VERSION "STEPFOC V109"

NS_ :

BS_:

BU_: Host Driver0 Driver1 Driver2 Driver3 Driver4 Driver5 Driver6 Driver7 Driver8 Driver9 Driver10 Driver11 Driver12 Driver13

BO_ 960 Respond_data_hall_N7: 4 Driver7
 SG_ position : 7|24@0- (1,0) [-8388608|8388607] "" Host
 SG_ HALL_trigger : 31|1@0+ (1,0) [0|1] "" Host
 SG_ additional_pin2 : 30|1@0+ (1,0) [0|1] "" Host
 SG_ hall_index : 29|1@0+ (1,0) [0|1] "" Host

BO_ 961 Respond_data_hall_N7_Fault: 4 Driver7
 SG_ position : 7|24@0- (1,0) [-8388608|8388607] "" Host
 SG_ HALL_trigger : 31|1@0+ (1,0) [0|1] "" Host
 SG_ additional_pin2 : 30|1@0+ (1,0) [0|1] "" Host
 SG_ hall_index : 29|1@0+ (1,0) [0|1] "" Host

BO_ 928 Send_PD_Gains_N7: 8 Host
 SG_ KP : 7|32@0+ (1,0) [-3.402823466e+38|3.402823466e+38] "" Driver7
 SG_ KD : 39|32@0+ (1,0) [-3.402823466e+38|3.402823466e+38] "" Driver7

BO_ 930 Send_Current_Gains_N7: 8 Host
 SG_ Kp_iq : 7|32@0+ (1,0) [-3.402823466e+38|3.402823466e+38] "" Driver7
 SG_ Ki_iq : 39|32@0+ (1,0) [-3.402823466e+38|3.402823466e+38] "" Driver7

BO_ 932 Send_Velocity_Gains_N7: 8 Host
 SG_ Kpv : 7|32@0+ (1,0) [-3.402823466e+38|3.402823466e+38] "" Driver7
 SG_ Kiv : 39|32@0+ (1,0) [-3.402823466e+38|3.402823466e+38] "" Driver7

BO_ 934 Send_Position_Gains_N7: 4 Host
 SG_ Kpp : 7|32@0+ (1,0) [-3.402823466e+38|3.402823466e+38] "" Driver7

BO_ 936 Send_Limits_N7: 8 Host
 SG_ Speed_limit : 7|32@0+ (1,0) [-3.402823466e+38|3.402823466e+38] "" Driver7
 SG_ Current_limit : 39|32@0+ (1,0) [-3.402823466e+38|3.402823466e+38] "" Driver7

BO_ 940 Send_Kt_N7: 4 Host
 SG_ Kt : 7|32@0+ (1,0) [-3.402823466e+38|3.402823466e+38] "" Driver7

BO_ 964 Send_Voltage_Limit_N7: 4 Host
 SG_ Voltage_limit : 7|32@0- (1,0) [-2147483648|2147483647] "" Driver7

BO_ 916 Send_Respond_Ping_N7: 0 Driver7

BO_ 917 Send_Respond_Ping_N7_Fault: 0 Driver7

BO_ 942 Send_Respond_Temperature_N7: 2 Driver7
 SG_ temperature : 7|16@0- (1,0) [-32768|32767] "" Host

BO_ 943 Send_Respond_Temperatur_N7_Fault: 2 Driver7
 SG_ temperature : 7|16@0- (1,0) [-32768|32767] "" Host

BO_ 944 Send_Respond_Voltage_N7: 2 Driver7
 SG_ voltage : 7|16@0+ (1,0) [0|65535] "" Host

BO_ 945 Send_Respond_Voltage_N7_Fault: 2 Driver7
 SG_ voltage : 7|16@0+ (1,0) [0|65535] "" Host

BO_ 946 Send_Respond_Device_Info_N7: 7 Driver7
 SG_ HARDWARE_VERSION : 7|8@0+ (1,0) [0|255] "" Host
 SG_ BATCH_DATE : 15|8@0+ (1,0) [0|255] "" Host
 SG_ SOFTWARE_VERSION : 23|8@0+ (1,0) [0|255] "" Host
 SG_ SERIAL_NUMBER : 31|32@0+ (1,0) [0|4294967295] "" Host

BO_ 947 Send_Respond_Device_Inf_N7_Fault: 7 Driver7
 SG_ HARDWARE_VERSION : 7|8@0+ (1,0) [0|255] "" Host
 SG_ BATCH_DATE : 15|8@0+ (1,0) [0|255] "" Host
 SG_ SOFTWARE_VERSION : 23|8@0+ (1,0) [0|255] "" Host
 SG_ SERIAL_NUMBER : 31|32@0+ (1,0) [0|4294967295] "" Host

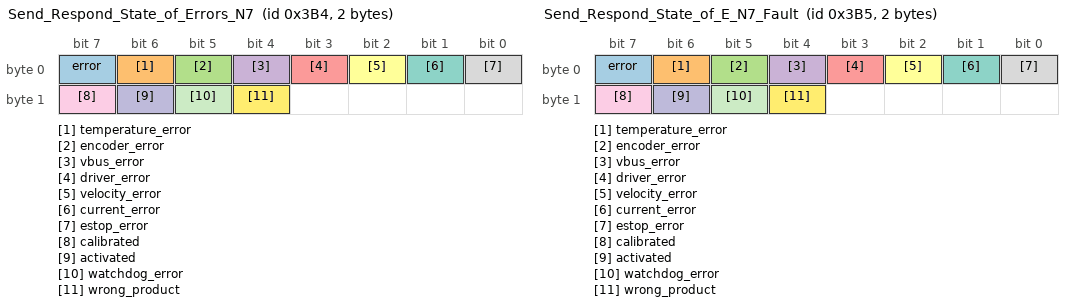
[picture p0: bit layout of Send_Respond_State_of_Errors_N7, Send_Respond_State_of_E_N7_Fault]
BO_ 948 Send_Respond_State_of_Errors_N7: 2 Driver7
 SG_ error : 7|1@0+ (1,0) [0|1] "" Host
 SG_ temperature_error : 6|1@0+ (1,0) [0|1] "" Host
 SG_ encoder_error : 5|1@0+ (1,0) [0|1] "" Host
 SG_ vbus_error : 4|1@0+ (1,0) [0|1] "" Host
 SG_ driver_error : 3|1@0+ (1,0) [0|1] "" Host
 SG_ velocity_error : 2|1@0+ (1,0) [0|1] "" Host
 SG_ current_error : 1|1@0+ (1,0) [0|1] "" Host
 SG_ estop_error : 0|1@0+ (1,0) [0|1] "" Host
 SG_ calibrated : 15|1@0+ (1,0) [0|1] "" Host
 SG_ activated : 14|1@0+ (1,0) [0|1] "" Host
 SG_ watchdog_error : 13|1@0+ (1,0) [0|1] "" Host
 SG_ wrong_product : 12|1@0+ (1,0) [0|1] "" Host

BO_ 949 Send_Respond_State_of_E_N7_Fault: 2 Driver7
 SG_ error : 7|1@0+ (1,0) [0|1] "" Host
 SG_ temperature_error : 6|1@0+ (1,0) [0|1] "" Host
 SG_ encoder_error : 5|1@0+ (1,0) [0|1] "" Host
 SG_ vbus_error : 4|1@0+ (1,0) [0|1] "" Host
 SG_ driver_error : 3|1@0+ (1,0) [0|1] "" Host
 SG_ velocity_error : 2|1@0+ (1,0) [0|1] "" Host
 SG_ current_error : 1|1@0+ (1,0) [0|1] "" Host
 SG_ estop_error : 0|1@0+ (1,0) [0|1] "" Host
 SG_ calibrated : 15|1@0+ (1,0) [0|1] "" Host
 SG_ activated : 14|1@0+ (1,0) [0|1] "" Host
 SG_ watchdog_error : 13|1@0+ (1,0) [0|1] "" Host
 SG_ wrong_product : 12|1@0+ (1,0) [0|1] "" Host

BO_ 950 Send_Respond_Iq_data_N7: 2 Driver7
 SG_ current : 7|16@0- (1,0) [-32768|32767] "" Host

BO_ 951 Send_Respond_Iq_data_N7_Fault: 2 Driver7
 SG_ current : 7|16@0- (1,0) [-32768|32767] "" Host

BO_ 952 Send_Respond_Encoder_data_N7: 8 Driver7
 SG_ position : 7|32@0- (1,0) [-2147483648|2147483647] "" Host
 SG_ speed : 39|32@0- (1,0) [-2147483648|2147483647] "" Host

BO_ 953 Send_Respond_Encoder_da_N7_Fault: 8 Driver7
 SG_ position : 7|32@0- (1,0) [-2147483648|2147483647] "" Host
 SG_ speed : 39|32@0- (1,0) [-2147483648|2147483647] "" Host

BO_ 962 Send_Respond_Kt_N7: 4 Driver7
 SG_ Kt : 7|32@0+ (1,0) [-3.402823466e+38|3.402823466e+38] "" Host

BO_ 963 Send_Respond_Kt_N7_Fault: 4 Driver7
 SG_ Kt : 7|32@0+ (1,0) [-3.402823466e+38|3.402823466e+38] "" Host

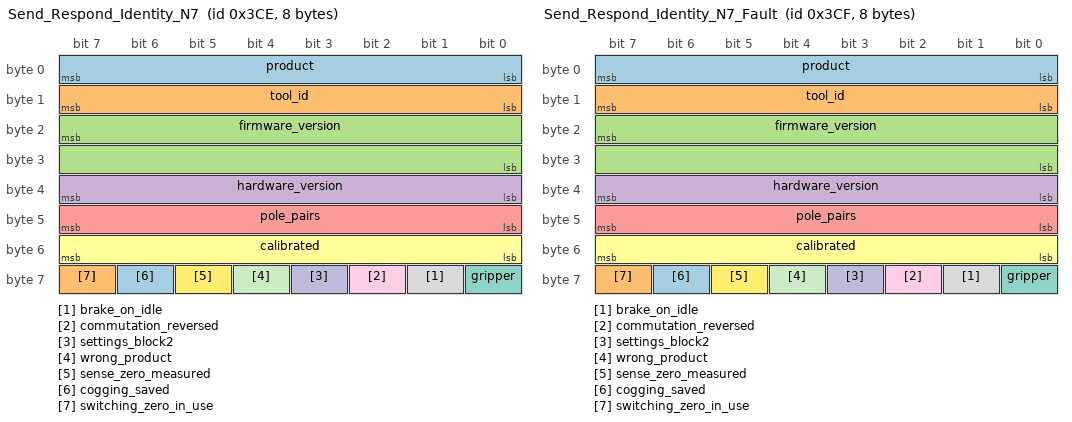
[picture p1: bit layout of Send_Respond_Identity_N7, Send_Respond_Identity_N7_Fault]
BO_ 974 Send_Respond_Identity_N7: 8 Driver7
 SG_ product : 7|8@0+ (1,0) [0|255] "" Host
 SG_ tool_id : 15|8@0+ (1,0) [0|255] "" Host
 SG_ firmware_version : 23|16@0+ (1,0) [0|65535] "" Host
 SG_ hardware_version : 39|8@0+ (1,0) [0|255] "" Host
 SG_ pole_pairs : 47|8@0+ (1,0) [0|255] "" Host
 SG_ calibrated : 55|8@0+ (1,0) [0|255] "" Host
 SG_ gripper : 56|1@0+ (1,0) [0|1] "" Host
 SG_ brake_on_idle : 57|1@0+ (1,0) [0|1] "" Host
 SG_ commutation_reversed : 58|1@0+ (1,0) [0|1] "" Host
 SG_ settings_block2 : 59|1@0+ (1,0) [0|1] "" Host
 SG_ wrong_product : 60|1@0+ (1,0) [0|1] "" Host
 SG_ sense_zero_measured : 61|1@0+ (1,0) [0|1] "" Host
 SG_ cogging_saved : 62|1@0+ (1,0) [0|1] "" Host
 SG_ switching_zero_in_use : 63|1@0+ (1,0) [0|1] "" Host

BO_ 975 Send_Respond_Identity_N7_Fault: 8 Driver7
 SG_ product : 7|8@0+ (1,0) [0|255] "" Host
 SG_ tool_id : 15|8@0+ (1,0) [0|255] "" Host
 SG_ firmware_version : 23|16@0+ (1,0) [0|65535] "" Host
 SG_ hardware_version : 39|8@0+ (1,0) [0|255] "" Host
 SG_ pole_pairs : 47|8@0+ (1,0) [0|255] "" Host
 SG_ calibrated : 55|8@0+ (1,0) [0|255] "" Host
 SG_ gripper : 56|1@0+ (1,0) [0|1] "" Host
 SG_ brake_on_idle : 57|1@0+ (1,0) [0|1] "" Host
 SG_ commutation_reversed : 58|1@0+ (1,0) [0|1] "" Host
 SG_ settings_block2 : 59|1@0+ (1,0) [0|1] "" Host
 SG_ wrong_product : 60|1@0+ (1,0) [0|1] "" Host
 SG_ sense_zero_measured : 61|1@0+ (1,0) [0|1] "" Host
 SG_ cogging_saved : 62|1@0+ (1,0) [0|1] "" Host
 SG_ switching_zero_in_use : 63|1@0+ (1,0) [0|1] "" Host

BO_ 976 Send_Respond_Telemetry_N7: 8 Driver7
 SG_ temperature : 7|16@0- (1,0) [-32768|32767] "" Host
 SG_ voltage : 23|16@0- (1,0) [-32768|32767] "" Host
 SG_ errors_1 : 39|8@0+ (1,0) [0|255] "" Host
 SG_ errors_2 : 47|8@0+ (1,0) [0|255] "" Host
 SG_ current : 55|16@0- (1,0) [-32768|32767] "" Host

BO_ 977 Send_Respond_Telemetry_N7_Fault: 8 Driver7
 SG_ temperature : 7|16@0- (1,0) [-32768|32767] "" Host
 SG_ voltage : 23|16@0- (1,0) [-32768|32767] "" Host
 SG_ errors_1 : 39|8@0+ (1,0) [0|255] "" Host
 SG_ errors_2 : 47|8@0+ (1,0) [0|255] "" Host
 SG_ current : 55|16@0- (1,0) [-32768|32767] "" Host

BO_ 914 Respond_Heartbeat_N7: 0 Driver7

BO_ 915 Respond_Heartbeat_N7_Fault: 0 Driver7

BO_ 918 Send_CAN_ID_N7: 1 Host
 SG_ ID : 7|8@0+ (1,0) [0|255] "" Driver7

BO_ 896 Send_ESTOP_N7: 0 Host

BO_ 920 Send_Idle_N7: 0 Host

BO_ 922 Send_Save_config_N7: 0 Host

BO_ 924 Send_Reset_N7: 0 Host

BO_ 898 Send_Clear_Error_N7: 0 Host

BO_ 926 Send_Watchdog_N7: 5 Host
 SG_ Time : 7|32@0+ (1,0) [0|4294967295] "" Driver7
 SG_ Action : 39|8@0+ (1,0) [0|255] "" Driver7

BO_ 956 Send_Heartbeat_Setup_N7: 4 Host
 SG_ Interval : 7|32@0+ (1,0) [0|4294967295] "" Driver7

BO_ 966 Send_Settings_N7: 2 Host
 SG_ Mask : 7|8@0+ (1,0) [0|255] "" Driver7
 SG_ Value : 15|8@0+ (1,0) [0|255] "" Driver7

BO_ 968 Send_Parameter_N7: 5 Host
 SG_ Parameter : 7|8@0+ (1,0) [0|255] "" Driver7
 SG_ Value : 15|32@0- (1,0) [-2147483648|2147483647] "" Driver7

BO_ 970 Send_Get_Parameter_N7: 1 Host
 SG_ Parameter : 7|8@0+ (1,0) [0|255] "" Driver7

BO_ 972 Respond_Parameter_N7: 5 Driver7
 SG_ parameter : 7|8@0+ (1,0) [0|255] "" Host
 SG_ value : 15|32@0- (1,0) [-2147483648|2147483647] "" Host

BO_ 973 Respond_Parameter_N7_Fault: 5 Driver7
 SG_ parameter : 7|8@0+ (1,0) [0|255] "" Host
 SG_ value : 15|32@0- (1,0) [-2147483648|2147483647] "" Host

BO_ 978 Send_Buffer_Read_N7: 5 Host
 SG_ Kind : 7|8@0+ (1,0) [0|255] "" Driver7
 SG_ First : 15|16@0+ (1,0) [0|65535] "" Driver7
 SG_ Count : 31|16@0+ (1,0) [0|65535] "" Driver7

BO_ 980 Respond_Buffer_Data_N7: 8 Driver7
 SG_ header : 7|16@0+ (1,0) [0|65535] "" Host
 SG_ word_a : 23|16@0- (1,0) [-32768|32767] "" Host
 SG_ word_b : 39|16@0- (1,0) [-32768|32767] "" Host
 SG_ word_c : 55|16@0- (1,0) [-32768|32767] "" Host

BO_ 981 Respond_Buffer_Data_N7_Fault: 8 Driver7
 SG_ header : 7|16@0+ (1,0) [0|65535] "" Host
 SG_ word_a : 23|16@0- (1,0) [-32768|32767] "" Host
 SG_ word_b : 39|16@0- (1,0) [-32768|32767] "" Host
 SG_ word_c : 55|16@0- (1,0) [-32768|32767] "" Host

BO_ 982 Send_Buffer_Write_N7: 8 Host
 SG_ Header : 7|16@0+ (1,0) [0|65535] "" Driver7
 SG_ Word_A : 23|16@0- (1,0) [-32768|32767] "" Driver7
 SG_ Word_B : 39|16@0- (1,0) [-32768|32767] "" Driver7
 SG_ Word_C : 55|16@0- (1,0) [-32768|32767] "" Driver7

BO_ 984 Send_Sound_N7: 8 Host
 SG_ Operation : 7|8@0+ (1,0) [0|255] "" Driver7
 SG_ Channel : 15|8@0+ (1,0) [0|255] "" Driver7
 SG_ A : 23|16@0+ (1,0) [0|65535] "" Driver7
 SG_ B : 39|16@0+ (1,0) [0|65535] "" Driver7
 SG_ C : 55|16@0+ (1,0) [0|65535] "" Driver7

BO_ 986 Send_Sound_Samples_N7: 8 Host
 SG_ Sample_1 : 7|8@0- (1,0) [-128|127] "" Driver7
 SG_ Sample_2 : 15|8@0- (1,0) [-128|127] "" Driver7
 SG_ Sample_3 : 23|8@0- (1,0) [-128|127] "" Driver7
 SG_ Sample_4 : 31|8@0- (1,0) [-128|127] "" Driver7
 SG_ Sample_5 : 39|8@0- (1,0) [-128|127] "" Driver7
 SG_ Sample_6 : 47|8@0- (1,0) [-128|127] "" Driver7
 SG_ Sample_7 : 55|8@0- (1,0) [-128|127] "" Driver7
 SG_ Sample_8 : 63|8@0- (1,0) [-128|127] "" Driver7

BO_ 1018 Send_gripper_data_pack_N7: 5 Host
 SG_ Position : 7|8@0+ (1,0) [0|255] "" Driver7
 SG_ Speed : 15|8@0+ (1,0) [0|255] "" Driver7
 SG_ Current : 23|16@0- (1,0) [-32768|32767] "" Driver7
 SG_ Activate : 39|1@0+ (1,0) [0|1] "" Driver7
 SG_ Action : 38|1@0+ (1,0) [0|1] "" Driver7
 SG_ E_stop : 37|1@0+ (1,0) [0|1] "" Driver7
 SG_ Release_direction : 36|1@0+ (1,0) [0|1] "" Driver7

BO_ 1020 Send_gripper_calibrate_N7: 0 Host

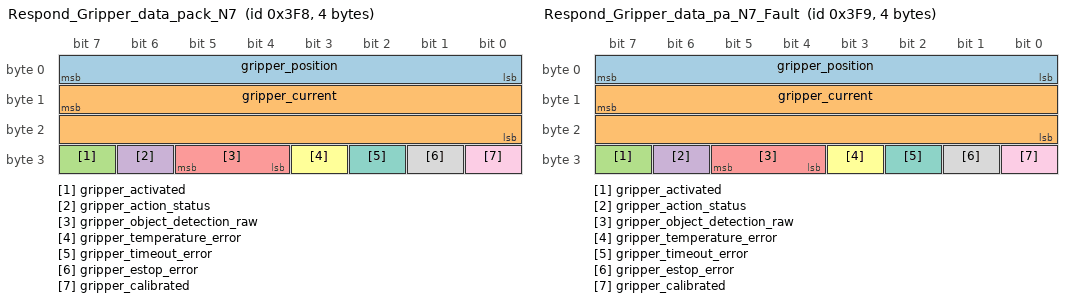
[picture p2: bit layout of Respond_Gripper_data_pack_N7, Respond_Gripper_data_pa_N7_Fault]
BO_ 1016 Respond_Gripper_data_pack_N7: 4 Driver7
 SG_ gripper_position : 7|8@0+ (1,0) [0|255] "" Host
 SG_ gripper_current : 15|16@0- (1,0) [-32768|32767] "" Host
 SG_ gripper_activated : 31|1@0+ (1,0) [0|1] "" Host
 SG_ gripper_action_status : 30|1@0+ (1,0) [0|1] "" Host
 SG_ gripper_object_detection_raw : 29|2@0+ (1,0) [0|3] "" Host
 SG_ gripper_temperature_error : 27|1@0+ (1,0) [0|1] "" Host
 SG_ gripper_timeout_error : 26|1@0+ (1,0) [0|1] "" Host
 SG_ gripper_estop_error : 25|1@0+ (1,0) [0|1] "" Host
 SG_ gripper_calibrated : 24|1@0+ (1,0) [0|1] "" Host

BO_ 1017 Respond_Gripper_data_pa_N7_Fault: 4 Driver7
 SG_ gripper_position : 7|8@0+ (1,0) [0|255] "" Host
 SG_ gripper_current : 15|16@0- (1,0) [-32768|32767] "" Host
 SG_ gripper_activated : 31|1@0+ (1,0) [0|1] "" Host
 SG_ gripper_action_status : 30|1@0+ (1,0) [0|1] "" Host
 SG_ gripper_object_detection_raw : 29|2@0+ (1,0) [0|3] "" Host
 SG_ gripper_temperature_error : 27|1@0+ (1,0) [0|1] "" Host
 SG_ gripper_timeout_error : 26|1@0+ (1,0) [0|1] "" Host
 SG_ gripper_estop_error : 25|1@0+ (1,0) [0|1] "" Host
 SG_ gripper_calibrated : 24|1@0+ (1,0) [0|1] "" Host

BO_ 1028 Send_data_pack_1_N8: 5 Host
 SG_ Speed_setpoint : 7|24@0- (1,0) [-8388608|8388607] "" Driver8
 SG_ Current_feedforward : 31|16@0- (1,0) [-32768|32767] "" Driver8

BO_ 1032 Send_data_pack_PD_N8: 8 Host
 SG_ Position_setpoint : 7|24@0- (1,0) [-8388608|8388607] "" Driver8
 SG_ Speed_setpoint : 31|24@0- (1,0) [-8388608|8388607] "" Driver8
 SG_ Current_feedforward : 55|16@0- (1,0) [-32768|32767] "" Driver8

BO_ 1086 Send_data_pack_HALL_N8: 4 Host
 SG_ Speed : 7|24@0- (1,0) [-8388608|8388607] "" Driver8
 SG_ Trigger : 31|8@0+ (1,0) [0|255] "" Driver8

BO_ 1030 Respond_data_pack_1_N8: 8 Driver8
 SG_ position : 7|24@0- (1,0) [-8388608|8388607] "" Host
 SG_ speed : 31|24@0- (1,0) [-8388608|8388607] "" Host
 SG_ current : 55|16@0- (1,0) [-32768|32767] "" Host

BO_ 1031 Respond_data_pack_1_N8_Fault: 8 Driver8
 SG_ position : 7|24@0- (1,0) [-8388608|8388607] "" Host
 SG_ speed : 31|24@0- (1,0) [-8388608|8388607] "" Host
 SG_ current : 55|16@0- (1,0) [-32768|32767] "" Host

BO_ 1088 Respond_data_hall_N8: 4 Driver8
 SG_ position : 7|24@0- (1,0) [-8388608|8388607] "" Host
 SG_ HALL_trigger : 31|1@0+ (1,0) [0|1] "" Host
 SG_ additional_pin2 : 30|1@0+ (1,0) [0|1] "" Host
 SG_ hall_index : 29|1@0+ (1,0) [0|1] "" Host

BO_ 1089 Respond_data_hall_N8_Fault: 4 Driver8
 SG_ position : 7|24@0- (1,0) [-8388608|8388607] "" Host
 SG_ HALL_trigger : 31|1@0+ (1,0) [0|1] "" Host
 SG_ additional_pin2 : 30|1@0+ (1,0) [0|1] "" Host
 SG_ hall_index : 29|1@0+ (1,0) [0|1] "" Host

BO_ 1056 Send_PD_Gains_N8: 8 Host
 SG_ KP : 7|32@0+ (1,0) [-3.402823466e+38|3.402823466e+38] "" Driver8
 SG_ KD : 39|32@0+ (1,0) [-3.402823466e+38|3.402823466e+38] "" Driver8

BO_ 1058 Send_Current_Gains_N8: 8 Host
 SG_ Kp_iq : 7|32@0+ (1,0) [-3.402823466e+38|3.402823466e+38] "" Driver8
 SG_ Ki_iq : 39|32@0+ (1,0) [-3.402823466e+38|3.402823466e+38] "" Driver8

BO_ 1060 Send_Velocity_Gains_N8: 8 Host
 SG_ Kpv : 7|32@0+ (1,0) [-3.402823466e+38|3.402823466e+38] "" Driver8
 SG_ Kiv : 39|32@0+ (1,0) [-3.402823466e+38|3.402823466e+38] "" Driver8

BO_ 1062 Send_Position_Gains_N8: 4 Host
 SG_ Kpp : 7|32@0+ (1,0) [-3.402823466e+38|3.402823466e+38] "" Driver8

BO_ 1064 Send_Limits_N8: 8 Host
 SG_ Speed_limit : 7|32@0+ (1,0) [-3.402823466e+38|3.402823466e+38] "" Driver8
 SG_ Current_limit : 39|32@0+ (1,0) [-3.402823466e+38|3.402823466e+38] "" Driver8

BO_ 1068 Send_Kt_N8: 4 Host
 SG_ Kt : 7|32@0+ (1,0) [-3.402823466e+38|3.402823466e+38] "" Driver8

BO_ 1092 Send_Voltage_Limit_N8: 4 Host
 SG_ Voltage_limit : 7|32@0- (1,0) [-2147483648|2147483647] "" Driver8

BO_ 1044 Send_Respond_Ping_N8: 0 Driver8

BO_ 1045 Send_Respond_Ping_N8_Fault: 0 Driver8

BO_ 1070 Send_Respond_Temperature_N8: 2 Driver8
 SG_ temperature : 7|16@0- (1,0) [-32768|32767] "" Host

BO_ 1071 Send_Respond_Temperatur_N8_Fault: 2 Driver8
 SG_ temperature : 7|16@0- (1,0) [-32768|32767] "" Host

BO_ 1072 Send_Respond_Voltage_N8: 2 Driver8
 SG_ voltage : 7|16@0+ (1,0) [0|65535] "" Host

BO_ 1073 Send_Respond_Voltage_N8_Fault: 2 Driver8
 SG_ voltage : 7|16@0+ (1,0) [0|65535] "" Host

BO_ 1074 Send_Respond_Device_Info_N8: 7 Driver8
 SG_ HARDWARE_VERSION : 7|8@0+ (1,0) [0|255] "" Host
 SG_ BATCH_DATE : 15|8@0+ (1,0) [0|255] "" Host
 SG_ SOFTWARE_VERSION : 23|8@0+ (1,0) [0|255] "" Host
 SG_ SERIAL_NUMBER : 31|32@0+ (1,0) [0|4294967295] "" Host

BO_ 1075 Send_Respond_Device_Inf_N8_Fault: 7 Driver8
 SG_ HARDWARE_VERSION : 7|8@0+ (1,0) [0|255] "" Host
 SG_ BATCH_DATE : 15|8@0+ (1,0) [0|255] "" Host
 SG_ SOFTWARE_VERSION : 23|8@0+ (1,0) [0|255] "" Host
 SG_ SERIAL_NUMBER : 31|32@0+ (1,0) [0|4294967295] "" Host

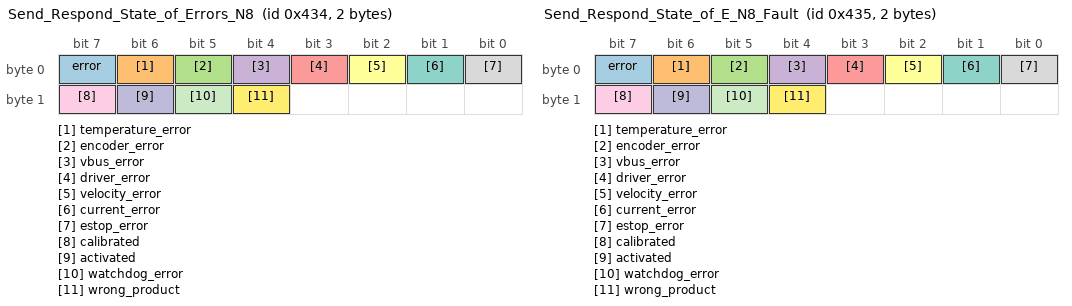
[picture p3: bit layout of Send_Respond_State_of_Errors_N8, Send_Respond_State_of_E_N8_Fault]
BO_ 1076 Send_Respond_State_of_Errors_N8: 2 Driver8
 SG_ error : 7|1@0+ (1,0) [0|1] "" Host
 SG_ temperature_error : 6|1@0+ (1,0) [0|1] "" Host
 SG_ encoder_error : 5|1@0+ (1,0) [0|1] "" Host
 SG_ vbus_error : 4|1@0+ (1,0) [0|1] "" Host
 SG_ driver_error : 3|1@0+ (1,0) [0|1] "" Host
 SG_ velocity_error : 2|1@0+ (1,0) [0|1] "" Host
 SG_ current_error : 1|1@0+ (1,0) [0|1] "" Host
 SG_ estop_error : 0|1@0+ (1,0) [0|1] "" Host
 SG_ calibrated : 15|1@0+ (1,0) [0|1] "" Host
 SG_ activated : 14|1@0+ (1,0) [0|1] "" Host
 SG_ watchdog_error : 13|1@0+ (1,0) [0|1] "" Host
 SG_ wrong_product : 12|1@0+ (1,0) [0|1] "" Host

BO_ 1077 Send_Respond_State_of_E_N8_Fault: 2 Driver8
 SG_ error : 7|1@0+ (1,0) [0|1] "" Host
 SG_ temperature_error : 6|1@0+ (1,0) [0|1] "" Host
 SG_ encoder_error : 5|1@0+ (1,0) [0|1] "" Host
 SG_ vbus_error : 4|1@0+ (1,0) [0|1] "" Host
 SG_ driver_error : 3|1@0+ (1,0) [0|1] "" Host
 SG_ velocity_error : 2|1@0+ (1,0) [0|1] "" Host
 SG_ current_error : 1|1@0+ (1,0) [0|1] "" Host
 SG_ estop_error : 0|1@0+ (1,0) [0|1] "" Host
 SG_ calibrated : 15|1@0+ (1,0) [0|1] "" Host
 SG_ activated : 14|1@0+ (1,0) [0|1] "" Host
 SG_ watchdog_error : 13|1@0+ (1,0) [0|1] "" Host
 SG_ wrong_product : 12|1@0+ (1,0) [0|1] "" Host

BO_ 1078 Send_Respond_Iq_data_N8: 2 Driver8
 SG_ current : 7|16@0- (1,0) [-32768|32767] "" Host

BO_ 1079 Send_Respond_Iq_data_N8_Fault: 2 Driver8
 SG_ current : 7|16@0- (1,0) [-32768|32767] "" Host

BO_ 1080 Send_Respond_Encoder_data_N8: 8 Driver8
 SG_ position : 7|32@0- (1,0) [-2147483648|2147483647] "" Host
 SG_ speed : 39|32@0- (1,0) [-2147483648|2147483647] "" Host

BO_ 1081 Send_Respond_Encoder_da_N8_Fault: 8 Driver8
 SG_ position : 7|32@0- (1,0) [-2147483648|2147483647] "" Host
 SG_ speed : 39|32@0- (1,0) [-2147483648|2147483647] "" Host

BO_ 1090 Send_Respond_Kt_N8: 4 Driver8
 SG_ Kt : 7|32@0+ (1,0) [-3.402823466e+38|3.402823466e+38] "" Host

BO_ 1091 Send_Respond_Kt_N8_Fault: 4 Driver8
 SG_ Kt : 7|32@0+ (1,0) [-3.402823466e+38|3.402823466e+38] "" Host

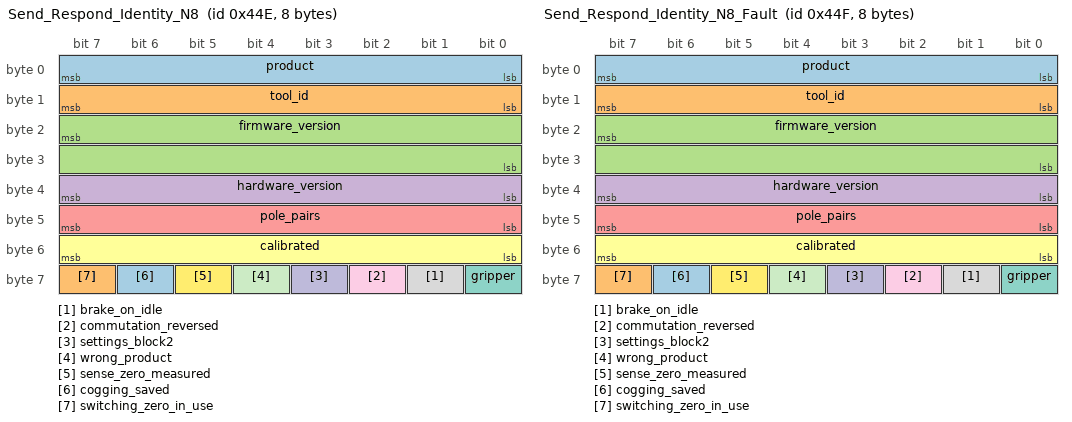
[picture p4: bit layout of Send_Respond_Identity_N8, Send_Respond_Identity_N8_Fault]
BO_ 1102 Send_Respond_Identity_N8: 8 Driver8
 SG_ product : 7|8@0+ (1,0) [0|255] "" Host
 SG_ tool_id : 15|8@0+ (1,0) [0|255] "" Host
 SG_ firmware_version : 23|16@0+ (1,0) [0|65535] "" Host
 SG_ hardware_version : 39|8@0+ (1,0) [0|255] "" Host
 SG_ pole_pairs : 47|8@0+ (1,0) [0|255] "" Host
 SG_ calibrated : 55|8@0+ (1,0) [0|255] "" Host
 SG_ gripper : 56|1@0+ (1,0) [0|1] "" Host
 SG_ brake_on_idle : 57|1@0+ (1,0) [0|1] "" Host
 SG_ commutation_reversed : 58|1@0+ (1,0) [0|1] "" Host
 SG_ settings_block2 : 59|1@0+ (1,0) [0|1] "" Host
 SG_ wrong_product : 60|1@0+ (1,0) [0|1] "" Host
 SG_ sense_zero_measured : 61|1@0+ (1,0) [0|1] "" Host
 SG_ cogging_saved : 62|1@0+ (1,0) [0|1] "" Host
 SG_ switching_zero_in_use : 63|1@0+ (1,0) [0|1] "" Host

BO_ 1103 Send_Respond_Identity_N8_Fault: 8 Driver8
 SG_ product : 7|8@0+ (1,0) [0|255] "" Host
 SG_ tool_id : 15|8@0+ (1,0) [0|255] "" Host
 SG_ firmware_version : 23|16@0+ (1,0) [0|65535] "" Host
 SG_ hardware_version : 39|8@0+ (1,0) [0|255] "" Host
 SG_ pole_pairs : 47|8@0+ (1,0) [0|255] "" Host
 SG_ calibrated : 55|8@0+ (1,0) [0|255] "" Host
 SG_ gripper : 56|1@0+ (1,0) [0|1] "" Host
 SG_ brake_on_idle : 57|1@0+ (1,0) [0|1] "" Host
 SG_ commutation_reversed : 58|1@0+ (1,0) [0|1] "" Host
 SG_ settings_block2 : 59|1@0+ (1,0) [0|1] "" Host
 SG_ wrong_product : 60|1@0+ (1,0) [0|1] "" Host
 SG_ sense_zero_measured : 61|1@0+ (1,0) [0|1] "" Host
 SG_ cogging_saved : 62|1@0+ (1,0) [0|1] "" Host
 SG_ switching_zero_in_use : 63|1@0+ (1,0) [0|1] "" Host

BO_ 1104 Send_Respond_Telemetry_N8: 8 Driver8
 SG_ temperature : 7|16@0- (1,0) [-32768|32767] "" Host
 SG_ voltage : 23|16@0- (1,0) [-32768|32767] "" Host
 SG_ errors_1 : 39|8@0+ (1,0) [0|255] "" Host
 SG_ errors_2 : 47|8@0+ (1,0) [0|255] "" Host
 SG_ current : 55|16@0- (1,0) [-32768|32767] "" Host

BO_ 1105 Send_Respond_Telemetry_N8_Fault: 8 Driver8
 SG_ temperature : 7|16@0- (1,0) [-32768|32767] "" Host
 SG_ voltage : 23|16@0- (1,0) [-32768|32767] "" Host
 SG_ errors_1 : 39|8@0+ (1,0) [0|255] "" Host
 SG_ errors_2 : 47|8@0+ (1,0) [0|255] "" Host
 SG_ current : 55|16@0- (1,0) [-32768|32767] "" Host

BO_ 1042 Respond_Heartbeat_N8: 0 Driver8

BO_ 1043 Respond_Heartbeat_N8_Fault: 0 Driver8

BO_ 1046 Send_CAN_ID_N8: 1 Host
 SG_ ID : 7|8@0+ (1,0) [0|255] "" Driver8

BO_ 1024 Send_ESTOP_N8: 0 Host

BO_ 1048 Send_Idle_N8: 0 Host

BO_ 1050 Send_Save_config_N8: 0 Host

BO_ 1052 Send_Reset_N8: 0 Host

BO_ 1026 Send_Clear_Error_N8: 0 Host

BO_ 1054 Send_Watchdog_N8: 5 Host
 SG_ Time : 7|32@0+ (1,0) [0|4294967295] "" Driver8
 SG_ Action : 39|8@0+ (1,0) [0|255] "" Driver8

BO_ 1084 Send_Heartbeat_Setup_N8: 4 Host
 SG_ Interval : 7|32@0+ (1,0) [0|4294967295] "" Driver8

BO_ 1094 Send_Settings_N8: 2 Host
 SG_ Mask : 7|8@0+ (1,0) [0|255] "" Driver8
 SG_ Value : 15|8@0+ (1,0) [0|255] "" Driver8

BO_ 1096 Send_Parameter_N8: 5 Host
 SG_ Parameter : 7|8@0+ (1,0) [0|255] "" Driver8
 SG_ Value : 15|32@0- (1,0) [-2147483648|2147483647] "" Driver8

BO_ 1098 Send_Get_Parameter_N8: 1 Host
 SG_ Parameter : 7|8@0+ (1,0) [0|255] "" Driver8

BO_ 1100 Respond_Parameter_N8: 5 Driver8
 SG_ parameter : 7|8@0+ (1,0) [0|255] "" Host
 SG_ value : 15|32@0- (1,0) [-2147483648|2147483647] "" Host

BO_ 1101 Respond_Parameter_N8_Fault: 5 Driver8
 SG_ parameter : 7|8@0+ (1,0) [0|255] "" Host
 SG_ value : 15|32@0- (1,0) [-2147483648|2147483647] "" Host

BO_ 1106 Send_Buffer_Read_N8: 5 Host
 SG_ Kind : 7|8@0+ (1,0) [0|255] "" Driver8
 SG_ First : 15|16@0+ (1,0) [0|65535] "" Driver8
 SG_ Count : 31|16@0+ (1,0) [0|65535] "" Driver8

BO_ 1108 Respond_Buffer_Data_N8: 8 Driver8
 SG_ header : 7|16@0+ (1,0) [0|65535] "" Host
 SG_ word_a : 23|16@0- (1,0) [-32768|32767] "" Host
 SG_ word_b : 39|16@0- (1,0) [-32768|32767] "" Host
 SG_ word_c : 55|16@0- (1,0) [-32768|32767] "" Host

BO_ 1109 Respond_Buffer_Data_N8_Fault: 8 Driver8
 SG_ header : 7|16@0+ (1,0) [0|65535] "" Host
 SG_ word_a : 23|16@0- (1,0) [-32768|32767] "" Host
 SG_ word_b : 39|16@0- (1,0) [-32768|32767] "" Host
 SG_ word_c : 55|16@0- (1,0) [-32768|32767] "" Host

BO_ 1110 Send_Buffer_Write_N8: 8 Host
 SG_ Header : 7|16@0+ (1,0) [0|65535] "" Driver8
 SG_ Word_A : 23|16@0- (1,0) [-32768|32767] "" Driver8
 SG_ Word_B : 39|16@0- (1,0) [-32768|32767] "" Driver8
 SG_ Word_C : 55|16@0- (1,0) [-32768|32767] "" Driver8

BO_ 1112 Send_Sound_N8: 8 Host
 SG_ Operation : 7|8@0+ (1,0) [0|255] "" Driver8
 SG_ Channel : 15|8@0+ (1,0) [0|255] "" Driver8
 SG_ A : 23|16@0+ (1,0) [0|65535] "" Driver8
 SG_ B : 39|16@0+ (1,0) [0|65535] "" Driver8
 SG_ C : 55|16@0+ (1,0) [0|65535] "" Driver8

BO_ 1114 Send_Sound_Samples_N8: 8 Host
 SG_ Sample_1 : 7|8@0- (1,0) [-128|127] "" Driver8
 SG_ Sample_2 : 15|8@0- (1,0) [-128|127] "" Driver8
 SG_ Sample_3 : 23|8@0- (1,0) [-128|127] "" Driver8
 SG_ Sample_4 : 31|8@0- (1,0) [-128|127] "" Driver8
 SG_ Sample_5 : 39|8@0- (1,0) [-128|127] "" Driver8
 SG_ Sample_6 : 47|8@0- (1,0) [-128|127] "" Driver8
 SG_ Sample_7 : 55|8@0- (1,0) [-128|127] "" Driver8
 SG_ Sample_8 : 63|8@0- (1,0) [-128|127] "" Driver8

BO_ 1146 Send_gripper_data_pack_N8: 5 Host
 SG_ Position : 7|8@0+ (1,0) [0|255] "" Driver8
 SG_ Speed : 15|8@0+ (1,0) [0|255] "" Driver8
 SG_ Current : 23|16@0- (1,0) [-32768|32767] "" Driver8
 SG_ Activate : 39|1@0+ (1,0) [0|1] "" Driver8
 SG_ Action : 38|1@0+ (1,0) [0|1] "" Driver8
 SG_ E_stop : 37|1@0+ (1,0) [0|1] "" Driver8
 SG_ Release_direction : 36|1@0+ (1,0) [0|1] "" Driver8

BO_ 1148 Send_gripper_calibrate_N8: 0 Host

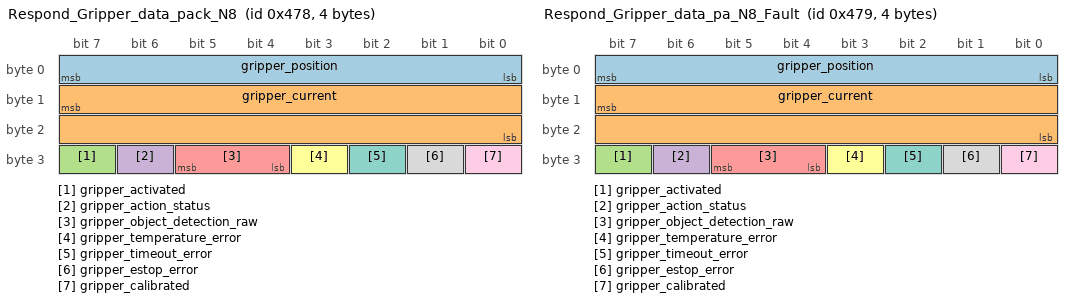
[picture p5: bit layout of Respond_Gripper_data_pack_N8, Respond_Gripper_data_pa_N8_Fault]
BO_ 1144 Respond_Gripper_data_pack_N8: 4 Driver8
 SG_ gripper_position : 7|8@0+ (1,0) [0|255] "" Host
 SG_ gripper_current : 15|16@0- (1,0) [-32768|32767] "" Host
 SG_ gripper_activated : 31|1@0+ (1,0) [0|1] "" Host
 SG_ gripper_action_status : 30|1@0+ (1,0) [0|1] "" Host
 SG_ gripper_object_detection_raw : 29|2@0+ (1,0) [0|3] "" Host
 SG_ gripper_temperature_error : 27|1@0+ (1,0) [0|1] "" Host
 SG_ gripper_timeout_error : 26|1@0+ (1,0) [0|1] "" Host
 SG_ gripper_estop_error : 25|1@0+ (1,0) [0|1] "" Host
 SG_ gripper_calibrated : 24|1@0+ (1,0) [0|1] "" Host

BO_ 1145 Respond_Gripper_data_pa_N8_Fault: 4 Driver8
 SG_ gripper_position : 7|8@0+ (1,0) [0|255] "" Host
 SG_ gripper_current : 15|16@0- (1,0) [-32768|32767] "" Host
 SG_ gripper_activated : 31|1@0+ (1,0) [0|1] "" Host
 SG_ gripper_action_status : 30|1@0+ (1,0) [0|1] "" Host
 SG_ gripper_object_detection_raw : 29|2@0+ (1,0) [0|3] "" Host
 SG_ gripper_temperature_error : 27|1@0+ (1,0) [0|1] "" Host
 SG_ gripper_timeout_error : 26|1@0+ (1,0) [0|1] "" Host
 SG_ gripper_estop_error : 25|1@0+ (1,0) [0|1] "" Host
 SG_ gripper_calibrated : 24|1@0+ (1,0) [0|1] "" Host

BO_ 1156 Send_data_pack_1_N9: 5 Host
 SG_ Speed_setpoint : 7|24@0- (1,0) [-8388608|8388607] "" Driver9
 SG_ Current_feedforward : 31|16@0- (1,0) [-32768|32767] "" Driver9

BO_ 1160 Send_data_pack_PD_N9: 8 Host
 SG_ Position_setpoint : 7|24@0- (1,0) [-8388608|8388607] "" Driver9
 SG_ Speed_setpoint : 31|24@0- (1,0) [-8388608|8388607] "" Driver9
 SG_ Current_feedforward : 55|16@0- (1,0) [-32768|32767] "" Driver9

BO_ 1214 Send_data_pack_HALL_N9: 4 Host
 SG_ Speed : 7|24@0- (1,0) [-8388608|8388607] "" Driver9
 SG_ Trigger : 31|8@0+ (1,0) [0|255] "" Driver9

BO_ 1158 Respond_data_pack_1_N9: 8 Driver9
 SG_ position : 7|24@0- (1,0) [-8388608|8388607] "" Host
 SG_ speed : 31|24@0- (1,0) [-8388608|8388607] "" Host
 SG_ current : 55|16@0- (1,0) [-32768|32767] "" Host

BO_ 1159 Respond_data_pack_1_N9_Fault: 8 Driver9
 SG_ position : 7|24@0- (1,0) [-8388608|8388607] "" Host
 SG_ speed : 31|24@0- (1,0) [-8388608|8388607] "" Host
 SG_ current : 55|16@0- (1,0) [-32768|32767] "" Host

BO_ 1216 Respond_data_hall_N9: 4 Driver9
 SG_ position : 7|24@0- (1,0) [-8388608|8388607] "" Host
 SG_ HALL_trigger : 31|1@0+ (1,0) [0|1] "" Host
 SG_ additional_pin2 : 30|1@0+ (1,0) [0|1] "" Host
 SG_ hall_index : 29|1@0+ (1,0) [0|1] "" Host

BO_ 1217 Respond_data_hall_N9_Fault: 4 Driver9
 SG_ position : 7|24@0- (1,0) [-8388608|8388607] "" Host
 SG_ HALL_trigger : 31|1@0+ (1,0) [0|1] "" Host
 SG_ additional_pin2 : 30|1@0+ (1,0) [0|1] "" Host
 SG_ hall_index : 29|1@0+ (1,0) [0|1] "" Host

BO_ 1184 Send_PD_Gains_N9: 8 Host
 SG_ KP : 7|32@0+ (1,0) [-3.402823466e+38|3.402823466e+38] "" Driver9
 SG_ KD : 39|32@0+ (1,0) [-3.402823466e+38|3.402823466e+38] "" Driver9

BO_ 1186 Send_Current_Gains_N9: 8 Host
 SG_ Kp_iq : 7|32@0+ (1,0) [-3.402823466e+38|3.402823466e+38] "" Driver9
 SG_ Ki_iq : 39|32@0+ (1,0) [-3.402823466e+38|3.402823466e+38] "" Driver9

BO_ 1188 Send_Velocity_Gains_N9: 8 Host
 SG_ Kpv : 7|32@0+ (1,0) [-3.402823466e+38|3.402823466e+38] "" Driver9
 SG_ Kiv : 39|32@0+ (1,0) [-3.402823466e+38|3.402823466e+38] "" Driver9

BO_ 1190 Send_Position_Gains_N9: 4 Host
 SG_ Kpp : 7|32@0+ (1,0) [-3.402823466e+38|3.402823466e+38] "" Driver9

BO_ 1192 Send_Limits_N9: 8 Host
 SG_ Speed_limit : 7|32@0+ (1,0) [-3.402823466e+38|3.402823466e+38] "" Driver9
 SG_ Current_limit : 39|32@0+ (1,0) [-3.402823466e+38|3.402823466e+38] "" Driver9

BO_ 1196 Send_Kt_N9: 4 Host
 SG_ Kt : 7|32@0+ (1,0) [-3.402823466e+38|3.402823466e+38] "" Driver9

BO_ 1220 Send_Voltage_Limit_N9: 4 Host
 SG_ Voltage_limit : 7|32@0- (1,0) [-2147483648|2147483647] "" Driver9

BO_ 1172 Send_Respond_Ping_N9: 0 Driver9

BO_ 1173 Send_Respond_Ping_N9_Fault: 0 Driver9

BO_ 1198 Send_Respond_Temperature_N9: 2 Driver9
 SG_ temperature : 7|16@0- (1,0) [-32768|32767] "" Host

BO_ 1199 Send_Respond_Temperatur_N9_Fault: 2 Driver9
 SG_ temperature : 7|16@0- (1,0) [-32768|32767] "" Host

BO_ 1200 Send_Respond_Voltage_N9: 2 Driver9
 SG_ voltage : 7|16@0+ (1,0) [0|65535] "" Host

BO_ 1201 Send_Respond_Voltage_N9_Fault: 2 Driver9
 SG_ voltage : 7|16@0+ (1,0) [0|65535] "" Host

BO_ 1202 Send_Respond_Device_Info_N9: 7 Driver9
 SG_ HARDWARE_VERSION : 7|8@0+ (1,0) [0|255] "" Host
 SG_ BATCH_DATE : 15|8@0+ (1,0) [0|255] "" Host
 SG_ SOFTWARE_VERSION : 23|8@0+ (1,0) [0|255] "" Host
 SG_ SERIAL_NUMBER : 31|32@0+ (1,0) [0|4294967295] "" Host

BO_ 1203 Send_Respond_Device_Inf_N9_Fault: 7 Driver9
 SG_ HARDWARE_VERSION : 7|8@0+ (1,0) [0|255] "" Host
 SG_ BATCH_DATE : 15|8@0+ (1,0) [0|255] "" Host
 SG_ SOFTWARE_VERSION : 23|8@0+ (1,0) [0|255] "" Host
 SG_ SERIAL_NUMBER : 31|32@0+ (1,0) [0|4294967295] "" Host

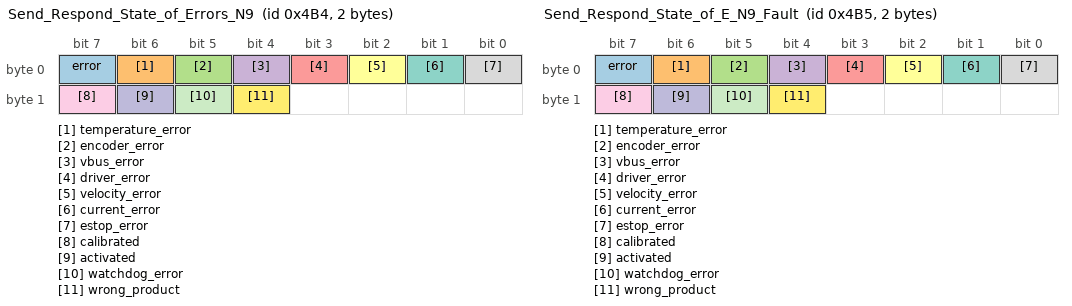
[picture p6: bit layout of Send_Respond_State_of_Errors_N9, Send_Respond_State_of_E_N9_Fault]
BO_ 1204 Send_Respond_State_of_Errors_N9: 2 Driver9
 SG_ error : 7|1@0+ (1,0) [0|1] "" Host
 SG_ temperature_error : 6|1@0+ (1,0) [0|1] "" Host
 SG_ encoder_error : 5|1@0+ (1,0) [0|1] "" Host
 SG_ vbus_error : 4|1@0+ (1,0) [0|1] "" Host
 SG_ driver_error : 3|1@0+ (1,0) [0|1] "" Host
 SG_ velocity_error : 2|1@0+ (1,0) [0|1] "" Host
 SG_ current_error : 1|1@0+ (1,0) [0|1] "" Host
 SG_ estop_error : 0|1@0+ (1,0) [0|1] "" Host
 SG_ calibrated : 15|1@0+ (1,0) [0|1] "" Host
 SG_ activated : 14|1@0+ (1,0) [0|1] "" Host
 SG_ watchdog_error : 13|1@0+ (1,0) [0|1] "" Host
 SG_ wrong_product : 12|1@0+ (1,0) [0|1] "" Host

BO_ 1205 Send_Respond_State_of_E_N9_Fault: 2 Driver9
 SG_ error : 7|1@0+ (1,0) [0|1] "" Host
 SG_ temperature_error : 6|1@0+ (1,0) [0|1] "" Host
 SG_ encoder_error : 5|1@0+ (1,0) [0|1] "" Host
 SG_ vbus_error : 4|1@0+ (1,0) [0|1] "" Host
 SG_ driver_error : 3|1@0+ (1,0) [0|1] "" Host
 SG_ velocity_error : 2|1@0+ (1,0) [0|1] "" Host
 SG_ current_error : 1|1@0+ (1,0) [0|1] "" Host
 SG_ estop_error : 0|1@0+ (1,0) [0|1] "" Host
 SG_ calibrated : 15|1@0+ (1,0) [0|1] "" Host
 SG_ activated : 14|1@0+ (1,0) [0|1] "" Host
 SG_ watchdog_error : 13|1@0+ (1,0) [0|1] "" Host
 SG_ wrong_product : 12|1@0+ (1,0) [0|1] "" Host

BO_ 1206 Send_Respond_Iq_data_N9: 2 Driver9
 SG_ current : 7|16@0- (1,0) [-32768|32767] "" Host

BO_ 1207 Send_Respond_Iq_data_N9_Fault: 2 Driver9
 SG_ current : 7|16@0- (1,0) [-32768|32767] "" Host

BO_ 1208 Send_Respond_Encoder_data_N9: 8 Driver9
 SG_ position : 7|32@0- (1,0) [-2147483648|2147483647] "" Host
 SG_ speed : 39|32@0- (1,0) [-2147483648|2147483647] "" Host

BO_ 1209 Send_Respond_Encoder_da_N9_Fault: 8 Driver9
 SG_ position : 7|32@0- (1,0) [-2147483648|2147483647] "" Host
 SG_ speed : 39|32@0- (1,0) [-2147483648|2147483647] "" Host

BO_ 1218 Send_Respond_Kt_N9: 4 Driver9
 SG_ Kt : 7|32@0+ (1,0) [-3.402823466e+38|3.402823466e+38] "" Host

BO_ 1219 Send_Respond_Kt_N9_Fault: 4 Driver9
 SG_ Kt : 7|32@0+ (1,0) [-3.402823466e+38|3.402823466e+38] "" Host

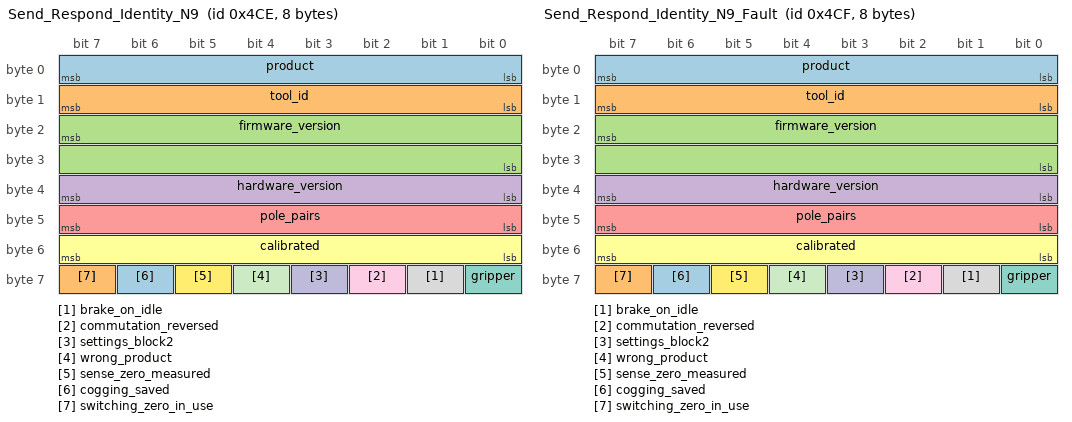
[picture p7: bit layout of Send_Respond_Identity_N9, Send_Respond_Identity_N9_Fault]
BO_ 1230 Send_Respond_Identity_N9: 8 Driver9
 SG_ product : 7|8@0+ (1,0) [0|255] "" Host
 SG_ tool_id : 15|8@0+ (1,0) [0|255] "" Host
 SG_ firmware_version : 23|16@0+ (1,0) [0|65535] "" Host
 SG_ hardware_version : 39|8@0+ (1,0) [0|255] "" Host
 SG_ pole_pairs : 47|8@0+ (1,0) [0|255] "" Host
 SG_ calibrated : 55|8@0+ (1,0) [0|255] "" Host
 SG_ gripper : 56|1@0+ (1,0) [0|1] "" Host
 SG_ brake_on_idle : 57|1@0+ (1,0) [0|1] "" Host
 SG_ commutation_reversed : 58|1@0+ (1,0) [0|1] "" Host
 SG_ settings_block2 : 59|1@0+ (1,0) [0|1] "" Host
 SG_ wrong_product : 60|1@0+ (1,0) [0|1] "" Host
 SG_ sense_zero_measured : 61|1@0+ (1,0) [0|1] "" Host
 SG_ cogging_saved : 62|1@0+ (1,0) [0|1] "" Host
 SG_ switching_zero_in_use : 63|1@0+ (1,0) [0|1] "" Host

BO_ 1231 Send_Respond_Identity_N9_Fault: 8 Driver9
 SG_ product : 7|8@0+ (1,0) [0|255] "" Host
 SG_ tool_id : 15|8@0+ (1,0) [0|255] "" Host
 SG_ firmware_version : 23|16@0+ (1,0) [0|65535] "" Host
 SG_ hardware_version : 39|8@0+ (1,0) [0|255] "" Host
 SG_ pole_pairs : 47|8@0+ (1,0) [0|255] "" Host
 SG_ calibrated : 55|8@0+ (1,0) [0|255] "" Host
 SG_ gripper : 56|1@0+ (1,0) [0|1] "" Host
 SG_ brake_on_idle : 57|1@0+ (1,0) [0|1] "" Host
 SG_ commutation_reversed : 58|1@0+ (1,0) [0|1] "" Host
 SG_ settings_block2 : 59|1@0+ (1,0) [0|1] "" Host
 SG_ wrong_product : 60|1@0+ (1,0) [0|1] "" Host
 SG_ sense_zero_measured : 61|1@0+ (1,0) [0|1] "" Host
 SG_ cogging_saved : 62|1@0+ (1,0) [0|1] "" Host
 SG_ switching_zero_in_use : 63|1@0+ (1,0) [0|1] "" Host

BO_ 1232 Send_Respond_Telemetry_N9: 8 Driver9
 SG_ temperature : 7|16@0- (1,0) [-32768|32767] "" Host
 SG_ voltage : 23|16@0- (1,0) [-32768|32767] "" Host
 SG_ errors_1 : 39|8@0+ (1,0) [0|255] "" Host
 SG_ errors_2 : 47|8@0+ (1,0) [0|255] "" Host
 SG_ current : 55|16@0- (1,0) [-32768|32767] "" Host

BO_ 1233 Send_Respond_Telemetry_N9_Fault: 8 Driver9
 SG_ temperature : 7|16@0- (1,0) [-32768|32767] "" Host
 SG_ voltage : 23|16@0- (1,0) [-32768|32767] "" Host
 SG_ errors_1 : 39|8@0+ (1,0) [0|255] "" Host
 SG_ errors_2 : 47|8@0+ (1,0) [0|255] "" Host
 SG_ current : 55|16@0- (1,0) [-32768|32767] "" Host

BO_ 1170 Respond_Heartbeat_N9: 0 Driver9

BO_ 1171 Respond_Heartbeat_N9_Fault: 0 Driver9

BO_ 1174 Send_CAN_ID_N9: 1 Host
 SG_ ID : 7|8@0+ (1,0) [0|255] "" Driver9

BO_ 1152 Send_ESTOP_N9: 0 Host

BO_ 1176 Send_Idle_N9: 0 Host

BO_ 1178 Send_Save_config_N9: 0 Host

BO_ 1180 Send_Reset_N9: 0 Host

BO_ 1154 Send_Clear_Error_N9: 0 Host

BO_ 1182 Send_Watchdog_N9: 5 Host
 SG_ Time : 7|32@0+ (1,0) [0|4294967295] "" Driver9
 SG_ Action : 39|8@0+ (1,0) [0|255] "" Driver9

BO_ 1212 Send_Heartbeat_Setup_N9: 4 Host
 SG_ Interval : 7|32@0+ (1,0) [0|4294967295] "" Driver9

BO_ 1222 Send_Settings_N9: 2 Host
 SG_ Mask : 7|8@0+ (1,0) [0|255] "" Driver9
 SG_ Value : 15|8@0+ (1,0) [0|255] "" Driver9

BO_ 1224 Send_Parameter_N9: 5 Host
 SG_ Parameter : 7|8@0+ (1,0) [0|255] "" Driver9
 SG_ Value : 15|32@0- (1,0) [-2147483648|2147483647] "" Driver9

BO_ 1226 Send_Get_Parameter_N9: 1 Host
 SG_ Parameter : 7|8@0+ (1,0) [0|255] "" Driver9

BO_ 1228 Respond_Parameter_N9: 5 Driver9
 SG_ parameter : 7|8@0+ (1,0) [0|255] "" Host
 SG_ value : 15|32@0- (1,0) [-2147483648|2147483647] "" Host

BO_ 1229 Respond_Parameter_N9_Fault: 5 Driver9
 SG_ parameter : 7|8@0+ (1,0) [0|255] "" Host
 SG_ value : 15|32@0- (1,0) [-2147483648|2147483647] "" Host

BO_ 1234 Send_Buffer_Read_N9: 5 Host
 SG_ Kind : 7|8@0+ (1,0) [0|255] "" Driver9
 SG_ First : 15|16@0+ (1,0) [0|65535] "" Driver9
 SG_ Count : 31|16@0+ (1,0) [0|65535] "" Driver9

BO_ 1236 Respond_Buffer_Data_N9: 8 Driver9
 SG_ header : 7|16@0+ (1,0) [0|65535] "" Host
 SG_ word_a : 23|16@0- (1,0) [-32768|32767] "" Host
 SG_ word_b : 39|16@0- (1,0) [-32768|32767] "" Host
 SG_ word_c : 55|16@0- (1,0) [-32768|32767] "" Host

BO_ 1237 Respond_Buffer_Data_N9_Fault: 8 Driver9
 SG_ header : 7|16@0+ (1,0) [0|65535] "" Host
 SG_ word_a : 23|16@0- (1,0) [-32768|32767] "" Host
 SG_ word_b : 39|16@0- (1,0) [-32768|32767] "" Host
 SG_ word_c : 55|16@0- (1,0) [-32768|32767] "" Host

BO_ 1238 Send_Buffer_Write_N9: 8 Host
 SG_ Header : 7|16@0+ (1,0) [0|65535] "" Driver9
 SG_ Word_A : 23|16@0- (1,0) [-32768|32767] "" Driver9
 SG_ Word_B : 39|16@0- (1,0) [-32768|32767] "" Driver9
 SG_ Word_C : 55|16@0- (1,0) [-32768|32767] "" Driver9

BO_ 1240 Send_Sound_N9: 8 Host
 SG_ Operation : 7|8@0+ (1,0) [0|255] "" Driver9
 SG_ Channel : 15|8@0+ (1,0) [0|255] "" Driver9
 SG_ A : 23|16@0+ (1,0) [0|65535] "" Driver9
 SG_ B : 39|16@0+ (1,0) [0|65535] "" Driver9
 SG_ C : 55|16@0+ (1,0) [0|65535] "" Driver9

BO_ 1242 Send_Sound_Samples_N9: 8 Host
 SG_ Sample_1 : 7|8@0- (1,0) [-128|127] "" Driver9
 SG_ Sample_2 : 15|8@0- (1,0) [-128|127] "" Driver9
 SG_ Sample_3 : 23|8@0- (1,0) [-128|127] "" Driver9
 SG_ Sample_4 : 31|8@0- (1,0) [-128|127] "" Driver9
 SG_ Sample_5 : 39|8@0- (1,0) [-128|127] "" Driver9
 SG_ Sample_6 : 47|8@0- (1,0) [-128|127] "" Driver9
 SG_ Sample_7 : 55|8@0- (1,0) [-128|127] "" Driver9
 SG_ Sample_8 : 63|8@0- (1,0) [-128|127] "" Driver9

BO_ 1274 Send_gripper_data_pack_N9: 5 Host
 SG_ Position : 7|8@0+ (1,0) [0|255] "" Driver9
 SG_ Speed : 15|8@0+ (1,0) [0|255] "" Driver9
 SG_ Current : 23|16@0- (1,0) [-32768|32767] "" Driver9
 SG_ Activate : 39|1@0+ (1,0) [0|1] "" Driver9
 SG_ Action : 38|1@0+ (1,0) [0|1] "" Driver9
 SG_ E_stop : 37|1@0+ (1,0) [0|1] "" Driver9
 SG_ Release_direction : 36|1@0+ (1,0) [0|1] "" Driver9

BO_ 1276 Send_gripper_calibrate_N9: 0 Host

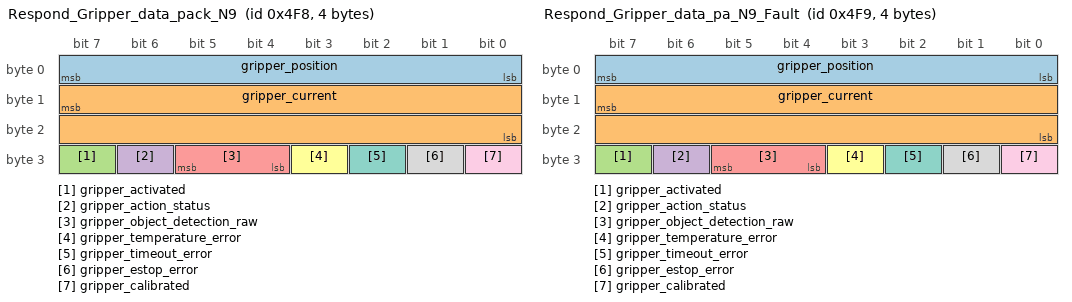
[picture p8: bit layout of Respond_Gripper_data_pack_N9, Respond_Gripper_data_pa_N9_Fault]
BO_ 1272 Respond_Gripper_data_pack_N9: 4 Driver9
 SG_ gripper_position : 7|8@0+ (1,0) [0|255] "" Host
 SG_ gripper_current : 15|16@0- (1,0) [-32768|32767] "" Host
 SG_ gripper_activated : 31|1@0+ (1,0) [0|1] "" Host
 SG_ gripper_action_status : 30|1@0+ (1,0) [0|1] "" Host
 SG_ gripper_object_detection_raw : 29|2@0+ (1,0) [0|3] "" Host
 SG_ gripper_temperature_error : 27|1@0+ (1,0) [0|1] "" Host
 SG_ gripper_timeout_error : 26|1@0+ (1,0) [0|1] "" Host
 SG_ gripper_estop_error : 25|1@0+ (1,0) [0|1] "" Host
 SG_ gripper_calibrated : 24|1@0+ (1,0) [0|1] "" Host

BO_ 1273 Respond_Gripper_data_pa_N9_Fault: 4 Driver9
 SG_ gripper_position : 7|8@0+ (1,0) [0|255] "" Host
 SG_ gripper_current : 15|16@0- (1,0) [-32768|32767] "" Host
 SG_ gripper_activated : 31|1@0+ (1,0) [0|1] "" Host
 SG_ gripper_action_status : 30|1@0+ (1,0) [0|1] "" Host
 SG_ gripper_object_detection_raw : 29|2@0+ (1,0) [0|3] "" Host
 SG_ gripper_temperature_error : 27|1@0+ (1,0) [0|1] "" Host
 SG_ gripper_timeout_error : 26|1@0+ (1,0) [0|1] "" Host
 SG_ gripper_estop_error : 25|1@0+ (1,0) [0|1] "" Host
 SG_ gripper_calibrated : 24|1@0+ (1,0) [0|1] "" Host

BO_ 1284 Send_data_pack_1_N10: 5 Host
 SG_ Speed_setpoint : 7|24@0- (1,0) [-8388608|8388607] "" Driver10
 SG_ Current_feedforward : 31|16@0- (1,0) [-32768|32767] "" Driver10

BO_ 1288 Send_data_pack_PD_N10: 8 Host
 SG_ Position_setpoint : 7|24@0- (1,0) [-8388608|8388607] "" Driver10
 SG_ Speed_setpoint : 31|24@0- (1,0) [-8388608|8388607] "" Driver10
 SG_ Current_feedforward : 55|16@0- (1,0) [-32768|32767] "" Driver10

BO_ 1342 Send_data_pack_HALL_N10: 4 Host
 SG_ Speed : 7|24@0- (1,0) [-8388608|8388607] "" Driver10
 SG_ Trigger : 31|8@0+ (1,0) [0|255] "" Driver10

BO_ 1286 Respond_data_pack_1_N10: 8 Driver10
 SG_ position : 7|24@0- (1,0) [-8388608|8388607] "" Host
 SG_ speed : 31|24@0- (1,0) [-8388608|8388607] "" Host
 SG_ current : 55|16@0- (1,0) [-32768|32767] "" Host

BO_ 1287 Respond_data_pack_1_N10_Fault: 8 Driver10
 SG_ position : 7|24@0- (1,0) [-8388608|8388607] "" Host
 SG_ speed : 31|24@0- (1,0) [-8388608|8388607] "" Host
 SG_ current : 55|16@0- (1,0) [-32768|32767] "" Host

BO_ 1344 Respond_data_hall_N10: 4 Driver10
 SG_ position : 7|24@0- (1,0) [-8388608|8388607] "" Host
 SG_ HALL_trigger : 31|1@0+ (1,0) [0|1] "" Host
 SG_ additional_pin2 : 30|1@0+ (1,0) [0|1] "" Host
 SG_ hall_index : 29|1@0+ (1,0) [0|1] "" Host

BO_ 1345 Respond_data_hall_N10_Fault: 4 Driver10
 SG_ position : 7|24@0- (1,0) [-8388608|8388607] "" Host
 SG_ HALL_trigger : 31|1@0+ (1,0) [0|1] "" Host
 SG_ additional_pin2 : 30|1@0+ (1,0) [0|1] "" Host
 SG_ hall_index : 29|1@0+ (1,0) [0|1] "" Host

BO_ 1312 Send_PD_Gains_N10: 8 Host
 SG_ KP : 7|32@0+ (1,0) [-3.402823466e+38|3.402823466e+38] "" Driver10
 SG_ KD : 39|32@0+ (1,0) [-3.402823466e+38|3.402823466e+38] "" Driver10

BO_ 1314 Send_Current_Gains_N10: 8 Host
 SG_ Kp_iq : 7|32@0+ (1,0) [-3.402823466e+38|3.402823466e+38] "" Driver10
 SG_ Ki_iq : 39|32@0+ (1,0) [-3.402823466e+38|3.402823466e+38] "" Driver10

BO_ 1316 Send_Velocity_Gains_N10: 8 Host
 SG_ Kpv : 7|32@0+ (1,0) [-3.402823466e+38|3.402823466e+38] "" Driver10
 SG_ Kiv : 39|32@0+ (1,0) [-3.402823466e+38|3.402823466e+38] "" Driver10

BO_ 1318 Send_Position_Gains_N10: 4 Host
 SG_ Kpp : 7|32@0+ (1,0) [-3.402823466e+38|3.402823466e+38] "" Driver10

BO_ 1320 Send_Limits_N10: 8 Host
 SG_ Speed_limit : 7|32@0+ (1,0) [-3.402823466e+38|3.402823466e+38] "" Driver10
 SG_ Current_limit : 39|32@0+ (1,0) [-3.402823466e+38|3.402823466e+38] "" Driver10

BO_ 1324 Send_Kt_N10: 4 Host
 SG_ Kt : 7|32@0+ (1,0) [-3.402823466e+38|3.402823466e+38] "" Driver10

BO_ 1348 Send_Voltage_Limit_N10: 4 Host
 SG_ Voltage_limit : 7|32@0- (1,0) [-2147483648|2147483647] "" Driver10

BO_ 1300 Send_Respond_Ping_N10: 0 Driver10

BO_ 1301 Send_Respond_Ping_N10_Fault: 0 Driver10

BO_ 1326 Send_Respond_Temperature_N10: 2 Driver10
 SG_ temperature : 7|16@0- (1,0) [-32768|32767] "" Host

BO_ 1327 Send_Respond_Temperatu_N10_Fault: 2 Driver10
 SG_ temperature : 7|16@0- (1,0) [-32768|32767] "" Host

BO_ 1328 Send_Respond_Voltage_N10: 2 Driver10
 SG_ voltage : 7|16@0+ (1,0) [0|65535] "" Host

BO_ 1329 Send_Respond_Voltage_N10_Fault: 2 Driver10
 SG_ voltage : 7|16@0+ (1,0) [0|65535] "" Host

BO_ 1330 Send_Respond_Device_Info_N10: 7 Driver10
 SG_ HARDWARE_VERSION : 7|8@0+ (1,0) [0|255] "" Host
 SG_ BATCH_DATE : 15|8@0+ (1,0) [0|255] "" Host
 SG_ SOFTWARE_VERSION : 23|8@0+ (1,0) [0|255] "" Host
 SG_ SERIAL_NUMBER : 31|32@0+ (1,0) [0|4294967295] "" Host

BO_ 1331 Send_Respond_Device_In_N10_Fault: 7 Driver10
 SG_ HARDWARE_VERSION : 7|8@0+ (1,0) [0|255] "" Host
 SG_ BATCH_DATE : 15|8@0+ (1,0) [0|255] "" Host
 SG_ SOFTWARE_VERSION : 23|8@0+ (1,0) [0|255] "" Host
 SG_ SERIAL_NUMBER : 31|32@0+ (1,0) [0|4294967295] "" Host

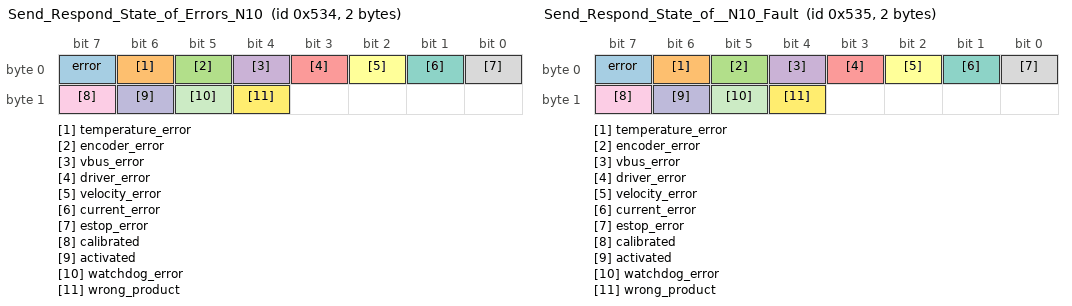
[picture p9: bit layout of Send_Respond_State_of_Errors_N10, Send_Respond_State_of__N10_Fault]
BO_ 1332 Send_Respond_State_of_Errors_N10: 2 Driver10
 SG_ error : 7|1@0+ (1,0) [0|1] "" Host
 SG_ temperature_error : 6|1@0+ (1,0) [0|1] "" Host
 SG_ encoder_error : 5|1@0+ (1,0) [0|1] "" Host
 SG_ vbus_error : 4|1@0+ (1,0) [0|1] "" Host
 SG_ driver_error : 3|1@0+ (1,0) [0|1] "" Host
 SG_ velocity_error : 2|1@0+ (1,0) [0|1] "" Host
 SG_ current_error : 1|1@0+ (1,0) [0|1] "" Host
 SG_ estop_error : 0|1@0+ (1,0) [0|1] "" Host
 SG_ calibrated : 15|1@0+ (1,0) [0|1] "" Host
 SG_ activated : 14|1@0+ (1,0) [0|1] "" Host
 SG_ watchdog_error : 13|1@0+ (1,0) [0|1] "" Host
 SG_ wrong_product : 12|1@0+ (1,0) [0|1] "" Host

BO_ 1333 Send_Respond_State_of__N10_Fault: 2 Driver10
 SG_ error : 7|1@0+ (1,0) [0|1] "" Host
 SG_ temperature_error : 6|1@0+ (1,0) [0|1] "" Host
 SG_ encoder_error : 5|1@0+ (1,0) [0|1] "" Host
 SG_ vbus_error : 4|1@0+ (1,0) [0|1] "" Host
 SG_ driver_error : 3|1@0+ (1,0) [0|1] "" Host
 SG_ velocity_error : 2|1@0+ (1,0) [0|1] "" Host
 SG_ current_error : 1|1@0+ (1,0) [0|1] "" Host
 SG_ estop_error : 0|1@0+ (1,0) [0|1] "" Host
 SG_ calibrated : 15|1@0+ (1,0) [0|1] "" Host
 SG_ activated : 14|1@0+ (1,0) [0|1] "" Host
 SG_ watchdog_error : 13|1@0+ (1,0) [0|1] "" Host
 SG_ wrong_product : 12|1@0+ (1,0) [0|1] "" Host

BO_ 1334 Send_Respond_Iq_data_N10: 2 Driver10
 SG_ current : 7|16@0- (1,0) [-32768|32767] "" Host

BO_ 1335 Send_Respond_Iq_data_N10_Fault: 2 Driver10
 SG_ current : 7|16@0- (1,0) [-32768|32767] "" Host

BO_ 1336 Send_Respond_Encoder_data_N10: 8 Driver10
 SG_ position : 7|32@0- (1,0) [-2147483648|2147483647] "" Host
 SG_ speed : 39|32@0- (1,0) [-2147483648|2147483647] "" Host

BO_ 1337 Send_Respond_Encoder_d_N10_Fault: 8 Driver10
 SG_ position : 7|32@0- (1,0) [-2147483648|2147483647] "" Host
 SG_ speed : 39|32@0- (1,0) [-2147483648|2147483647] "" Host

BO_ 1346 Send_Respond_Kt_N10: 4 Driver10
 SG_ Kt : 7|32@0+ (1,0) [-3.402823466e+38|3.402823466e+38] "" Host

BO_ 1347 Send_Respond_Kt_N10_Fault: 4 Driver10
 SG_ Kt : 7|32@0+ (1,0) [-3.402823466e+38|3.402823466e+38] "" Host

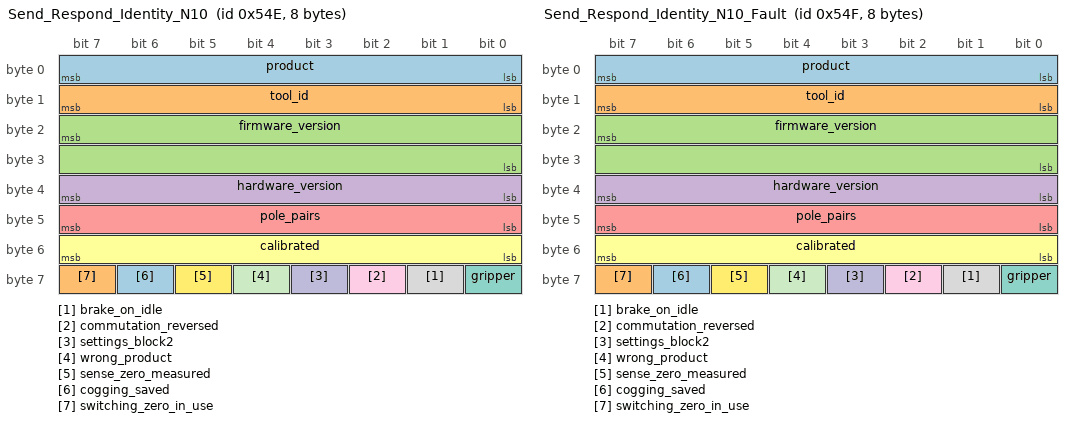
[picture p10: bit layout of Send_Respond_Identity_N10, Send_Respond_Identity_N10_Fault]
BO_ 1358 Send_Respond_Identity_N10: 8 Driver10
 SG_ product : 7|8@0+ (1,0) [0|255] "" Host
 SG_ tool_id : 15|8@0+ (1,0) [0|255] "" Host
 SG_ firmware_version : 23|16@0+ (1,0) [0|65535] "" Host
 SG_ hardware_version : 39|8@0+ (1,0) [0|255] "" Host
 SG_ pole_pairs : 47|8@0+ (1,0) [0|255] "" Host
 SG_ calibrated : 55|8@0+ (1,0) [0|255] "" Host
 SG_ gripper : 56|1@0+ (1,0) [0|1] "" Host
 SG_ brake_on_idle : 57|1@0+ (1,0) [0|1] "" Host
 SG_ commutation_reversed : 58|1@0+ (1,0) [0|1] "" Host
 SG_ settings_block2 : 59|1@0+ (1,0) [0|1] "" Host
 SG_ wrong_product : 60|1@0+ (1,0) [0|1] "" Host
 SG_ sense_zero_measured : 61|1@0+ (1,0) [0|1] "" Host
 SG_ cogging_saved : 62|1@0+ (1,0) [0|1] "" Host
 SG_ switching_zero_in_use : 63|1@0+ (1,0) [0|1] "" Host

BO_ 1359 Send_Respond_Identity_N10_Fault: 8 Driver10
 SG_ product : 7|8@0+ (1,0) [0|255] "" Host
 SG_ tool_id : 15|8@0+ (1,0) [0|255] "" Host
 SG_ firmware_version : 23|16@0+ (1,0) [0|65535] "" Host
 SG_ hardware_version : 39|8@0+ (1,0) [0|255] "" Host
 SG_ pole_pairs : 47|8@0+ (1,0) [0|255] "" Host
 SG_ calibrated : 55|8@0+ (1,0) [0|255] "" Host
 SG_ gripper : 56|1@0+ (1,0) [0|1] "" Host
 SG_ brake_on_idle : 57|1@0+ (1,0) [0|1] "" Host
 SG_ commutation_reversed : 58|1@0+ (1,0) [0|1] "" Host
 SG_ settings_block2 : 59|1@0+ (1,0) [0|1] "" Host
 SG_ wrong_product : 60|1@0+ (1,0) [0|1] "" Host
 SG_ sense_zero_measured : 61|1@0+ (1,0) [0|1] "" Host
 SG_ cogging_saved : 62|1@0+ (1,0) [0|1] "" Host
 SG_ switching_zero_in_use : 63|1@0+ (1,0) [0|1] "" Host

BO_ 1360 Send_Respond_Telemetry_N10: 8 Driver10
 SG_ temperature : 7|16@0- (1,0) [-32768|32767] "" Host
 SG_ voltage : 23|16@0- (1,0) [-32768|32767] "" Host
 SG_ errors_1 : 39|8@0+ (1,0) [0|255] "" Host
 SG_ errors_2 : 47|8@0+ (1,0) [0|255] "" Host
 SG_ current : 55|16@0- (1,0) [-32768|32767] "" Host

BO_ 1361 Send_Respond_Telemetry_N10_Fault: 8 Driver10
 SG_ temperature : 7|16@0- (1,0) [-32768|32767] "" Host
 SG_ voltage : 23|16@0- (1,0) [-32768|32767] "" Host
 SG_ errors_1 : 39|8@0+ (1,0) [0|255] "" Host
 SG_ errors_2 : 47|8@0+ (1,0) [0|255] "" Host
 SG_ current : 55|16@0- (1,0) [-32768|32767] "" Host

BO_ 1298 Respond_Heartbeat_N10: 0 Driver10

BO_ 1299 Respond_Heartbeat_N10_Fault: 0 Driver10

BO_ 1302 Send_CAN_ID_N10: 1 Host
 SG_ ID : 7|8@0+ (1,0) [0|255] "" Driver10

BO_ 1280 Send_ESTOP_N10: 0 Host

BO_ 1304 Send_Idle_N10: 0 Host

BO_ 1306 Send_Save_config_N10: 0 Host

BO_ 1308 Send_Reset_N10: 0 Host

BO_ 1282 Send_Clear_Error_N10: 0 Host

BO_ 1310 Send_Watchdog_N10: 5 Host
 SG_ Time : 7|32@0+ (1,0) [0|4294967295] "" Driver10
 SG_ Action : 39|8@0+ (1,0) [0|255] "" Driver10

BO_ 1340 Send_Heartbeat_Setup_N10: 4 Host
 SG_ Interval : 7|32@0+ (1,0) [0|4294967295] "" Driver10

BO_ 1350 Send_Settings_N10: 2 Host
 SG_ Mask : 7|8@0+ (1,0) [0|255] "" Driver10
 SG_ Value : 15|8@0+ (1,0) [0|255] "" Driver10

BO_ 1352 Send_Parameter_N10: 5 Host
 SG_ Parameter : 7|8@0+ (1,0) [0|255] "" Driver10
 SG_ Value : 15|32@0- (1,0) [-2147483648|2147483647] "" Driver10

BO_ 1354 Send_Get_Parameter_N10: 1 Host
 SG_ Parameter : 7|8@0+ (1,0) [0|255] "" Driver10

BO_ 1356 Respond_Parameter_N10: 5 Driver10
 SG_ parameter : 7|8@0+ (1,0) [0|255] "" Host
 SG_ value : 15|32@0- (1,0) [-2147483648|2147483647] "" Host

BO_ 1357 Respond_Parameter_N10_Fault: 5 Driver10
 SG_ parameter : 7|8@0+ (1,0) [0|255] "" Host
 SG_ value : 15|32@0- (1,0) [-2147483648|2147483647] "" Host

BO_ 1362 Send_Buffer_Read_N10: 5 Host
 SG_ Kind : 7|8@0+ (1,0) [0|255] "" Driver10
 SG_ First : 15|16@0+ (1,0) [0|65535] "" Driver10
 SG_ Count : 31|16@0+ (1,0) [0|65535] "" Driver10

BO_ 1364 Respond_Buffer_Data_N10: 8 Driver10
 SG_ header : 7|16@0+ (1,0) [0|65535] "" Host
 SG_ word_a : 23|16@0- (1,0) [-32768|32767] "" Host
 SG_ word_b : 39|16@0- (1,0) [-32768|32767] "" Host
 SG_ word_c : 55|16@0- (1,0) [-32768|32767] "" Host

BO_ 1365 Respond_Buffer_Data_N10_Fault: 8 Driver10
 SG_ header : 7|16@0+ (1,0) [0|65535] "" Host
 SG_ word_a : 23|16@0- (1,0) [-32768|32767] "" Host
 SG_ word_b : 39|16@0- (1,0) [-32768|32767] "" Host
 SG_ word_c : 55|16@0- (1,0) [-32768|32767] "" Host

BO_ 1366 Send_Buffer_Write_N10: 8 Host
 SG_ Header : 7|16@0+ (1,0) [0|65535] "" Driver10
 SG_ Word_A : 23|16@0- (1,0) [-32768|32767] "" Driver10
 SG_ Word_B : 39|16@0- (1,0) [-32768|32767] "" Driver10
 SG_ Word_C : 55|16@0- (1,0) [-32768|32767] "" Driver10

BO_ 1368 Send_Sound_N10: 8 Host
 SG_ Operation : 7|8@0+ (1,0) [0|255] "" Driver10
 SG_ Channel : 15|8@0+ (1,0) [0|255] "" Driver10
 SG_ A : 23|16@0+ (1,0) [0|65535] "" Driver10
 SG_ B : 39|16@0+ (1,0) [0|65535] "" Driver10
 SG_ C : 55|16@0+ (1,0) [0|65535] "" Driver10

BO_ 1370 Send_Sound_Samples_N10: 8 Host
 SG_ Sample_1 : 7|8@0- (1,0) [-128|127] "" Driver10
 SG_ Sample_2 : 15|8@0- (1,0) [-128|127] "" Driver10
 SG_ Sample_3 : 23|8@0- (1,0) [-128|127] "" Driver10
 SG_ Sample_4 : 31|8@0- (1,0) [-128|127] "" Driver10
 SG_ Sample_5 : 39|8@0- (1,0) [-128|127] "" Driver10
 SG_ Sample_6 : 47|8@0- (1,0) [-128|127] "" Driver10
 SG_ Sample_7 : 55|8@0- (1,0) [-128|127] "" Driver10
 SG_ Sample_8 : 63|8@0- (1,0) [-128|127] "" Driver10

BO_ 1402 Send_gripper_data_pack_N10: 5 Host
 SG_ Position : 7|8@0+ (1,0) [0|255] "" Driver10
 SG_ Speed : 15|8@0+ (1,0) [0|255] "" Driver10
 SG_ Current : 23|16@0- (1,0) [-32768|32767] "" Driver10
 SG_ Activate : 39|1@0+ (1,0) [0|1] "" Driver10
 SG_ Action : 38|1@0+ (1,0) [0|1] "" Driver10
 SG_ E_stop : 37|1@0+ (1,0) [0|1] "" Driver10
 SG_ Release_direction : 36|1@0+ (1,0) [0|1] "" Driver10

BO_ 1404 Send_gripper_calibrate_N10: 0 Host

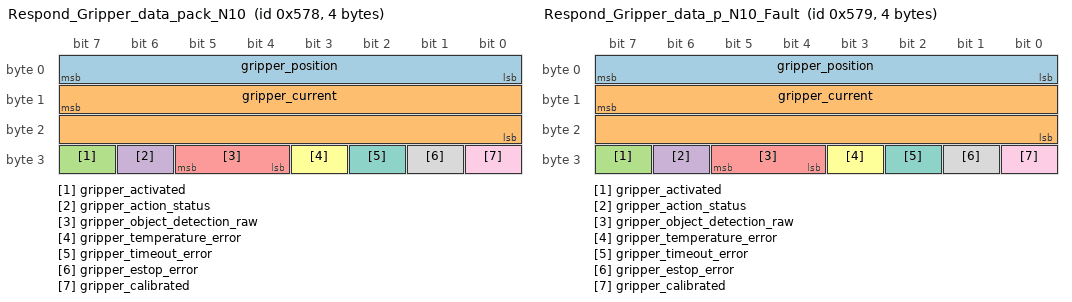
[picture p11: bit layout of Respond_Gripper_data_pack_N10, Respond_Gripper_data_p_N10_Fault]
BO_ 1400 Respond_Gripper_data_pack_N10: 4 Driver10
 SG_ gripper_position : 7|8@0+ (1,0) [0|255] "" Host
 SG_ gripper_current : 15|16@0- (1,0) [-32768|32767] "" Host
 SG_ gripper_activated : 31|1@0+ (1,0) [0|1] "" Host
 SG_ gripper_action_status : 30|1@0+ (1,0) [0|1] "" Host
 SG_ gripper_object_detection_raw : 29|2@0+ (1,0) [0|3] "" Host
 SG_ gripper_temperature_error : 27|1@0+ (1,0) [0|1] "" Host
 SG_ gripper_timeout_error : 26|1@0+ (1,0) [0|1] "" Host
 SG_ gripper_estop_error : 25|1@0+ (1,0) [0|1] "" Host
 SG_ gripper_calibrated : 24|1@0+ (1,0) [0|1] "" Host

BO_ 1401 Respond_Gripper_data_p_N10_Fault: 4 Driver10
 SG_ gripper_position : 7|8@0+ (1,0) [0|255] "" Host
 SG_ gripper_current : 15|16@0- (1,0) [-32768|32767] "" Host
 SG_ gripper_activated : 31|1@0+ (1,0) [0|1] "" Host
 SG_ gripper_action_status : 30|1@0+ (1,0) [0|1] "" Host
 SG_ gripper_object_detection_raw : 29|2@0+ (1,0) [0|3] "" Host
 SG_ gripper_temperature_error : 27|1@0+ (1,0) [0|1] "" Host
 SG_ gripper_timeout_error : 26|1@0+ (1,0) [0|1] "" Host
 SG_ gripper_estop_error : 25|1@0+ (1,0) [0|1] "" Host
 SG_ gripper_calibrated : 24|1@0+ (1,0) [0|1] "" Host

BO_ 1412 Send_data_pack_1_N11: 5 Host
 SG_ Speed_setpoint : 7|24@0- (1,0) [-8388608|8388607] "" Driver11
 SG_ Current_feedforward : 31|16@0- (1,0) [-32768|32767] "" Driver11

BO_ 1416 Send_data_pack_PD_N11: 8 Host
 SG_ Position_setpoint : 7|24@0- (1,0) [-8388608|8388607] "" Driver11
 SG_ Speed_setpoint : 31|24@0- (1,0) [-8388608|8388607] "" Driver11
 SG_ Current_feedforward : 55|16@0- (1,0) [-32768|32767] "" Driver11

BO_ 1470 Send_data_pack_HALL_N11: 4 Host
 SG_ Speed : 7|24@0- (1,0) [-8388608|8388607] "" Driver11
 SG_ Trigger : 31|8@0+ (1,0) [0|255] "" Driver11

BO_ 1414 Respond_data_pack_1_N11: 8 Driver11
 SG_ position : 7|24@0- (1,0) [-8388608|8388607] "" Host
 SG_ speed : 31|24@0- (1,0) [-8388608|8388607] "" Host
 SG_ current : 55|16@0- (1,0) [-32768|32767] "" Host

BO_ 1415 Respond_data_pack_1_N11_Fault: 8 Driver11
 SG_ position : 7|24@0- (1,0) [-8388608|8388607] "" Host
 SG_ speed : 31|24@0- (1,0) [-8388608|8388607] "" Host
 SG_ current : 55|16@0- (1,0) [-32768|32767] "" Host

BO_ 1472 Respond_data_hall_N11: 4 Driver11
 SG_ position : 7|24@0- (1,0) [-8388608|8388607] "" Host
 SG_ HALL_trigger : 31|1@0+ (1,0) [0|1] "" Host
 SG_ additional_pin2 : 30|1@0+ (1,0) [0|1] "" Host
 SG_ hall_index : 29|1@0+ (1,0) [0|1] "" Host

BO_ 1473 Respond_data_hall_N11_Fault: 4 Driver11
 SG_ position : 7|24@0- (1,0) [-8388608|8388607] "" Host
 SG_ HALL_trigger : 31|1@0+ (1,0) [0|1] "" Host
 SG_ additional_pin2 : 30|1@0+ (1,0) [0|1] "" Host
 SG_ hall_index : 29|1@0+ (1,0) [0|1] "" Host

BO_ 1440 Send_PD_Gains_N11: 8 Host
 SG_ KP : 7|32@0+ (1,0) [-3.402823466e+38|3.402823466e+38] "" Driver11
 SG_ KD : 39|32@0+ (1,0) [-3.402823466e+38|3.402823466e+38] "" Driver11

BO_ 1442 Send_Current_Gains_N11: 8 Host
 SG_ Kp_iq : 7|32@0+ (1,0) [-3.402823466e+38|3.402823466e+38] "" Driver11
 SG_ Ki_iq : 39|32@0+ (1,0) [-3.402823466e+38|3.402823466e+38] "" Driver11

BO_ 1444 Send_Velocity_Gains_N11: 8 Host
 SG_ Kpv : 7|32@0+ (1,0) [-3.402823466e+38|3.402823466e+38] "" Driver11
 SG_ Kiv : 39|32@0+ (1,0) [-3.402823466e+38|3.402823466e+38] "" Driver11

BO_ 1446 Send_Position_Gains_N11: 4 Host
 SG_ Kpp : 7|32@0+ (1,0) [-3.402823466e+38|3.402823466e+38] "" Driver11

BO_ 1448 Send_Limits_N11: 8 Host
 SG_ Speed_limit : 7|32@0+ (1,0) [-3.402823466e+38|3.402823466e+38] "" Driver11
 SG_ Current_limit : 39|32@0+ (1,0) [-3.402823466e+38|3.402823466e+38] "" Driver11

BO_ 1452 Send_Kt_N11: 4 Host
 SG_ Kt : 7|32@0+ (1,0) [-3.402823466e+38|3.402823466e+38] "" Driver11

BO_ 1476 Send_Voltage_Limit_N11: 4 Host
 SG_ Voltage_limit : 7|32@0- (1,0) [-2147483648|2147483647] "" Driver11

BO_ 1428 Send_Respond_Ping_N11: 0 Driver11

BO_ 1429 Send_Respond_Ping_N11_Fault: 0 Driver11

BO_ 1454 Send_Respond_Temperature_N11: 2 Driver11
 SG_ temperature : 7|16@0- (1,0) [-32768|32767] "" Host

BO_ 1455 Send_Respond_Temperatu_N11_Fault: 2 Driver11
 SG_ temperature : 7|16@0- (1,0) [-32768|32767] "" Host

BO_ 1456 Send_Respond_Voltage_N11: 2 Driver11
 SG_ voltage : 7|16@0+ (1,0) [0|65535] "" Host

BO_ 1457 Send_Respond_Voltage_N11_Fault: 2 Driver11
 SG_ voltage : 7|16@0+ (1,0) [0|65535] "" Host

BO_ 1458 Send_Respond_Device_Info_N11: 7 Driver11
 SG_ HARDWARE_VERSION : 7|8@0+ (1,0) [0|255] "" Host
 SG_ BATCH_DATE : 15|8@0+ (1,0) [0|255] "" Host
 SG_ SOFTWARE_VERSION : 23|8@0+ (1,0) [0|255] "" Host
 SG_ SERIAL_NUMBER : 31|32@0+ (1,0) [0|4294967295] "" Host

BO_ 1459 Send_Respond_Device_In_N11_Fault: 7 Driver11
 SG_ HARDWARE_VERSION : 7|8@0+ (1,0) [0|255] "" Host
 SG_ BATCH_DATE : 15|8@0+ (1,0) [0|255] "" Host
 SG_ SOFTWARE_VERSION : 23|8@0+ (1,0) [0|255] "" Host
 SG_ SERIAL_NUMBER : 31|32@0+ (1,0) [0|4294967295] "" Host

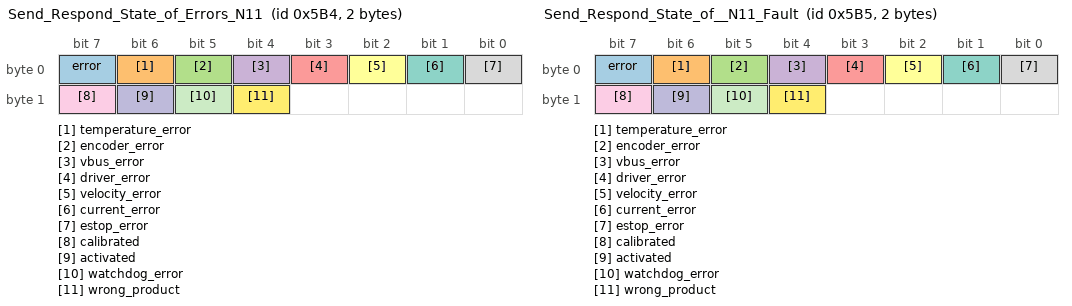
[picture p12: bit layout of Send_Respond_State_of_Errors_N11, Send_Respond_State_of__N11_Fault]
BO_ 1460 Send_Respond_State_of_Errors_N11: 2 Driver11
 SG_ error : 7|1@0+ (1,0) [0|1] "" Host
 SG_ temperature_error : 6|1@0+ (1,0) [0|1] "" Host
 SG_ encoder_error : 5|1@0+ (1,0) [0|1] "" Host
 SG_ vbus_error : 4|1@0+ (1,0) [0|1] "" Host
 SG_ driver_error : 3|1@0+ (1,0) [0|1] "" Host
 SG_ velocity_error : 2|1@0+ (1,0) [0|1] "" Host
 SG_ current_error : 1|1@0+ (1,0) [0|1] "" Host
 SG_ estop_error : 0|1@0+ (1,0) [0|1] "" Host
 SG_ calibrated : 15|1@0+ (1,0) [0|1] "" Host
 SG_ activated : 14|1@0+ (1,0) [0|1] "" Host
 SG_ watchdog_error : 13|1@0+ (1,0) [0|1] "" Host
 SG_ wrong_product : 12|1@0+ (1,0) [0|1] "" Host

BO_ 1461 Send_Respond_State_of__N11_Fault: 2 Driver11
 SG_ error : 7|1@0+ (1,0) [0|1] "" Host
 SG_ temperature_error : 6|1@0+ (1,0) [0|1] "" Host
 SG_ encoder_error : 5|1@0+ (1,0) [0|1] "" Host
 SG_ vbus_error : 4|1@0+ (1,0) [0|1] "" Host
 SG_ driver_error : 3|1@0+ (1,0) [0|1] "" Host
 SG_ velocity_error : 2|1@0+ (1,0) [0|1] "" Host
 SG_ current_error : 1|1@0+ (1,0) [0|1] "" Host
 SG_ estop_error : 0|1@0+ (1,0) [0|1] "" Host
 SG_ calibrated : 15|1@0+ (1,0) [0|1] "" Host
 SG_ activated : 14|1@0+ (1,0) [0|1] "" Host
 SG_ watchdog_error : 13|1@0+ (1,0) [0|1] "" Host
 SG_ wrong_product : 12|1@0+ (1,0) [0|1] "" Host

BO_ 1462 Send_Respond_Iq_data_N11: 2 Driver11
 SG_ current : 7|16@0- (1,0) [-32768|32767] "" Host

BO_ 1463 Send_Respond_Iq_data_N11_Fault: 2 Driver11
 SG_ current : 7|16@0- (1,0) [-32768|32767] "" Host

BO_ 1464 Send_Respond_Encoder_data_N11: 8 Driver11
 SG_ position : 7|32@0- (1,0) [-2147483648|2147483647] "" Host
 SG_ speed : 39|32@0- (1,0) [-2147483648|2147483647] "" Host

BO_ 1465 Send_Respond_Encoder_d_N11_Fault: 8 Driver11
 SG_ position : 7|32@0- (1,0) [-2147483648|2147483647] "" Host
 SG_ speed : 39|32@0- (1,0) [-2147483648|2147483647] "" Host

BO_ 1474 Send_Respond_Kt_N11: 4 Driver11
 SG_ Kt : 7|32@0+ (1,0) [-3.402823466e+38|3.402823466e+38] "" Host

BO_ 1475 Send_Respond_Kt_N11_Fault: 4 Driver11
 SG_ Kt : 7|32@0+ (1,0) [-3.402823466e+38|3.402823466e+38] "" Host

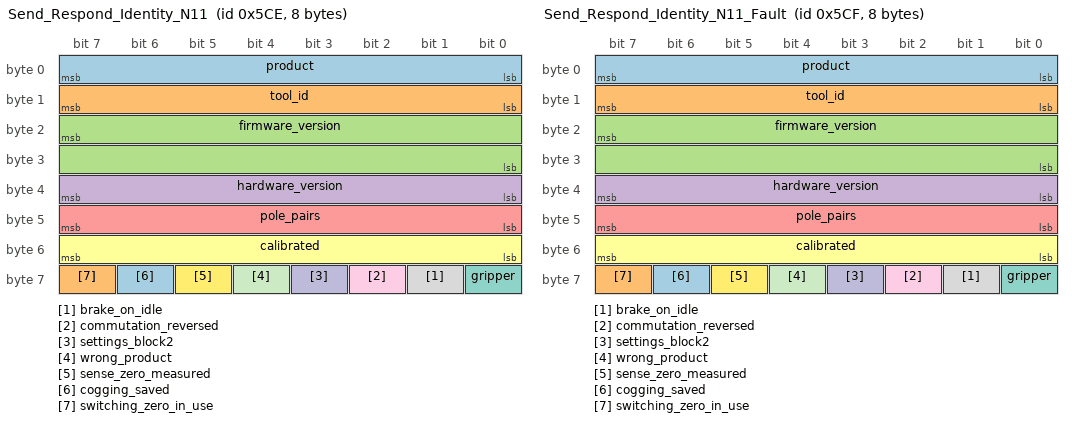
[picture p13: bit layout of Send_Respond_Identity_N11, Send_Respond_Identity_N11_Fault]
BO_ 1486 Send_Respond_Identity_N11: 8 Driver11
 SG_ product : 7|8@0+ (1,0) [0|255] "" Host
 SG_ tool_id : 15|8@0+ (1,0) [0|255] "" Host
 SG_ firmware_version : 23|16@0+ (1,0) [0|65535] "" Host
 SG_ hardware_version : 39|8@0+ (1,0) [0|255] "" Host
 SG_ pole_pairs : 47|8@0+ (1,0) [0|255] "" Host
 SG_ calibrated : 55|8@0+ (1,0) [0|255] "" Host
 SG_ gripper : 56|1@0+ (1,0) [0|1] "" Host
 SG_ brake_on_idle : 57|1@0+ (1,0) [0|1] "" Host
 SG_ commutation_reversed : 58|1@0+ (1,0) [0|1] "" Host
 SG_ settings_block2 : 59|1@0+ (1,0) [0|1] "" Host
 SG_ wrong_product : 60|1@0+ (1,0) [0|1] "" Host
 SG_ sense_zero_measured : 61|1@0+ (1,0) [0|1] "" Host
 SG_ cogging_saved : 62|1@0+ (1,0) [0|1] "" Host
 SG_ switching_zero_in_use : 63|1@0+ (1,0) [0|1] "" Host

BO_ 1487 Send_Respond_Identity_N11_Fault: 8 Driver11
 SG_ product : 7|8@0+ (1,0) [0|255] "" Host
 SG_ tool_id : 15|8@0+ (1,0) [0|255] "" Host
 SG_ firmware_version : 23|16@0+ (1,0) [0|65535] "" Host
 SG_ hardware_version : 39|8@0+ (1,0) [0|255] "" Host
 SG_ pole_pairs : 47|8@0+ (1,0) [0|255] "" Host
 SG_ calibrated : 55|8@0+ (1,0) [0|255] "" Host
 SG_ gripper : 56|1@0+ (1,0) [0|1] "" Host
 SG_ brake_on_idle : 57|1@0+ (1,0) [0|1] "" Host
 SG_ commutation_reversed : 58|1@0+ (1,0) [0|1] "" Host
 SG_ settings_block2 : 59|1@0+ (1,0) [0|1] "" Host
 SG_ wrong_product : 60|1@0+ (1,0) [0|1] "" Host
 SG_ sense_zero_measured : 61|1@0+ (1,0) [0|1] "" Host
 SG_ cogging_saved : 62|1@0+ (1,0) [0|1] "" Host
 SG_ switching_zero_in_use : 63|1@0+ (1,0) [0|1] "" Host

BO_ 1488 Send_Respond_Telemetry_N11: 8 Driver11
 SG_ temperature : 7|16@0- (1,0) [-32768|32767] "" Host
 SG_ voltage : 23|16@0- (1,0) [-32768|32767] "" Host
 SG_ errors_1 : 39|8@0+ (1,0) [0|255] "" Host
 SG_ errors_2 : 47|8@0+ (1,0) [0|255] "" Host
 SG_ current : 55|16@0- (1,0) [-32768|32767] "" Host

BO_ 1489 Send_Respond_Telemetry_N11_Fault: 8 Driver11
 SG_ temperature : 7|16@0- (1,0) [-32768|32767] "" Host
 SG_ voltage : 23|16@0- (1,0) [-32768|32767] "" Host
 SG_ errors_1 : 39|8@0+ (1,0) [0|255] "" Host
 SG_ errors_2 : 47|8@0+ (1,0) [0|255] "" Host
 SG_ current : 55|16@0- (1,0) [-32768|32767] "" Host

BO_ 1426 Respond_Heartbeat_N11: 0 Driver11

BO_ 1427 Respond_Heartbeat_N11_Fault: 0 Driver11

BO_ 1430 Send_CAN_ID_N11: 1 Host
 SG_ ID : 7|8@0+ (1,0) [0|255] "" Driver11

BO_ 1408 Send_ESTOP_N11: 0 Host

BO_ 1432 Send_Idle_N11: 0 Host

BO_ 1434 Send_Save_config_N11: 0 Host

BO_ 1436 Send_Reset_N11: 0 Host

BO_ 1410 Send_Clear_Error_N11: 0 Host

BO_ 1438 Send_Watchdog_N11: 5 Host
 SG_ Time : 7|32@0+ (1,0) [0|4294967295] "" Driver11
 SG_ Action : 39|8@0+ (1,0) [0|255] "" Driver11

BO_ 1468 Send_Heartbeat_Setup_N11: 4 Host
 SG_ Interval : 7|32@0+ (1,0) [0|4294967295] "" Driver11

BO_ 1478 Send_Settings_N11: 2 Host
 SG_ Mask : 7|8@0+ (1,0) [0|255] "" Driver11
 SG_ Value : 15|8@0+ (1,0) [0|255] "" Driver11

BO_ 1480 Send_Parameter_N11: 5 Host
 SG_ Parameter : 7|8@0+ (1,0) [0|255] "" Driver11
 SG_ Value : 15|32@0- (1,0) [-2147483648|2147483647] "" Driver11

BO_ 1482 Send_Get_Parameter_N11: 1 Host
 SG_ Parameter : 7|8@0+ (1,0) [0|255] "" Driver11

BO_ 1484 Respond_Parameter_N11: 5 Driver11
 SG_ parameter : 7|8@0+ (1,0) [0|255] "" Host
 SG_ value : 15|32@0- (1,0) [-2147483648|2147483647] "" Host

BO_ 1485 Respond_Parameter_N11_Fault: 5 Driver11
 SG_ parameter : 7|8@0+ (1,0) [0|255] "" Host
 SG_ value : 15|32@0- (1,0) [-2147483648|2147483647] "" Host

BO_ 1490 Send_Buffer_Read_N11: 5 Host
 SG_ Kind : 7|8@0+ (1,0) [0|255] "" Driver11
 SG_ First : 15|16@0+ (1,0) [0|65535] "" Driver11
 SG_ Count : 31|16@0+ (1,0) [0|65535] "" Driver11

BO_ 1492 Respond_Buffer_Data_N11: 8 Driver11
 SG_ header : 7|16@0+ (1,0) [0|65535] "" Host
 SG_ word_a : 23|16@0- (1,0) [-32768|32767] "" Host
 SG_ word_b : 39|16@0- (1,0) [-32768|32767] "" Host
 SG_ word_c : 55|16@0- (1,0) [-32768|32767] "" Host

BO_ 1493 Respond_Buffer_Data_N11_Fault: 8 Driver11
 SG_ header : 7|16@0+ (1,0) [0|65535] "" Host
 SG_ word_a : 23|16@0- (1,0) [-32768|32767] "" Host
 SG_ word_b : 39|16@0- (1,0) [-32768|32767] "" Host
 SG_ word_c : 55|16@0- (1,0) [-32768|32767] "" Host

BO_ 1494 Send_Buffer_Write_N11: 8 Host
 SG_ Header : 7|16@0+ (1,0) [0|65535] "" Driver11
 SG_ Word_A : 23|16@0- (1,0) [-32768|32767] "" Driver11
 SG_ Word_B : 39|16@0- (1,0) [-32768|32767] "" Driver11
 SG_ Word_C : 55|16@0- (1,0) [-32768|32767] "" Driver11

BO_ 1496 Send_Sound_N11: 8 Host
 SG_ Operation : 7|8@0+ (1,0) [0|255] "" Driver11
 SG_ Channel : 15|8@0+ (1,0) [0|255] "" Driver11
 SG_ A : 23|16@0+ (1,0) [0|65535] "" Driver11
 SG_ B : 39|16@0+ (1,0) [0|65535] "" Driver11
 SG_ C : 55|16@0+ (1,0) [0|65535] "" Driver11

BO_ 1498 Send_Sound_Samples_N11: 8 Host
 SG_ Sample_1 : 7|8@0- (1,0) [-128|127] "" Driver11
 SG_ Sample_2 : 15|8@0- (1,0) [-128|127] "" Driver11
 SG_ Sample_3 : 23|8@0- (1,0) [-128|127] "" Driver11
 SG_ Sample_4 : 31|8@0- (1,0) [-128|127] "" Driver11
 SG_ Sample_5 : 39|8@0- (1,0) [-128|127] "" Driver11
 SG_ Sample_6 : 47|8@0- (1,0) [-128|127] "" Driver11
 SG_ Sample_7 : 55|8@0- (1,0) [-128|127] "" Driver11
 SG_ Sample_8 : 63|8@0- (1,0) [-128|127] "" Driver11

BO_ 1530 Send_gripper_data_pack_N11: 5 Host
 SG_ Position : 7|8@0+ (1,0) [0|255] "" Driver11
 SG_ Speed : 15|8@0+ (1,0) [0|255] "" Driver11
 SG_ Current : 23|16@0- (1,0) [-32768|32767] "" Driver11
 SG_ Activate : 39|1@0+ (1,0) [0|1] "" Driver11
 SG_ Action : 38|1@0+ (1,0) [0|1] "" Driver11
 SG_ E_stop : 37|1@0+ (1,0) [0|1] "" Driver11
 SG_ Release_direction : 36|1@0+ (1,0) [0|1] "" Driver11

BO_ 1532 Send_gripper_calibrate_N11: 0 Host

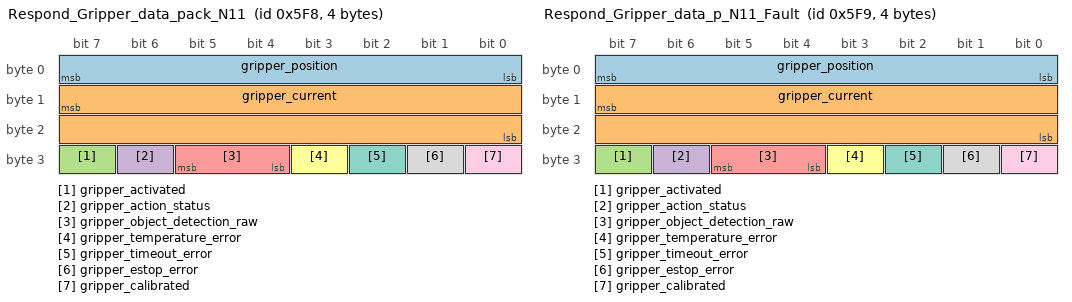
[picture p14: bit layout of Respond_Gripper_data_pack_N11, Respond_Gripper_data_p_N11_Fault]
BO_ 1528 Respond_Gripper_data_pack_N11: 4 Driver11
 SG_ gripper_position : 7|8@0+ (1,0) [0|255] "" Host
 SG_ gripper_current : 15|16@0- (1,0) [-32768|32767] "" Host
 SG_ gripper_activated : 31|1@0+ (1,0) [0|1] "" Host
 SG_ gripper_action_status : 30|1@0+ (1,0) [0|1] "" Host
 SG_ gripper_object_detection_raw : 29|2@0+ (1,0) [0|3] "" Host
 SG_ gripper_temperature_error : 27|1@0+ (1,0) [0|1] "" Host
 SG_ gripper_timeout_error : 26|1@0+ (1,0) [0|1] "" Host
 SG_ gripper_estop_error : 25|1@0+ (1,0) [0|1] "" Host
 SG_ gripper_calibrated : 24|1@0+ (1,0) [0|1] "" Host

BO_ 1529 Respond_Gripper_data_p_N11_Fault: 4 Driver11
 SG_ gripper_position : 7|8@0+ (1,0) [0|255] "" Host
 SG_ gripper_current : 15|16@0- (1,0) [-32768|32767] "" Host
 SG_ gripper_activated : 31|1@0+ (1,0) [0|1] "" Host
 SG_ gripper_action_status : 30|1@0+ (1,0) [0|1] "" Host
 SG_ gripper_object_detection_raw : 29|2@0+ (1,0) [0|3] "" Host
 SG_ gripper_temperature_error : 27|1@0+ (1,0) [0|1] "" Host
 SG_ gripper_timeout_error : 26|1@0+ (1,0) [0|1] "" Host
 SG_ gripper_estop_error : 25|1@0+ (1,0) [0|1] "" Host
 SG_ gripper_calibrated : 24|1@0+ (1,0) [0|1] "" Host

BO_ 1540 Send_data_pack_1_N12: 5 Host
 SG_ Speed_setpoint : 7|24@0- (1,0) [-8388608|8388607] "" Driver12
 SG_ Current_feedforward : 31|16@0- (1,0) [-32768|32767] "" Driver12

BO_ 1544 Send_data_pack_PD_N12: 8 Host
 SG_ Position_setpoint : 7|24@0- (1,0) [-8388608|8388607] "" Driver12
 SG_ Speed_setpoint : 31|24@0- (1,0) [-8388608|8388607] "" Driver12
 SG_ Current_feedforward : 55|16@0- (1,0) [-32768|32767] "" Driver12

BO_ 1598 Send_data_pack_HALL_N12: 4 Host
 SG_ Speed : 7|24@0- (1,0) [-8388608|8388607] "" Driver12
 SG_ Trigger : 31|8@0+ (1,0) [0|255] "" Driver12

BO_ 1542 Respond_data_pack_1_N12: 8 Driver12
 SG_ position : 7|24@0- (1,0) [-8388608|8388607] "" Host
 SG_ speed : 31|24@0- (1,0) [-8388608|8388607] "" Host
 SG_ current : 55|16@0- (1,0) [-32768|32767] "" Host

BO_ 1543 Respond_data_pack_1_N12_Fault: 8 Driver12
 SG_ position : 7|24@0- (1,0) [-8388608|8388607] "" Host
 SG_ speed : 31|24@0- (1,0) [-8388608|8388607] "" Host
 SG_ current : 55|16@0- (1,0) [-32768|32767] "" Host

BO_ 1600 Respond_data_hall_N12: 4 Driver12
 SG_ position : 7|24@0- (1,0) [-8388608|8388607] "" Host
 SG_ HALL_trigger : 31|1@0+ (1,0) [0|1] "" Host
 SG_ additional_pin2 : 30|1@0+ (1,0) [0|1] "" Host
 SG_ hall_index : 29|1@0+ (1,0) [0|1] "" Host

BO_ 1601 Respond_data_hall_N12_Fault: 4 Driver12
 SG_ position : 7|24@0- (1,0) [-8388608|8388607] "" Host
 SG_ HALL_trigger : 31|1@0+ (1,0) [0|1] "" Host
 SG_ additional_pin2 : 30|1@0+ (1,0) [0|1] "" Host
 SG_ hall_index : 29|1@0+ (1,0) [0|1] "" Host

BO_ 1568 Send_PD_Gains_N12: 8 Host
 SG_ KP : 7|32@0+ (1,0) [-3.402823466e+38|3.402823466e+38] "" Driver12
 SG_ KD : 39|32@0+ (1,0) [-3.402823466e+38|3.402823466e+38] "" Driver12

BO_ 1570 Send_Current_Gains_N12: 8 Host
 SG_ Kp_iq : 7|32@0+ (1,0) [-3.402823466e+38|3.402823466e+38] "" Driver12
 SG_ Ki_iq : 39|32@0+ (1,0) [-3.402823466e+38|3.402823466e+38] "" Driver12

BO_ 1572 Send_Velocity_Gains_N12: 8 Host
 SG_ Kpv : 7|32@0+ (1,0) [-3.402823466e+38|3.402823466e+38] "" Driver12
 SG_ Kiv : 39|32@0+ (1,0) [-3.402823466e+38|3.402823466e+38] "" Driver12

BO_ 1574 Send_Position_Gains_N12: 4 Host
 SG_ Kpp : 7|32@0+ (1,0) [-3.402823466e+38|3.402823466e+38] "" Driver12

BO_ 1576 Send_Limits_N12: 8 Host
 SG_ Speed_limit : 7|32@0+ (1,0) [-3.402823466e+38|3.402823466e+38] "" Driver12
 SG_ Current_limit : 39|32@0+ (1,0) [-3.402823466e+38|3.402823466e+38] "" Driver12

BO_ 1580 Send_Kt_N12: 4 Host
 SG_ Kt : 7|32@0+ (1,0) [-3.402823466e+38|3.402823466e+38] "" Driver12

BO_ 1604 Send_Voltage_Limit_N12: 4 Host
 SG_ Voltage_limit : 7|32@0- (1,0) [-2147483648|2147483647] "" Driver12

BO_ 1556 Send_Respond_Ping_N12: 0 Driver12

BO_ 1557 Send_Respond_Ping_N12_Fault: 0 Driver12

BO_ 1582 Send_Respond_Temperature_N12: 2 Driver12
 SG_ temperature : 7|16@0- (1,0) [-32768|32767] "" Host

BO_ 1583 Send_Respond_Temperatu_N12_Fault: 2 Driver12
 SG_ temperature : 7|16@0- (1,0) [-32768|32767] "" Host

BO_ 1584 Send_Respond_Voltage_N12: 2 Driver12
 SG_ voltage : 7|16@0+ (1,0) [0|65535] "" Host

BO_ 1585 Send_Respond_Voltage_N12_Fault: 2 Driver12
 SG_ voltage : 7|16@0+ (1,0) [0|65535] "" Host

BO_ 1586 Send_Respond_Device_Info_N12: 7 Driver12
 SG_ HARDWARE_VERSION : 7|8@0+ (1,0) [0|255] "" Host
 SG_ BATCH_DATE : 15|8@0+ (1,0) [0|255] "" Host
 SG_ SOFTWARE_VERSION : 23|8@0+ (1,0) [0|255] "" Host
 SG_ SERIAL_NUMBER : 31|32@0+ (1,0) [0|4294967295] "" Host

BO_ 1587 Send_Respond_Device_In_N12_Fault: 7 Driver12
 SG_ HARDWARE_VERSION : 7|8@0+ (1,0) [0|255] "" Host
 SG_ BATCH_DATE : 15|8@0+ (1,0) [0|255] "" Host
 SG_ SOFTWARE_VERSION : 23|8@0+ (1,0) [0|255] "" Host
 SG_ SERIAL_NUMBER : 31|32@0+ (1,0) [0|4294967295] "" Host

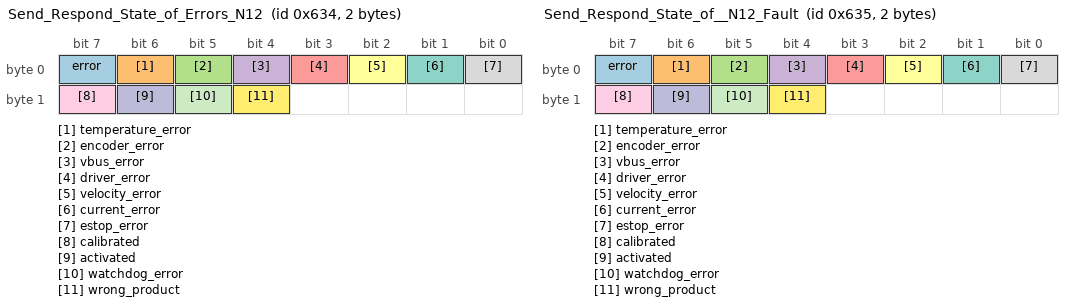
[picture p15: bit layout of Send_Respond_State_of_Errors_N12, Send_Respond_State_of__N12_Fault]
BO_ 1588 Send_Respond_State_of_Errors_N12: 2 Driver12
 SG_ error : 7|1@0+ (1,0) [0|1] "" Host
 SG_ temperature_error : 6|1@0+ (1,0) [0|1] "" Host
 SG_ encoder_error : 5|1@0+ (1,0) [0|1] "" Host
 SG_ vbus_error : 4|1@0+ (1,0) [0|1] "" Host
 SG_ driver_error : 3|1@0+ (1,0) [0|1] "" Host
 SG_ velocity_error : 2|1@0+ (1,0) [0|1] "" Host
 SG_ current_error : 1|1@0+ (1,0) [0|1] "" Host
 SG_ estop_error : 0|1@0+ (1,0) [0|1] "" Host
 SG_ calibrated : 15|1@0+ (1,0) [0|1] "" Host
 SG_ activated : 14|1@0+ (1,0) [0|1] "" Host
 SG_ watchdog_error : 13|1@0+ (1,0) [0|1] "" Host
 SG_ wrong_product : 12|1@0+ (1,0) [0|1] "" Host

BO_ 1589 Send_Respond_State_of__N12_Fault: 2 Driver12
 SG_ error : 7|1@0+ (1,0) [0|1] "" Host
 SG_ temperature_error : 6|1@0+ (1,0) [0|1] "" Host
 SG_ encoder_error : 5|1@0+ (1,0) [0|1] "" Host
 SG_ vbus_error : 4|1@0+ (1,0) [0|1] "" Host
 SG_ driver_error : 3|1@0+ (1,0) [0|1] "" Host
 SG_ velocity_error : 2|1@0+ (1,0) [0|1] "" Host
 SG_ current_error : 1|1@0+ (1,0) [0|1] "" Host
 SG_ estop_error : 0|1@0+ (1,0) [0|1] "" Host
 SG_ calibrated : 15|1@0+ (1,0) [0|1] "" Host
 SG_ activated : 14|1@0+ (1,0) [0|1] "" Host
 SG_ watchdog_error : 13|1@0+ (1,0) [0|1] "" Host
 SG_ wrong_product : 12|1@0+ (1,0) [0|1] "" Host

BO_ 1590 Send_Respond_Iq_data_N12: 2 Driver12
 SG_ current : 7|16@0- (1,0) [-32768|32767] "" Host

BO_ 1591 Send_Respond_Iq_data_N12_Fault: 2 Driver12
 SG_ current : 7|16@0- (1,0) [-32768|32767] "" Host

BO_ 1592 Send_Respond_Encoder_data_N12: 8 Driver12
 SG_ position : 7|32@0- (1,0) [-2147483648|2147483647] "" Host
 SG_ speed : 39|32@0- (1,0) [-2147483648|2147483647] "" Host

BO_ 1593 Send_Respond_Encoder_d_N12_Fault: 8 Driver12
 SG_ position : 7|32@0- (1,0) [-2147483648|2147483647] "" Host
 SG_ speed : 39|32@0- (1,0) [-2147483648|2147483647] "" Host

BO_ 1602 Send_Respond_Kt_N12: 4 Driver12
 SG_ Kt : 7|32@0+ (1,0) [-3.402823466e+38|3.402823466e+38] "" Host

BO_ 1603 Send_Respond_Kt_N12_Fault: 4 Driver12
 SG_ Kt : 7|32@0+ (1,0) [-3.402823466e+38|3.402823466e+38] "" Host

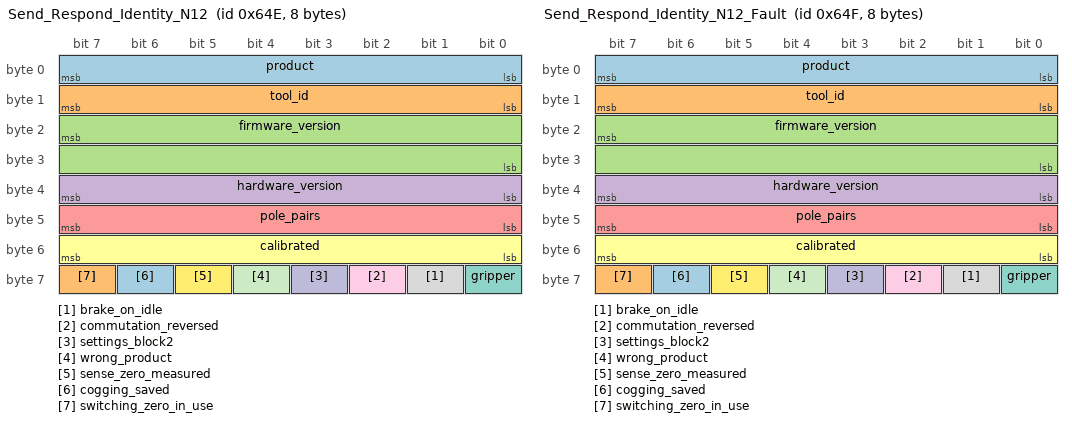
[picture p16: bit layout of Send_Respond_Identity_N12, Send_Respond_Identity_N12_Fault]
BO_ 1614 Send_Respond_Identity_N12: 8 Driver12
 SG_ product : 7|8@0+ (1,0) [0|255] "" Host
 SG_ tool_id : 15|8@0+ (1,0) [0|255] "" Host
 SG_ firmware_version : 23|16@0+ (1,0) [0|65535] "" Host
 SG_ hardware_version : 39|8@0+ (1,0) [0|255] "" Host
 SG_ pole_pairs : 47|8@0+ (1,0) [0|255] "" Host
 SG_ calibrated : 55|8@0+ (1,0) [0|255] "" Host
 SG_ gripper : 56|1@0+ (1,0) [0|1] "" Host
 SG_ brake_on_idle : 57|1@0+ (1,0) [0|1] "" Host
 SG_ commutation_reversed : 58|1@0+ (1,0) [0|1] "" Host
 SG_ settings_block2 : 59|1@0+ (1,0) [0|1] "" Host
 SG_ wrong_product : 60|1@0+ (1,0) [0|1] "" Host
 SG_ sense_zero_measured : 61|1@0+ (1,0) [0|1] "" Host
 SG_ cogging_saved : 62|1@0+ (1,0) [0|1] "" Host
 SG_ switching_zero_in_use : 63|1@0+ (1,0) [0|1] "" Host

BO_ 1615 Send_Respond_Identity_N12_Fault: 8 Driver12
 SG_ product : 7|8@0+ (1,0) [0|255] "" Host
 SG_ tool_id : 15|8@0+ (1,0) [0|255] "" Host
 SG_ firmware_version : 23|16@0+ (1,0) [0|65535] "" Host
 SG_ hardware_version : 39|8@0+ (1,0) [0|255] "" Host
 SG_ pole_pairs : 47|8@0+ (1,0) [0|255] "" Host
 SG_ calibrated : 55|8@0+ (1,0) [0|255] "" Host
 SG_ gripper : 56|1@0+ (1,0) [0|1] "" Host
 SG_ brake_on_idle : 57|1@0+ (1,0) [0|1] "" Host
 SG_ commutation_reversed : 58|1@0+ (1,0) [0|1] "" Host
 SG_ settings_block2 : 59|1@0+ (1,0) [0|1] "" Host
 SG_ wrong_product : 60|1@0+ (1,0) [0|1] "" Host
 SG_ sense_zero_measured : 61|1@0+ (1,0) [0|1] "" Host
 SG_ cogging_saved : 62|1@0+ (1,0) [0|1] "" Host
 SG_ switching_zero_in_use : 63|1@0+ (1,0) [0|1] "" Host

BO_ 1616 Send_Respond_Telemetry_N12: 8 Driver12
 SG_ temperature : 7|16@0- (1,0) [-32768|32767] "" Host
 SG_ voltage : 23|16@0- (1,0) [-32768|32767] "" Host
 SG_ errors_1 : 39|8@0+ (1,0) [0|255] "" Host
 SG_ errors_2 : 47|8@0+ (1,0) [0|255] "" Host
 SG_ current : 55|16@0- (1,0) [-32768|32767] "" Host

BO_ 1617 Send_Respond_Telemetry_N12_Fault: 8 Driver12
 SG_ temperature : 7|16@0- (1,0) [-32768|32767] "" Host
 SG_ voltage : 23|16@0- (1,0) [-32768|32767] "" Host
 SG_ errors_1 : 39|8@0+ (1,0) [0|255] "" Host
 SG_ errors_2 : 47|8@0+ (1,0) [0|255] "" Host
 SG_ current : 55|16@0- (1,0) [-32768|32767] "" Host

BO_ 1554 Respond_Heartbeat_N12: 0 Driver12

BO_ 1555 Respond_Heartbeat_N12_Fault: 0 Driver12

BO_ 1558 Send_CAN_ID_N12: 1 Host
 SG_ ID : 7|8@0+ (1,0) [0|255] "" Driver12

BO_ 1536 Send_ESTOP_N12: 0 Host

BO_ 1560 Send_Idle_N12: 0 Host

BO_ 1562 Send_Save_config_N12: 0 Host

BO_ 1564 Send_Reset_N12: 0 Host

BO_ 1538 Send_Clear_Error_N12: 0 Host

BO_ 1566 Send_Watchdog_N12: 5 Host
 SG_ Time : 7|32@0+ (1,0) [0|4294967295] "" Driver12
 SG_ Action : 39|8@0+ (1,0) [0|255] "" Driver12

BO_ 1596 Send_Heartbeat_Setup_N12: 4 Host
 SG_ Interval : 7|32@0+ (1,0) [0|4294967295] "" Driver12

BO_ 1606 Send_Settings_N12: 2 Host
 SG_ Mask : 7|8@0+ (1,0) [0|255] "" Driver12
 SG_ Value : 15|8@0+ (1,0) [0|255] "" Driver12

BO_ 1608 Send_Parameter_N12: 5 Host
 SG_ Parameter : 7|8@0+ (1,0) [0|255] "" Driver12
 SG_ Value : 15|32@0- (1,0) [-2147483648|2147483647] "" Driver12

BO_ 1610 Send_Get_Parameter_N12: 1 Host
 SG_ Parameter : 7|8@0+ (1,0) [0|255] "" Driver12

BO_ 1612 Respond_Parameter_N12: 5 Driver12
 SG_ parameter : 7|8@0+ (1,0) [0|255] "" Host
 SG_ value : 15|32@0- (1,0) [-2147483648|2147483647] "" Host

BO_ 1613 Respond_Parameter_N12_Fault: 5 Driver12
 SG_ parameter : 7|8@0+ (1,0) [0|255] "" Host
 SG_ value : 15|32@0- (1,0) [-2147483648|2147483647] "" Host

BO_ 1618 Send_Buffer_Read_N12: 5 Host
 SG_ Kind : 7|8@0+ (1,0) [0|255] "" Driver12
 SG_ First : 15|16@0+ (1,0) [0|65535] "" Driver12
 SG_ Count : 31|16@0+ (1,0) [0|65535] "" Driver12

BO_ 1620 Respond_Buffer_Data_N12: 8 Driver12
 SG_ header : 7|16@0+ (1,0) [0|65535] "" Host
 SG_ word_a : 23|16@0- (1,0) [-32768|32767] "" Host
 SG_ word_b : 39|16@0- (1,0) [-32768|32767] "" Host
 SG_ word_c : 55|16@0- (1,0) [-32768|32767] "" Host

BO_ 1621 Respond_Buffer_Data_N12_Fault: 8 Driver12
 SG_ header : 7|16@0+ (1,0) [0|65535] "" Host
 SG_ word_a : 23|16@0- (1,0) [-32768|32767] "" Host
 SG_ word_b : 39|16@0- (1,0) [-32768|32767] "" Host
 SG_ word_c : 55|16@0- (1,0) [-32768|32767] "" Host

BO_ 1622 Send_Buffer_Write_N12: 8 Host
 SG_ Header : 7|16@0+ (1,0) [0|65535] "" Driver12
 SG_ Word_A : 23|16@0- (1,0) [-32768|32767] "" Driver12
 SG_ Word_B : 39|16@0- (1,0) [-32768|32767] "" Driver12
 SG_ Word_C : 55|16@0- (1,0) [-32768|32767] "" Driver12

BO_ 1624 Send_Sound_N12: 8 Host
 SG_ Operation : 7|8@0+ (1,0) [0|255] "" Driver12
 SG_ Channel : 15|8@0+ (1,0) [0|255] "" Driver12
 SG_ A : 23|16@0+ (1,0) [0|65535] "" Driver12
 SG_ B : 39|16@0+ (1,0) [0|65535] "" Driver12
 SG_ C : 55|16@0+ (1,0) [0|65535] "" Driver12

BO_ 1626 Send_Sound_Samples_N12: 8 Host
 SG_ Sample_1 : 7|8@0- (1,0) [-128|127] "" Driver12
 SG_ Sample_2 : 15|8@0- (1,0) [-128|127] "" Driver12
 SG_ Sample_3 : 23|8@0- (1,0) [-128|127] "" Driver12
 SG_ Sample_4 : 31|8@0- (1,0) [-128|127] "" Driver12
 SG_ Sample_5 : 39|8@0- (1,0) [-128|127] "" Driver12
 SG_ Sample_6 : 47|8@0- (1,0) [-128|127] "" Driver12
 SG_ Sample_7 : 55|8@0- (1,0) [-128|127] "" Driver12
 SG_ Sample_8 : 63|8@0- (1,0) [-128|127] "" Driver12

BO_ 1658 Send_gripper_data_pack_N12: 5 Host
 SG_ Position : 7|8@0+ (1,0) [0|255] "" Driver12
 SG_ Speed : 15|8@0+ (1,0) [0|255] "" Driver12
 SG_ Current : 23|16@0- (1,0) [-32768|32767] "" Driver12
 SG_ Activate : 39|1@0+ (1,0) [0|1] "" Driver12
 SG_ Action : 38|1@0+ (1,0) [0|1] "" Driver12
 SG_ E_stop : 37|1@0+ (1,0) [0|1] "" Driver12
 SG_ Release_direction : 36|1@0+ (1,0) [0|1] "" Driver12

BO_ 1660 Send_gripper_calibrate_N12: 0 Host

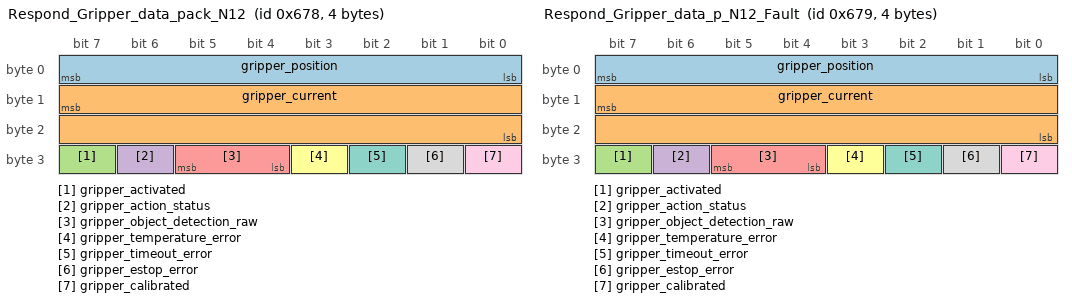
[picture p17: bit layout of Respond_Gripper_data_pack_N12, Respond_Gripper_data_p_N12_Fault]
BO_ 1656 Respond_Gripper_data_pack_N12: 4 Driver12
 SG_ gripper_position : 7|8@0+ (1,0) [0|255] "" Host
 SG_ gripper_current : 15|16@0- (1,0) [-32768|32767] "" Host
 SG_ gripper_activated : 31|1@0+ (1,0) [0|1] "" Host
 SG_ gripper_action_status : 30|1@0+ (1,0) [0|1] "" Host
 SG_ gripper_object_detection_raw : 29|2@0+ (1,0) [0|3] "" Host
 SG_ gripper_temperature_error : 27|1@0+ (1,0) [0|1] "" Host
 SG_ gripper_timeout_error : 26|1@0+ (1,0) [0|1] "" Host
 SG_ gripper_estop_error : 25|1@0+ (1,0) [0|1] "" Host
 SG_ gripper_calibrated : 24|1@0+ (1,0) [0|1] "" Host

BO_ 1657 Respond_Gripper_data_p_N12_Fault: 4 Driver12
 SG_ gripper_position : 7|8@0+ (1,0) [0|255] "" Host
 SG_ gripper_current : 15|16@0- (1,0) [-32768|32767] "" Host
 SG_ gripper_activated : 31|1@0+ (1,0) [0|1] "" Host
 SG_ gripper_action_status : 30|1@0+ (1,0) [0|1] "" Host
 SG_ gripper_object_detection_raw : 29|2@0+ (1,0) [0|3] "" Host
 SG_ gripper_temperature_error : 27|1@0+ (1,0) [0|1] "" Host
 SG_ gripper_timeout_error : 26|1@0+ (1,0) [0|1] "" Host
 SG_ gripper_estop_error : 25|1@0+ (1,0) [0|1] "" Host
 SG_ gripper_calibrated : 24|1@0+ (1,0) [0|1] "" Host

BO_ 1668 Send_data_pack_1_N13: 5 Host
 SG_ Speed_setpoint : 7|24@0- (1,0) [-8388608|8388607] "" Driver13
 SG_ Current_feedforward : 31|16@0- (1,0) [-32768|32767] "" Driver13

BO_ 1672 Send_data_pack_PD_N13: 8 Host
 SG_ Position_setpoint : 7|24@0- (1,0) [-8388608|8388607] "" Driver13
 SG_ Speed_setpoint : 31|24@0- (1,0) [-8388608|8388607] "" Driver13
 SG_ Current_feedforward : 55|16@0- (1,0) [-32768|32767] "" Driver13

BO_ 1726 Send_data_pack_HALL_N13: 4 Host
 SG_ Speed : 7|24@0- (1,0) [-8388608|8388607] "" Driver13
 SG_ Trigger : 31|8@0+ (1,0) [0|255] "" Driver13

BO_ 1670 Respond_data_pack_1_N13: 8 Driver13
 SG_ position : 7|24@0- (1,0) [-8388608|8388607] "" Host
 SG_ speed : 31|24@0- (1,0) [-8388608|8388607] "" Host
 SG_ current : 55|16@0- (1,0) [-32768|32767] "" Host

BO_ 1671 Respond_data_pack_1_N13_Fault: 8 Driver13
 SG_ position : 7|24@0- (1,0) [-8388608|8388607] "" Host
 SG_ speed : 31|24@0- (1,0) [-8388608|8388607] "" Host
 SG_ current : 55|16@0- (1,0) [-32768|32767] "" Host

BO_ 1728 Respond_data_hall_N13: 4 Driver13
 SG_ position : 7|24@0- (1,0) [-8388608|8388607] "" Host
 SG_ HALL_trigger : 31|1@0+ (1,0) [0|1] "" Host
 SG_ additional_pin2 : 30|1@0+ (1,0) [0|1] "" Host
 SG_ hall_index : 29|1@0+ (1,0) [0|1] "" Host

BO_ 1729 Respond_data_hall_N13_Fault: 4 Driver13
 SG_ position : 7|24@0- (1,0) [-8388608|8388607] "" Host
 SG_ HALL_trigger : 31|1@0+ (1,0) [0|1] "" Host
 SG_ additional_pin2 : 30|1@0+ (1,0) [0|1] "" Host
 SG_ hall_index : 29|1@0+ (1,0) [0|1] "" Host

BO_ 1696 Send_PD_Gains_N13: 8 Host
 SG_ KP : 7|32@0+ (1,0) [-3.402823466e+38|3.402823466e+38] "" Driver13
 SG_ KD : 39|32@0+ (1,0) [-3.402823466e+38|3.402823466e+38] "" Driver13

BO_ 1698 Send_Current_Gains_N13: 8 Host
 SG_ Kp_iq : 7|32@0+ (1,0) [-3.402823466e+38|3.402823466e+38] "" Driver13
 SG_ Ki_iq : 39|32@0+ (1,0) [-3.402823466e+38|3.402823466e+38] "" Driver13

BO_ 1700 Send_Velocity_Gains_N13: 8 Host
 SG_ Kpv : 7|32@0+ (1,0) [-3.402823466e+38|3.402823466e+38] "" Driver13
 SG_ Kiv : 39|32@0+ (1,0) [-3.402823466e+38|3.402823466e+38] "" Driver13

BO_ 1702 Send_Position_Gains_N13: 4 Host
 SG_ Kpp : 7|32@0+ (1,0) [-3.402823466e+38|3.402823466e+38] "" Driver13

BO_ 1704 Send_Limits_N13: 8 Host
 SG_ Speed_limit : 7|32@0+ (1,0) [-3.402823466e+38|3.402823466e+38] "" Driver13
 SG_ Current_limit : 39|32@0+ (1,0) [-3.402823466e+38|3.402823466e+38] "" Driver13

BO_ 1708 Send_Kt_N13: 4 Host
 SG_ Kt : 7|32@0+ (1,0) [-3.402823466e+38|3.402823466e+38] "" Driver13

BO_ 1732 Send_Voltage_Limit_N13: 4 Host
 SG_ Voltage_limit : 7|32@0- (1,0) [-2147483648|2147483647] "" Driver13

BO_ 1684 Send_Respond_Ping_N13: 0 Driver13

BO_ 1685 Send_Respond_Ping_N13_Fault: 0 Driver13

BO_ 1710 Send_Respond_Temperature_N13: 2 Driver13
 SG_ temperature : 7|16@0- (1,0) [-32768|32767] "" Host

BO_ 1711 Send_Respond_Temperatu_N13_Fault: 2 Driver13
 SG_ temperature : 7|16@0- (1,0) [-32768|32767] "" Host

BO_ 1712 Send_Respond_Voltage_N13: 2 Driver13
 SG_ voltage : 7|16@0+ (1,0) [0|65535] "" Host

BO_ 1713 Send_Respond_Voltage_N13_Fault: 2 Driver13
 SG_ voltage : 7|16@0+ (1,0) [0|65535] "" Host

BO_ 1714 Send_Respond_Device_Info_N13: 7 Driver13
 SG_ HARDWARE_VERSION : 7|8@0+ (1,0) [0|255] "" Host
 SG_ BATCH_DATE : 15|8@0+ (1,0) [0|255] "" Host
 SG_ SOFTWARE_VERSION : 23|8@0+ (1,0) [0|255] "" Host
 SG_ SERIAL_NUMBER : 31|32@0+ (1,0) [0|4294967295] "" Host

BO_ 1715 Send_Respond_Device_In_N13_Fault: 7 Driver13
 SG_ HARDWARE_VERSION : 7|8@0+ (1,0) [0|255] "" Host
 SG_ BATCH_DATE : 15|8@0+ (1,0) [0|255] "" Host
 SG_ SOFTWARE_VERSION : 23|8@0+ (1,0) [0|255] "" Host
 SG_ SERIAL_NUMBER : 31|32@0+ (1,0) [0|4294967295] "" Host

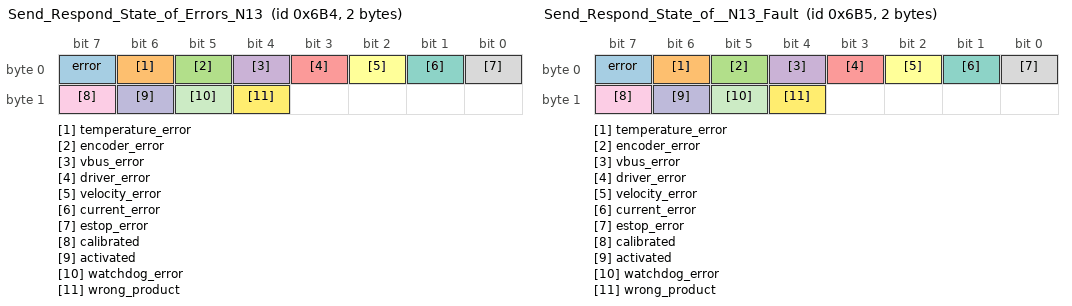
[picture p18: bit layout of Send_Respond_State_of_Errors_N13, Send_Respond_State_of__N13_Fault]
BO_ 1716 Send_Respond_State_of_Errors_N13: 2 Driver13
 SG_ error : 7|1@0+ (1,0) [0|1] "" Host
 SG_ temperature_error : 6|1@0+ (1,0) [0|1] "" Host
 SG_ encoder_error : 5|1@0+ (1,0) [0|1] "" Host
 SG_ vbus_error : 4|1@0+ (1,0) [0|1] "" Host
 SG_ driver_error : 3|1@0+ (1,0) [0|1] "" Host
 SG_ velocity_error : 2|1@0+ (1,0) [0|1] "" Host
 SG_ current_error : 1|1@0+ (1,0) [0|1] "" Host
 SG_ estop_error : 0|1@0+ (1,0) [0|1] "" Host
 SG_ calibrated : 15|1@0+ (1,0) [0|1] "" Host
 SG_ activated : 14|1@0+ (1,0) [0|1] "" Host
 SG_ watchdog_error : 13|1@0+ (1,0) [0|1] "" Host
 SG_ wrong_product : 12|1@0+ (1,0) [0|1] "" Host

BO_ 1717 Send_Respond_State_of__N13_Fault: 2 Driver13
 SG_ error : 7|1@0+ (1,0) [0|1] "" Host
 SG_ temperature_error : 6|1@0+ (1,0) [0|1] "" Host
 SG_ encoder_error : 5|1@0+ (1,0) [0|1] "" Host
 SG_ vbus_error : 4|1@0+ (1,0) [0|1] "" Host
 SG_ driver_error : 3|1@0+ (1,0) [0|1] "" Host
 SG_ velocity_error : 2|1@0+ (1,0) [0|1] "" Host
 SG_ current_error : 1|1@0+ (1,0) [0|1] "" Host
 SG_ estop_error : 0|1@0+ (1,0) [0|1] "" Host
 SG_ calibrated : 15|1@0+ (1,0) [0|1] "" Host
 SG_ activated : 14|1@0+ (1,0) [0|1] "" Host
 SG_ watchdog_error : 13|1@0+ (1,0) [0|1] "" Host
 SG_ wrong_product : 12|1@0+ (1,0) [0|1] "" Host

BO_ 1718 Send_Respond_Iq_data_N13: 2 Driver13
 SG_ current : 7|16@0- (1,0) [-32768|32767] "" Host

BO_ 1719 Send_Respond_Iq_data_N13_Fault: 2 Driver13
 SG_ current : 7|16@0- (1,0) [-32768|32767] "" Host

BO_ 1720 Send_Respond_Encoder_data_N13: 8 Driver13
 SG_ position : 7|32@0- (1,0) [-2147483648|2147483647] "" Host
 SG_ speed : 39|32@0- (1,0) [-2147483648|2147483647] "" Host

BO_ 1721 Send_Respond_Encoder_d_N13_Fault: 8 Driver13
 SG_ position : 7|32@0- (1,0) [-2147483648|2147483647] "" Host
 SG_ speed : 39|32@0- (1,0) [-2147483648|2147483647] "" Host

BO_ 1730 Send_Respond_Kt_N13: 4 Driver13
 SG_ Kt : 7|32@0+ (1,0) [-3.402823466e+38|3.402823466e+38] "" Host

BO_ 1731 Send_Respond_Kt_N13_Fault: 4 Driver13
 SG_ Kt : 7|32@0+ (1,0) [-3.402823466e+38|3.402823466e+38] "" Host

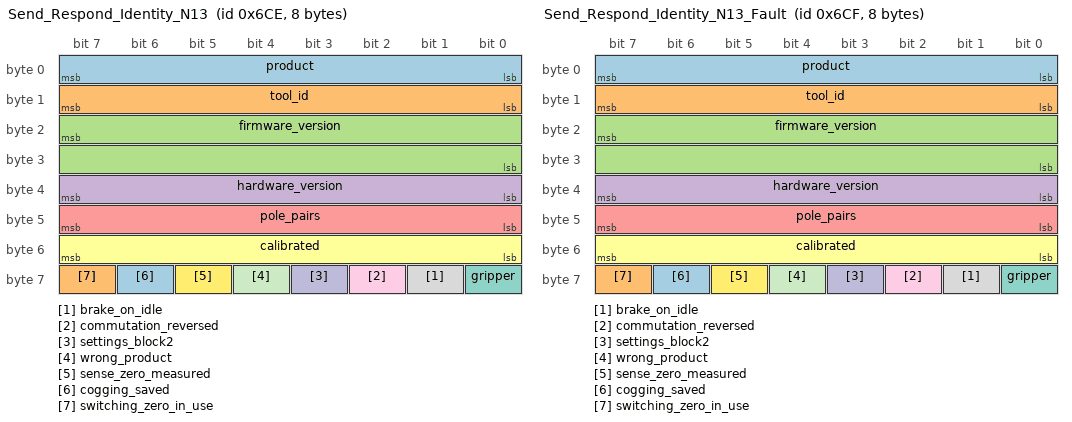
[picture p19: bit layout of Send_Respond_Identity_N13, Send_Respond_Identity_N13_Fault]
BO_ 1742 Send_Respond_Identity_N13: 8 Driver13
 SG_ product : 7|8@0+ (1,0) [0|255] "" Host
 SG_ tool_id : 15|8@0+ (1,0) [0|255] "" Host
 SG_ firmware_version : 23|16@0+ (1,0) [0|65535] "" Host
 SG_ hardware_version : 39|8@0+ (1,0) [0|255] "" Host
 SG_ pole_pairs : 47|8@0+ (1,0) [0|255] "" Host
 SG_ calibrated : 55|8@0+ (1,0) [0|255] "" Host
 SG_ gripper : 56|1@0+ (1,0) [0|1] "" Host
 SG_ brake_on_idle : 57|1@0+ (1,0) [0|1] "" Host
 SG_ commutation_reversed : 58|1@0+ (1,0) [0|1] "" Host
 SG_ settings_block2 : 59|1@0+ (1,0) [0|1] "" Host
 SG_ wrong_product : 60|1@0+ (1,0) [0|1] "" Host
 SG_ sense_zero_measured : 61|1@0+ (1,0) [0|1] "" Host
 SG_ cogging_saved : 62|1@0+ (1,0) [0|1] "" Host
 SG_ switching_zero_in_use : 63|1@0+ (1,0) [0|1] "" Host

BO_ 1743 Send_Respond_Identity_N13_Fault: 8 Driver13
 SG_ product : 7|8@0+ (1,0) [0|255] "" Host
 SG_ tool_id : 15|8@0+ (1,0) [0|255] "" Host
 SG_ firmware_version : 23|16@0+ (1,0) [0|65535] "" Host
 SG_ hardware_version : 39|8@0+ (1,0) [0|255] "" Host
 SG_ pole_pairs : 47|8@0+ (1,0) [0|255] "" Host
 SG_ calibrated : 55|8@0+ (1,0) [0|255] "" Host
 SG_ gripper : 56|1@0+ (1,0) [0|1] "" Host
 SG_ brake_on_idle : 57|1@0+ (1,0) [0|1] "" Host
 SG_ commutation_reversed : 58|1@0+ (1,0) [0|1] "" Host
 SG_ settings_block2 : 59|1@0+ (1,0) [0|1] "" Host
 SG_ wrong_product : 60|1@0+ (1,0) [0|1] "" Host
 SG_ sense_zero_measured : 61|1@0+ (1,0) [0|1] "" Host
 SG_ cogging_saved : 62|1@0+ (1,0) [0|1] "" Host
 SG_ switching_zero_in_use : 63|1@0+ (1,0) [0|1] "" Host

BO_ 1744 Send_Respond_Telemetry_N13: 8 Driver13
 SG_ temperature : 7|16@0- (1,0) [-32768|32767] "" Host
 SG_ voltage : 23|16@0- (1,0) [-32768|32767] "" Host
 SG_ errors_1 : 39|8@0+ (1,0) [0|255] "" Host
 SG_ errors_2 : 47|8@0+ (1,0) [0|255] "" Host
 SG_ current : 55|16@0- (1,0) [-32768|32767] "" Host

BO_ 1745 Send_Respond_Telemetry_N13_Fault: 8 Driver13
 SG_ temperature : 7|16@0- (1,0) [-32768|32767] "" Host
 SG_ voltage : 23|16@0- (1,0) [-32768|32767] "" Host
 SG_ errors_1 : 39|8@0+ (1,0) [0|255] "" Host
 SG_ errors_2 : 47|8@0+ (1,0) [0|255] "" Host
 SG_ current : 55|16@0- (1,0) [-32768|32767] "" Host

BO_ 1682 Respond_Heartbeat_N13: 0 Driver13

BO_ 1683 Respond_Heartbeat_N13_Fault: 0 Driver13

BO_ 1686 Send_CAN_ID_N13: 1 Host
 SG_ ID : 7|8@0+ (1,0) [0|255] "" Driver13

BO_ 1664 Send_ESTOP_N13: 0 Host

BO_ 1688 Send_Idle_N13: 0 Host

BO_ 1690 Send_Save_config_N13: 0 Host

BO_ 1692 Send_Reset_N13: 0 Host

BO_ 1666 Send_Clear_Error_N13: 0 Host

BO_ 1694 Send_Watchdog_N13: 5 Host
 SG_ Time : 7|32@0+ (1,0) [0|4294967295] "" Driver13
 SG_ Action : 39|8@0+ (1,0) [0|255] "" Driver13

BO_ 1724 Send_Heartbeat_Setup_N13: 4 Host
 SG_ Interval : 7|32@0+ (1,0) [0|4294967295] "" Driver13

BO_ 1734 Send_Settings_N13: 2 Host
 SG_ Mask : 7|8@0+ (1,0) [0|255] "" Driver13
 SG_ Value : 15|8@0+ (1,0) [0|255] "" Driver13

BO_ 1736 Send_Parameter_N13: 5 Host
 SG_ Parameter : 7|8@0+ (1,0) [0|255] "" Driver13
 SG_ Value : 15|32@0- (1,0) [-2147483648|2147483647] "" Driver13

BO_ 1738 Send_Get_Parameter_N13: 1 Host
 SG_ Parameter : 7|8@0+ (1,0) [0|255] "" Driver13

BO_ 1740 Respond_Parameter_N13: 5 Driver13
 SG_ parameter : 7|8@0+ (1,0) [0|255] "" Host
 SG_ value : 15|32@0- (1,0) [-2147483648|2147483647] "" Host

BO_ 1741 Respond_Parameter_N13_Fault: 5 Driver13
 SG_ parameter : 7|8@0+ (1,0) [0|255] "" Host
 SG_ value : 15|32@0- (1,0) [-2147483648|2147483647] "" Host

BO_ 1746 Send_Buffer_Read_N13: 5 Host
 SG_ Kind : 7|8@0+ (1,0) [0|255] "" Driver13
 SG_ First : 15|16@0+ (1,0) [0|65535] "" Driver13
 SG_ Count : 31|16@0+ (1,0) [0|65535] "" Driver13

BO_ 1748 Respond_Buffer_Data_N13: 8 Driver13
 SG_ header : 7|16@0+ (1,0) [0|65535] "" Host
 SG_ word_a : 23|16@0- (1,0) [-32768|32767] "" Host
 SG_ word_b : 39|16@0- (1,0) [-32768|32767] "" Host
 SG_ word_c : 55|16@0- (1,0) [-32768|32767] "" Host

BO_ 1749 Respond_Buffer_Data_N13_Fault: 8 Driver13
 SG_ header : 7|16@0+ (1,0) [0|65535] "" Host
 SG_ word_a : 23|16@0- (1,0) [-32768|32767] "" Host
 SG_ word_b : 39|16@0- (1,0) [-32768|32767] "" Host
 SG_ word_c : 55|16@0- (1,0) [-32768|32767] "" Host

BO_ 1750 Send_Buffer_Write_N13: 8 Host
 SG_ Header : 7|16@0+ (1,0) [0|65535] "" Driver13
 SG_ Word_A : 23|16@0- (1,0) [-32768|32767] "" Driver13
 SG_ Word_B : 39|16@0- (1,0) [-32768|32767] "" Driver13
 SG_ Word_C : 55|16@0- (1,0) [-32768|32767] "" Driver13

BO_ 1752 Send_Sound_N13: 8 Host
 SG_ Operation : 7|8@0+ (1,0) [0|255] "" Driver13
 SG_ Channel : 15|8@0+ (1,0) [0|255] "" Driver13
 SG_ A : 23|16@0+ (1,0) [0|65535] "" Driver13
 SG_ B : 39|16@0+ (1,0) [0|65535] "" Driver13
 SG_ C : 55|16@0+ (1,0) [0|65535] "" Driver13

BO_ 1754 Send_Sound_Samples_N13: 8 Host
 SG_ Sample_1 : 7|8@0- (1,0) [-128|127] "" Driver13
 SG_ Sample_2 : 15|8@0- (1,0) [-128|127] "" Driver13
 SG_ Sample_3 : 23|8@0- (1,0) [-128|127] "" Driver13
 SG_ Sample_4 : 31|8@0- (1,0) [-128|127] "" Driver13
 SG_ Sample_5 : 39|8@0- (1,0) [-128|127] "" Driver13
 SG_ Sample_6 : 47|8@0- (1,0) [-128|127] "" Driver13
 SG_ Sample_7 : 55|8@0- (1,0) [-128|127] "" Driver13
 SG_ Sample_8 : 63|8@0- (1,0) [-128|127] "" Driver13

BO_ 1786 Send_gripper_data_pack_N13: 5 Host
 SG_ Position : 7|8@0+ (1,0) [0|255] "" Driver13
 SG_ Speed : 15|8@0+ (1,0) [0|255] "" Driver13
 SG_ Current : 23|16@0- (1,0) [-32768|32767] "" Driver13
 SG_ Activate : 39|1@0+ (1,0) [0|1] "" Driver13
 SG_ Action : 38|1@0+ (1,0) [0|1] "" Driver13
 SG_ E_stop : 37|1@0+ (1,0) [0|1] "" Driver13
 SG_ Release_direction : 36|1@0+ (1,0) [0|1] "" Driver13

BO_ 1788 Send_gripper_calibrate_N13: 0 Host

BO_ 1784 Respond_Gripper_data_pack_N13: 4 Driver13
 SG_ gripper_position : 7|8@0+ (1,0) [0|255] "" Host
 SG_ gripper_current : 15|16@0- (1,0) [-32768|32767] "" Host
 SG_ gripper_activated : 31|1@0+ (1,0) [0|1] "" Host
 SG_ gripper_action_status : 30|1@0+ (1,0) [0|1] "" Host
 SG_ gripper_object_detection_raw : 29|2@0+ (1,0) [0|3] "" Host
 SG_ gripper_temperature_error : 27|1@0+ (1,0) [0|1] "" Host
 SG_ gripper_timeout_error : 26|1@0+ (1,0) [0|1] "" Host
 SG_ gripper_estop_error : 25|1@0+ (1,0) [0|1] "" Host
 SG_ gripper_calibrated : 24|1@0+ (1,0) [0|1] "" Host

BO_ 1785 Respond_Gripper_data_p_N13_Fault: 4 Driver13
 SG_ gripper_position : 7|8@0+ (1,0) [0|255] "" Host
 SG_ gripper_current : 15|16@0- (1,0) [-32768|32767] "" Host
 SG_ gripper_activated : 31|1@0+ (1,0) [0|1] "" Host
 SG_ gripper_action_status : 30|1@0+ (1,0) [0|1] "" Host
 SG_ gripper_object_detection_raw : 29|2@0+ (1,0) [0|3] "" Host
 SG_ gripper_temperature_error : 27|1@0+ (1,0) [0|1] "" Host
 SG_ gripper_timeout_error : 26|1@0+ (1,0) [0|1] "" Host
 SG_ gripper_estop_error : 25|1@0+ (1,0) [0|1] "" Host
 SG_ gripper_calibrated : 24|1@0+ (1,0) [0|1] "" Host

CM_ SG_ 960 position "encoder ticks";
CM_ SG_ 960 HALL_trigger "1 while the driver waits for the trigger (with a level trigger, also again after the pin left the level), 0 while it holds";
CM_ SG_ 960 additional_pin2 "the raw level of the ADDITIONAL2 pin";
CM_ SG_ 960 hall_index "1 once the trigger has been seen (latched)";
CM_ SG_ 961 position "encoder ticks";
CM_ SG_ 961 HALL_trigger "1 while the driver waits for the trigger (with a level trigger, also again after the pin left the level), 0 while it holds";
CM_ SG_ 961 additional_pin2 "the raw level of the ADDITIONAL2 pin";
CM_ SG_ 961 hall_index "1 once the trigger has been seen (latched)";
CM_ SG_ 936 Speed_limit "encoder ticks/s";
CM_ SG_ 936 Current_limit "mA";
CM_ SG_ 940 Kt "Nm/A";
CM_ SG_ 964 Voltage_limit "mV; 0 = Vbus";
CM_ SG_ 942 temperature "\u00b0C";
CM_ SG_ 943 temperature "\u00b0C";
CM_ SG_ 944 voltage "mV";
CM_ SG_ 945 voltage "mV";
CM_ SG_ 946 HARDWARE_VERSION "PCB revision";
CM_ SG_ 946 BATCH_DATE "production batch";
CM_ SG_ 946 SOFTWARE_VERSION "firmware release, e.g. 108";
CM_ SG_ 946 SERIAL_NUMBER "serial number as held in RAM: 1 after a power-up";
CM_ SG_ 947 HARDWARE_VERSION "PCB revision";
CM_ SG_ 947 BATCH_DATE "production batch";
CM_ SG_ 947 SOFTWARE_VERSION "firmware release, e.g. 108";
CM_ SG_ 947 SERIAL_NUMBER "serial number as held in RAM: 1 after a power-up";
CM_ SG_ 948 error "any error is active";
CM_ SG_ 948 temperature_error "motor over the temperature limit";
CM_ SG_ 948 encoder_error "the encoder reports no magnet (too weak a field)";
CM_ SG_ 948 vbus_error "supply voltage outside the limits";
CM_ SG_ 948 driver_error "reserved; never set by this firmware (STEPFOC does not read a fault output of its driver stage)";
CM_ SG_ 948 velocity_error "speed above 30,000,000 ticks/s, a fixed threshold (not #Vlimit)";
CM_ SG_ 948 current_error "reserved; never set by this firmware";
CM_ SG_ 948 estop_error "Send_ESTOP was received";
CM_ SG_ 948 calibrated "the motor is calibrated";
CM_ SG_ 948 activated "the controller is activated";
CM_ SG_ 948 watchdog_error "the watchdog ran out";
CM_ SG_ 948 wrong_product "from firmware 109: this firmware is on the other product's board (the product lock) and drives nothing";
CM_ SG_ 949 error "any error is active";
CM_ SG_ 949 temperature_error "motor over the temperature limit";
CM_ SG_ 949 encoder_error "the encoder reports no magnet (too weak a field)";
CM_ SG_ 949 vbus_error "supply voltage outside the limits";
CM_ SG_ 949 driver_error "reserved; never set by this firmware (STEPFOC does not read a fault output of its driver stage)";
CM_ SG_ 949 velocity_error "speed above 30,000,000 ticks/s, a fixed threshold (not #Vlimit)";
CM_ SG_ 949 current_error "reserved; never set by this firmware";
CM_ SG_ 949 estop_error "Send_ESTOP was received";
CM_ SG_ 949 calibrated "the motor is calibrated";
CM_ SG_ 949 activated "the controller is activated";
CM_ SG_ 949 watchdog_error "the watchdog ran out";
CM_ SG_ 949 wrong_product "from firmware 109: this firmware is on the other product's board (the product lock) and drives nothing";
CM_ SG_ 950 current "mA";
CM_ SG_ 951 current "mA";
CM_ SG_ 952 position "encoder ticks";
CM_ SG_ 952 speed "encoder ticks/s";
CM_ SG_ 953 position "encoder ticks";
CM_ SG_ 953 speed "encoder ticks/s";
CM_ SG_ 962 Kt "Nm/A";
CM_ SG_ 963 Kt "Nm/A";
CM_ SG_ 974 product "1 STEPFOC, 2 Spectral Micro: the firmware that answers";
CM_ SG_ 974 tool_id "parameter 1: 0 none, 1 SSG-48, 11-33 MSG, 200-254 your own";
CM_ SG_ 974 firmware_version "the release, e.g. 109";
CM_ SG_ 974 hardware_version "PCB revision from the EEPROM";
CM_ SG_ 974 pole_pairs "the motor's pole pairs; 0 if outside 0-255";
CM_ SG_ 974 calibrated "1 calibrated, 0 not";
CM_ SG_ 974 gripper "the driver is set up as a gripper (#Gripper 1)";
CM_ SG_ 974 brake_on_idle "idle brakes (1) or coasts (0)";
CM_ SG_ 974 commutation_reversed "calibration found the coils wired the other way round";
CM_ SG_ 974 settings_block2 "the EEPROM has the bank settings block 2 lives in, so parameters 1-5 can be saved";
CM_ SG_ 974 wrong_product "this firmware is on the other product's board (the product lock) and drives nothing";
CM_ SG_ 974 sense_zero_measured "the current-sense zero was measured at start-up and is plausible";
CM_ SG_ 974 cogging_saved "the anti-cogging in use is the one saved in the EEPROM";
CM_ SG_ 974 switching_zero_in_use "the current-sense zero measured with the bridge switching is in use (parameter 46)";
CM_ SG_ 975 product "1 STEPFOC, 2 Spectral Micro: the firmware that answers";
CM_ SG_ 975 tool_id "parameter 1: 0 none, 1 SSG-48, 11-33 MSG, 200-254 your own";
CM_ SG_ 975 firmware_version "the release, e.g. 109";
CM_ SG_ 975 hardware_version "PCB revision from the EEPROM";
CM_ SG_ 975 pole_pairs "the motor's pole pairs; 0 if outside 0-255";
CM_ SG_ 975 calibrated "1 calibrated, 0 not";
CM_ SG_ 975 gripper "the driver is set up as a gripper (#Gripper 1)";
CM_ SG_ 975 brake_on_idle "idle brakes (1) or coasts (0)";
CM_ SG_ 975 commutation_reversed "calibration found the coils wired the other way round";
CM_ SG_ 975 settings_block2 "the EEPROM has the bank settings block 2 lives in, so parameters 1-5 can be saved";
CM_ SG_ 975 wrong_product "this firmware is on the other product's board (the product lock) and drives nothing";
CM_ SG_ 975 sense_zero_measured "the current-sense zero was measured at start-up and is plausible";
CM_ SG_ 975 cogging_saved "the anti-cogging in use is the one saved in the EEPROM";
CM_ SG_ 975 switching_zero_in_use "the current-sense zero measured with the bridge switching is in use (parameter 46)";
CM_ SG_ 976 temperature "\u00b0C (meaningful with the thermistor enabled)";
CM_ SG_ 976 voltage "supply voltage in mV";
CM_ SG_ 976 errors_1 "the error flags, as byte 0 of Send_Respond_State_of_Errors";
CM_ SG_ 976 errors_2 "calibrated, activated, watchdog, wrong product, as byte 1 of Send_Respond_State_of_Errors";
CM_ SG_ 976 current "Iq in mA";
CM_ SG_ 977 temperature "\u00b0C (meaningful with the thermistor enabled)";
CM_ SG_ 977 voltage "supply voltage in mV";
CM_ SG_ 977 errors_1 "the error flags, as byte 0 of Send_Respond_State_of_Errors";
CM_ SG_ 977 errors_2 "calibrated, activated, watchdog, wrong product, as byte 1 of Send_Respond_State_of_Errors";
CM_ SG_ 977 current "Iq in mA";
CM_ SG_ 918 ID "0 to 13; 14 and 15 are accepted but reserved by the bootloader";
CM_ SG_ 926 Time "ms; 0 = off";
CM_ SG_ 926 Action "0 legacy (brake or coast as idle does), 1 hold the position, 2 brake, 3 coast, 4 descend at the fallback current and speed; other values act as 0";
CM_ SG_ 956 Interval "ms; 0 = off";
CM_ SG_ 966 Mask "bit 0 = write the idle behaviour";
CM_ SG_ 966 Value "bit 0: 1 brake, 0 coast";
CM_ SG_ 968 Parameter "the parameter number, 1-87";
CM_ SG_ 968 Value "the new value, in the parameter's unit; for the gains, limits and Kt (8-16, 20) a float's bit pattern";
CM_ SG_ 970 Parameter "the parameter number";
CM_ SG_ 972 parameter "the parameter number";
CM_ SG_ 972 value "the value in force; a float's bits for 8-16 and 20";
CM_ SG_ 973 parameter "the parameter number";
CM_ SG_ 973 value "the value in force; a float's bits for 8-16 and 20";
CM_ SG_ 978 Kind "0 capture (up to 1024 samples: parameter 32 says how many), 1 histogram (256 bins), 2 anti-cogging harmonics (8 slots), 3 anti-cogging table (256 values), 4 encoder table (128 values)";
CM_ SG_ 978 First "the first index";
CM_ SG_ 978 Count "how many entries; 0 cancels a read-out";
CM_ SG_ 980 header "kind \u00d7 8192 + index";
CM_ SG_ 980 word_a "capture: channel A; histogram: the count (unsigned); harmonics: the harmonic number (0 = slot unused); tables: entry index";
CM_ SG_ 980 word_b "capture: channel B; histogram: the sum's upper 16 bits; harmonics: a, the cosine term in mA; tables: entry index + 1";
CM_ SG_ 980 word_c "capture: channel C; histogram: the sum's lower 16 bits; harmonics: b, the sine term in mA; tables: entry index + 2 (0 past the end)";
CM_ SG_ 981 header "kind \u00d7 8192 + index";
CM_ SG_ 981 word_a "capture: channel A; histogram: the count (unsigned); harmonics: the harmonic number (0 = slot unused); tables: entry index";
CM_ SG_ 981 word_b "capture: channel B; histogram: the sum's upper 16 bits; harmonics: a, the cosine term in mA; tables: entry index + 1";
CM_ SG_ 981 word_c "capture: channel C; histogram: the sum's lower 16 bits; harmonics: b, the sine term in mA; tables: entry index + 2 (0 past the end)";
CM_ SG_ 982 Header "kind \u00d7 8192 + index; kind 2 or 3";
CM_ SG_ 982 Word_A "kind 2: the harmonic (1-32, 0 = unused); kind 3: value at index";
CM_ SG_ 982 Word_B "kind 2: a in mA; kind 3: value at index + 1";
CM_ SG_ 982 Word_C "kind 2: b in mA; kind 3: value at index + 2";
CM_ SG_ 984 Operation "0 stop everything (tones, queue, samples); 1 a tone now; 2 add an event to the queue; 3 play the queue; 4 play the samples; 5 samples off, buffer cleared; 6 clear the queue (tones that sound keep sounding)";
CM_ SG_ 984 Channel "the tone channel, 0-3 (operations 1 and 2)";
CM_ SG_ 984 A "1, 2: the pitch in Hz (2: 0 silences the channel); 4: the sample rate in Hz, at most the loop rate";
CM_ SG_ 984 B "1, 2: the loudness in mA; 4: the voltage of a full-scale sample in mV";
CM_ SG_ 984 C "1: the duration in ms, 0 = until stopped; 2: the wait in ms before the next event, 0 = the next one starts with it";
CM_ SG_ 986 Sample_1 "the next sample";
CM_ SG_ 1018 Position "0 fully open, 255 fully closed";
CM_ SG_ 1018 Speed "0 slowest, 255 fastest";
CM_ SG_ 1018 Current "current limit of the move in mA; from firmware 109 the move uses its magnitude, at most the driver's 2800 mA; see the gripper manual for the safe range";
CM_ SG_ 1018 Activate "1 activate the gripper, 0 deactivate";
CM_ SG_ 1018 Action "1 go to the position, 0 idle";
CM_ SG_ 1018 E_stop "1 raises the gripper E-stop error, again on every control cycle until a frame with this bit 0 arrives; then Send_Clear_Error";
CM_ SG_ 1018 Release_direction "read by the firmware but not used";
CM_ SG_ 1016 gripper_position "0 fully open, 255 fully closed";
CM_ SG_ 1016 gripper_current "measured current in mA";
CM_ SG_ 1016 gripper_activated "1 activated";
CM_ SG_ 1016 gripper_action_status "the action bit of the last Send_gripper_data_pack (1 after #Grippos); the driver never clears it, so it stays 1 after the move ends: the object detection tells when the move has ended";
CM_ SG_ 1016 gripper_object_detection_raw "bit 5 is the low bit, bit 4 the high bit: 0 moving, 1 object detected while closing, 2 object detected while opening, 3 at the position; raw bit pair, see value labels (wire order differs from numeric status)";
CM_ SG_ 1016 gripper_temperature_error "a copy of the thermistor temperature error";
CM_ SG_ 1016 gripper_timeout_error "a copy of the CAN watchdog error (Send_Watchdog), not a move timeout";
CM_ SG_ 1016 gripper_estop_error "the E-stop bit of Send_gripper_data_pack (or #Gripstop 1) was set";
CM_ SG_ 1016 gripper_calibrated "1 calibrated";
CM_ SG_ 1017 gripper_position "0 fully open, 255 fully closed";
CM_ SG_ 1017 gripper_current "measured current in mA";
CM_ SG_ 1017 gripper_activated "1 activated";
CM_ SG_ 1017 gripper_action_status "the action bit of the last Send_gripper_data_pack (1 after #Grippos); the driver never clears it, so it stays 1 after the move ends: the object detection tells when the move has ended";
CM_ SG_ 1017 gripper_object_detection_raw "bit 5 is the low bit, bit 4 the high bit: 0 moving, 1 object detected while closing, 2 object detected while opening, 3 at the position; raw bit pair, see value labels (wire order differs from numeric status)";
CM_ SG_ 1017 gripper_temperature_error "a copy of the thermistor temperature error";
CM_ SG_ 1017 gripper_timeout_error "a copy of the CAN watchdog error (Send_Watchdog), not a move timeout";
CM_ SG_ 1017 gripper_estop_error "the E-stop bit of Send_gripper_data_pack (or #Gripstop 1) was set";
CM_ SG_ 1017 gripper_calibrated "1 calibrated";
CM_ SG_ 1028 Speed_setpoint "encoder ticks/s";
CM_ SG_ 1028 Current_feedforward "mA";
CM_ SG_ 1032 Position_setpoint "encoder ticks";
CM_ SG_ 1032 Speed_setpoint "encoder ticks/s";
CM_ SG_ 1032 Current_feedforward "mA";
CM_ SG_ 1086 Speed "encoder ticks/s; the sign gives the direction";
CM_ SG_ 1086 Trigger "0 = trigger when the pin is low, 1 = when it is high, 2 = on any edge";
CM_ SG_ 1030 position "encoder ticks";
CM_ SG_ 1030 speed "encoder ticks/s";
CM_ SG_ 1030 current "Iq in mA";
CM_ SG_ 1031 position "encoder ticks";
CM_ SG_ 1031 speed "encoder ticks/s";
CM_ SG_ 1031 current "Iq in mA";
CM_ SG_ 1088 position "encoder ticks";
CM_ SG_ 1088 HALL_trigger "1 while the driver waits for the trigger (with a level trigger, also again after the pin left the level), 0 while it holds";
CM_ SG_ 1088 additional_pin2 "the raw level of the ADDITIONAL2 pin";
CM_ SG_ 1088 hall_index "1 once the trigger has been seen (latched)";
CM_ SG_ 1089 position "encoder ticks";
CM_ SG_ 1089 HALL_trigger "1 while the driver waits for the trigger (with a level trigger, also again after the pin left the level), 0 while it holds";
CM_ SG_ 1089 additional_pin2 "the raw level of the ADDITIONAL2 pin";
CM_ SG_ 1089 hall_index "1 once the trigger has been seen (latched)";
CM_ SG_ 1064 Speed_limit "encoder ticks/s";
CM_ SG_ 1064 Current_limit "mA";
CM_ SG_ 1068 Kt "Nm/A";
CM_ SG_ 1092 Voltage_limit "mV; 0 = Vbus";
CM_ SG_ 1070 temperature "\u00b0C";
CM_ SG_ 1071 temperature "\u00b0C";
CM_ SG_ 1072 voltage "mV";
CM_ SG_ 1073 voltage "mV";
CM_ SG_ 1074 HARDWARE_VERSION "PCB revision";
CM_ SG_ 1074 BATCH_DATE "production batch";
CM_ SG_ 1074 SOFTWARE_VERSION "firmware release, e.g. 108";
CM_ SG_ 1074 SERIAL_NUMBER "serial number as held in RAM: 1 after a power-up";
CM_ SG_ 1075 HARDWARE_VERSION "PCB revision";
CM_ SG_ 1075 BATCH_DATE "production batch";
CM_ SG_ 1075 SOFTWARE_VERSION "firmware release, e.g. 108";
CM_ SG_ 1075 SERIAL_NUMBER "serial number as held in RAM: 1 after a power-up";
CM_ SG_ 1076 error "any error is active";
CM_ SG_ 1076 temperature_error "motor over the temperature limit";
CM_ SG_ 1076 encoder_error "the encoder reports no magnet (too weak a field)";
CM_ SG_ 1076 vbus_error "supply voltage outside the limits";
CM_ SG_ 1076 driver_error "reserved; never set by this firmware (STEPFOC does not read a fault output of its driver stage)";
CM_ SG_ 1076 velocity_error "speed above 30,000,000 ticks/s, a fixed threshold (not #Vlimit)";
CM_ SG_ 1076 current_error "reserved; never set by this firmware";
CM_ SG_ 1076 estop_error "Send_ESTOP was received";
CM_ SG_ 1076 calibrated "the motor is calibrated";
CM_ SG_ 1076 activated "the controller is activated";
CM_ SG_ 1076 watchdog_error "the watchdog ran out";
CM_ SG_ 1076 wrong_product "from firmware 109: this firmware is on the other product's board (the product lock) and drives nothing";
CM_ SG_ 1077 error "any error is active";
CM_ SG_ 1077 temperature_error "motor over the temperature limit";
CM_ SG_ 1077 encoder_error "the encoder reports no magnet (too weak a field)";
CM_ SG_ 1077 vbus_error "supply voltage outside the limits";
CM_ SG_ 1077 driver_error "reserved; never set by this firmware (STEPFOC does not read a fault output of its driver stage)";
CM_ SG_ 1077 velocity_error "speed above 30,000,000 ticks/s, a fixed threshold (not #Vlimit)";
CM_ SG_ 1077 current_error "reserved; never set by this firmware";
CM_ SG_ 1077 estop_error "Send_ESTOP was received";
CM_ SG_ 1077 calibrated "the motor is calibrated";
CM_ SG_ 1077 activated "the controller is activated";
CM_ SG_ 1077 watchdog_error "the watchdog ran out";
CM_ SG_ 1077 wrong_product "from firmware 109: this firmware is on the other product's board (the product lock) and drives nothing";
CM_ SG_ 1078 current "mA";
CM_ SG_ 1079 current "mA";
CM_ SG_ 1080 position "encoder ticks";
CM_ SG_ 1080 speed "encoder ticks/s";
CM_ SG_ 1081 position "encoder ticks";
CM_ SG_ 1081 speed "encoder ticks/s";
CM_ SG_ 1090 Kt "Nm/A";
CM_ SG_ 1091 Kt "Nm/A";
CM_ SG_ 1102 product "1 STEPFOC, 2 Spectral Micro: the firmware that answers";
CM_ SG_ 1102 tool_id "parameter 1: 0 none, 1 SSG-48, 11-33 MSG, 200-254 your own";
CM_ SG_ 1102 firmware_version "the release, e.g. 109";
CM_ SG_ 1102 hardware_version "PCB revision from the EEPROM";
CM_ SG_ 1102 pole_pairs "the motor's pole pairs; 0 if outside 0-255";
CM_ SG_ 1102 calibrated "1 calibrated, 0 not";
CM_ SG_ 1102 gripper "the driver is set up as a gripper (#Gripper 1)";
CM_ SG_ 1102 brake_on_idle "idle brakes (1) or coasts (0)";
CM_ SG_ 1102 commutation_reversed "calibration found the coils wired the other way round";
CM_ SG_ 1102 settings_block2 "the EEPROM has the bank settings block 2 lives in, so parameters 1-5 can be saved";
CM_ SG_ 1102 wrong_product "this firmware is on the other product's board (the product lock) and drives nothing";
CM_ SG_ 1102 sense_zero_measured "the current-sense zero was measured at start-up and is plausible";
CM_ SG_ 1102 cogging_saved "the anti-cogging in use is the one saved in the EEPROM";
CM_ SG_ 1102 switching_zero_in_use "the current-sense zero measured with the bridge switching is in use (parameter 46)";
CM_ SG_ 1103 product "1 STEPFOC, 2 Spectral Micro: the firmware that answers";
CM_ SG_ 1103 tool_id "parameter 1: 0 none, 1 SSG-48, 11-33 MSG, 200-254 your own";
CM_ SG_ 1103 firmware_version "the release, e.g. 109";
CM_ SG_ 1103 hardware_version "PCB revision from the EEPROM";
CM_ SG_ 1103 pole_pairs "the motor's pole pairs; 0 if outside 0-255";
CM_ SG_ 1103 calibrated "1 calibrated, 0 not";
CM_ SG_ 1103 gripper "the driver is set up as a gripper (#Gripper 1)";
CM_ SG_ 1103 brake_on_idle "idle brakes (1) or coasts (0)";
CM_ SG_ 1103 commutation_reversed "calibration found the coils wired the other way round";
CM_ SG_ 1103 settings_block2 "the EEPROM has the bank settings block 2 lives in, so parameters 1-5 can be saved";
CM_ SG_ 1103 wrong_product "this firmware is on the other product's board (the product lock) and drives nothing";
CM_ SG_ 1103 sense_zero_measured "the current-sense zero was measured at start-up and is plausible";
CM_ SG_ 1103 cogging_saved "the anti-cogging in use is the one saved in the EEPROM";
CM_ SG_ 1103 switching_zero_in_use "the current-sense zero measured with the bridge switching is in use (parameter 46)";
CM_ SG_ 1104 temperature "\u00b0C (meaningful with the thermistor enabled)";
CM_ SG_ 1104 voltage "supply voltage in mV";
CM_ SG_ 1104 errors_1 "the error flags, as byte 0 of Send_Respond_State_of_Errors";
CM_ SG_ 1104 errors_2 "calibrated, activated, watchdog, wrong product, as byte 1 of Send_Respond_State_of_Errors";
CM_ SG_ 1104 current "Iq in mA";
CM_ SG_ 1105 temperature "\u00b0C (meaningful with the thermistor enabled)";
CM_ SG_ 1105 voltage "supply voltage in mV";
CM_ SG_ 1105 errors_1 "the error flags, as byte 0 of Send_Respond_State_of_Errors";
CM_ SG_ 1105 errors_2 "calibrated, activated, watchdog, wrong product, as byte 1 of Send_Respond_State_of_Errors";
CM_ SG_ 1105 current "Iq in mA";
CM_ SG_ 1046 ID "0 to 13; 14 and 15 are accepted but reserved by the bootloader";
CM_ SG_ 1054 Time "ms; 0 = off";
CM_ SG_ 1054 Action "0 legacy (brake or coast as idle does), 1 hold the position, 2 brake, 3 coast, 4 descend at the fallback current and speed; other values act as 0";
CM_ SG_ 1084 Interval "ms; 0 = off";
CM_ SG_ 1094 Mask "bit 0 = write the idle behaviour";
CM_ SG_ 1094 Value "bit 0: 1 brake, 0 coast";
CM_ SG_ 1096 Parameter "the parameter number, 1-87";
CM_ SG_ 1096 Value "the new value, in the parameter's unit; for the gains, limits and Kt (8-16, 20) a float's bit pattern";
CM_ SG_ 1098 Parameter "the parameter number";
CM_ SG_ 1100 parameter "the parameter number";
CM_ SG_ 1100 value "the value in force; a float's bits for 8-16 and 20";
CM_ SG_ 1101 parameter "the parameter number";
CM_ SG_ 1101 value "the value in force; a float's bits for 8-16 and 20";
CM_ SG_ 1106 Kind "0 capture (up to 1024 samples: parameter 32 says how many), 1 histogram (256 bins), 2 anti-cogging harmonics (8 slots), 3 anti-cogging table (256 values), 4 encoder table (128 values)";
CM_ SG_ 1106 First "the first index";
CM_ SG_ 1106 Count "how many entries; 0 cancels a read-out";
CM_ SG_ 1108 header "kind \u00d7 8192 + index";
CM_ SG_ 1108 word_a "capture: channel A; histogram: the count (unsigned); harmonics: the harmonic number (0 = slot unused); tables: entry index";
CM_ SG_ 1108 word_b "capture: channel B; histogram: the sum's upper 16 bits; harmonics: a, the cosine term in mA; tables: entry index + 1";
CM_ SG_ 1108 word_c "capture: channel C; histogram: the sum's lower 16 bits; harmonics: b, the sine term in mA; tables: entry index + 2 (0 past the end)";
CM_ SG_ 1109 header "kind \u00d7 8192 + index";
CM_ SG_ 1109 word_a "capture: channel A; histogram: the count (unsigned); harmonics: the harmonic number (0 = slot unused); tables: entry index";
CM_ SG_ 1109 word_b "capture: channel B; histogram: the sum's upper 16 bits; harmonics: a, the cosine term in mA; tables: entry index + 1";
CM_ SG_ 1109 word_c "capture: channel C; histogram: the sum's lower 16 bits; harmonics: b, the sine term in mA; tables: entry index + 2 (0 past the end)";
CM_ SG_ 1110 Header "kind \u00d7 8192 + index; kind 2 or 3";
CM_ SG_ 1110 Word_A "kind 2: the harmonic (1-32, 0 = unused); kind 3: value at index";
CM_ SG_ 1110 Word_B "kind 2: a in mA; kind 3: value at index + 1";
CM_ SG_ 1110 Word_C "kind 2: b in mA; kind 3: value at index + 2";
CM_ SG_ 1112 Operation "0 stop everything (tones, queue, samples); 1 a tone now; 2 add an event to the queue; 3 play the queue; 4 play the samples; 5 samples off, buffer cleared; 6 clear the queue (tones that sound keep sounding)";
CM_ SG_ 1112 Channel "the tone channel, 0-3 (operations 1 and 2)";
CM_ SG_ 1112 A "1, 2: the pitch in Hz (2: 0 silences the channel); 4: the sample rate in Hz, at most the loop rate";
CM_ SG_ 1112 B "1, 2: the loudness in mA; 4: the voltage of a full-scale sample in mV";
CM_ SG_ 1112 C "1: the duration in ms, 0 = until stopped; 2: the wait in ms before the next event, 0 = the next one starts with it";
CM_ SG_ 1114 Sample_1 "the next sample";
CM_ SG_ 1146 Position "0 fully open, 255 fully closed";
CM_ SG_ 1146 Speed "0 slowest, 255 fastest";
CM_ SG_ 1146 Current "current limit of the move in mA; from firmware 109 the move uses its magnitude, at most the driver's 2800 mA; see the gripper manual for the safe range";
CM_ SG_ 1146 Activate "1 activate the gripper, 0 deactivate";
CM_ SG_ 1146 Action "1 go to the position, 0 idle";
CM_ SG_ 1146 E_stop "1 raises the gripper E-stop error, again on every control cycle until a frame with this bit 0 arrives; then Send_Clear_Error";
CM_ SG_ 1146 Release_direction "read by the firmware but not used";
CM_ SG_ 1144 gripper_position "0 fully open, 255 fully closed";
CM_ SG_ 1144 gripper_current "measured current in mA";
CM_ SG_ 1144 gripper_activated "1 activated";
CM_ SG_ 1144 gripper_action_status "the action bit of the last Send_gripper_data_pack (1 after #Grippos); the driver never clears it, so it stays 1 after the move ends: the object detection tells when the move has ended";
CM_ SG_ 1144 gripper_object_detection_raw "bit 5 is the low bit, bit 4 the high bit: 0 moving, 1 object detected while closing, 2 object detected while opening, 3 at the position; raw bit pair, see value labels (wire order differs from numeric status)";
CM_ SG_ 1144 gripper_temperature_error "a copy of the thermistor temperature error";
CM_ SG_ 1144 gripper_timeout_error "a copy of the CAN watchdog error (Send_Watchdog), not a move timeout";
CM_ SG_ 1144 gripper_estop_error "the E-stop bit of Send_gripper_data_pack (or #Gripstop 1) was set";
CM_ SG_ 1144 gripper_calibrated "1 calibrated";
CM_ SG_ 1145 gripper_position "0 fully open, 255 fully closed";
CM_ SG_ 1145 gripper_current "measured current in mA";
CM_ SG_ 1145 gripper_activated "1 activated";
CM_ SG_ 1145 gripper_action_status "the action bit of the last Send_gripper_data_pack (1 after #Grippos); the driver never clears it, so it stays 1 after the move ends: the object detection tells when the move has ended";
CM_ SG_ 1145 gripper_object_detection_raw "bit 5 is the low bit, bit 4 the high bit: 0 moving, 1 object detected while closing, 2 object detected while opening, 3 at the position; raw bit pair, see value labels (wire order differs from numeric status)";
CM_ SG_ 1145 gripper_temperature_error "a copy of the thermistor temperature error";
CM_ SG_ 1145 gripper_timeout_error "a copy of the CAN watchdog error (Send_Watchdog), not a move timeout";
CM_ SG_ 1145 gripper_estop_error "the E-stop bit of Send_gripper_data_pack (or #Gripstop 1) was set";
CM_ SG_ 1145 gripper_calibrated "1 calibrated";
CM_ SG_ 1156 Speed_setpoint "encoder ticks/s";
CM_ SG_ 1156 Current_feedforward "mA";
CM_ SG_ 1160 Position_setpoint "encoder ticks";
CM_ SG_ 1160 Speed_setpoint "encoder ticks/s";
CM_ SG_ 1160 Current_feedforward "mA";
CM_ SG_ 1214 Speed "encoder ticks/s; the sign gives the direction";
CM_ SG_ 1214 Trigger "0 = trigger when the pin is low, 1 = when it is high, 2 = on any edge";
CM_ SG_ 1158 position "encoder ticks";
CM_ SG_ 1158 speed "encoder ticks/s";
CM_ SG_ 1158 current "Iq in mA";
CM_ SG_ 1159 position "encoder ticks";
CM_ SG_ 1159 speed "encoder ticks/s";
CM_ SG_ 1159 current "Iq in mA";
CM_ SG_ 1216 position "encoder ticks";
CM_ SG_ 1216 HALL_trigger "1 while the driver waits for the trigger (with a level trigger, also again after the pin left the level), 0 while it holds";
CM_ SG_ 1216 additional_pin2 "the raw level of the ADDITIONAL2 pin";
CM_ SG_ 1216 hall_index "1 once the trigger has been seen (latched)";
CM_ SG_ 1217 position "encoder ticks";
CM_ SG_ 1217 HALL_trigger "1 while the driver waits for the trigger (with a level trigger, also again after the pin left the level), 0 while it holds";
CM_ SG_ 1217 additional_pin2 "the raw level of the ADDITIONAL2 pin";
CM_ SG_ 1217 hall_index "1 once the trigger has been seen (latched)";
CM_ SG_ 1192 Speed_limit "encoder ticks/s";
CM_ SG_ 1192 Current_limit "mA";
CM_ SG_ 1196 Kt "Nm/A";
CM_ SG_ 1220 Voltage_limit "mV; 0 = Vbus";
CM_ SG_ 1198 temperature "\u00b0C";
CM_ SG_ 1199 temperature "\u00b0C";
CM_ SG_ 1200 voltage "mV";
CM_ SG_ 1201 voltage "mV";
CM_ SG_ 1202 HARDWARE_VERSION "PCB revision";
CM_ SG_ 1202 BATCH_DATE "production batch";
CM_ SG_ 1202 SOFTWARE_VERSION "firmware release, e.g. 108";
CM_ SG_ 1202 SERIAL_NUMBER "serial number as held in RAM: 1 after a power-up";
CM_ SG_ 1203 HARDWARE_VERSION "PCB revision";
CM_ SG_ 1203 BATCH_DATE "production batch";
CM_ SG_ 1203 SOFTWARE_VERSION "firmware release, e.g. 108";
CM_ SG_ 1203 SERIAL_NUMBER "serial number as held in RAM: 1 after a power-up";
CM_ SG_ 1204 error "any error is active";
CM_ SG_ 1204 temperature_error "motor over the temperature limit";
CM_ SG_ 1204 encoder_error "the encoder reports no magnet (too weak a field)";
CM_ SG_ 1204 vbus_error "supply voltage outside the limits";
CM_ SG_ 1204 driver_error "reserved; never set by this firmware (STEPFOC does not read a fault output of its driver stage)";
CM_ SG_ 1204 velocity_error "speed above 30,000,000 ticks/s, a fixed threshold (not #Vlimit)";
CM_ SG_ 1204 current_error "reserved; never set by this firmware";
CM_ SG_ 1204 estop_error "Send_ESTOP was received";
CM_ SG_ 1204 calibrated "the motor is calibrated";
CM_ SG_ 1204 activated "the controller is activated";
CM_ SG_ 1204 watchdog_error "the watchdog ran out";
CM_ SG_ 1204 wrong_product "from firmware 109: this firmware is on the other product's board (the product lock) and drives nothing";
CM_ SG_ 1205 error "any error is active";
CM_ SG_ 1205 temperature_error "motor over the temperature limit";
CM_ SG_ 1205 encoder_error "the encoder reports no magnet (too weak a field)";
CM_ SG_ 1205 vbus_error "supply voltage outside the limits";
CM_ SG_ 1205 driver_error "reserved; never set by this firmware (STEPFOC does not read a fault output of its driver stage)";
CM_ SG_ 1205 velocity_error "speed above 30,000,000 ticks/s, a fixed threshold (not #Vlimit)";
CM_ SG_ 1205 current_error "reserved; never set by this firmware";
CM_ SG_ 1205 estop_error "Send_ESTOP was received";
CM_ SG_ 1205 calibrated "the motor is calibrated";
CM_ SG_ 1205 activated "the controller is activated";
CM_ SG_ 1205 watchdog_error "the watchdog ran out";
CM_ SG_ 1205 wrong_product "from firmware 109: this firmware is on the other product's board (the product lock) and drives nothing";
CM_ SG_ 1206 current "mA";
CM_ SG_ 1207 current "mA";
CM_ SG_ 1208 position "encoder ticks";
CM_ SG_ 1208 speed "encoder ticks/s";
CM_ SG_ 1209 position "encoder ticks";
CM_ SG_ 1209 speed "encoder ticks/s";
CM_ SG_ 1218 Kt "Nm/A";
CM_ SG_ 1219 Kt "Nm/A";
CM_ SG_ 1230 product "1 STEPFOC, 2 Spectral Micro: the firmware that answers";
CM_ SG_ 1230 tool_id "parameter 1: 0 none, 1 SSG-48, 11-33 MSG, 200-254 your own";
CM_ SG_ 1230 firmware_version "the release, e.g. 109";
CM_ SG_ 1230 hardware_version "PCB revision from the EEPROM";
CM_ SG_ 1230 pole_pairs "the motor's pole pairs; 0 if outside 0-255";
CM_ SG_ 1230 calibrated "1 calibrated, 0 not";
CM_ SG_ 1230 gripper "the driver is set up as a gripper (#Gripper 1)";
CM_ SG_ 1230 brake_on_idle "idle brakes (1) or coasts (0)";
CM_ SG_ 1230 commutation_reversed "calibration found the coils wired the other way round";
CM_ SG_ 1230 settings_block2 "the EEPROM has the bank settings block 2 lives in, so parameters 1-5 can be saved";
CM_ SG_ 1230 wrong_product "this firmware is on the other product's board (the product lock) and drives nothing";
CM_ SG_ 1230 sense_zero_measured "the current-sense zero was measured at start-up and is plausible";
CM_ SG_ 1230 cogging_saved "the anti-cogging in use is the one saved in the EEPROM";
CM_ SG_ 1230 switching_zero_in_use "the current-sense zero measured with the bridge switching is in use (parameter 46)";
CM_ SG_ 1231 product "1 STEPFOC, 2 Spectral Micro: the firmware that answers";
CM_ SG_ 1231 tool_id "parameter 1: 0 none, 1 SSG-48, 11-33 MSG, 200-254 your own";
CM_ SG_ 1231 firmware_version "the release, e.g. 109";
CM_ SG_ 1231 hardware_version "PCB revision from the EEPROM";
CM_ SG_ 1231 pole_pairs "the motor's pole pairs; 0 if outside 0-255";
CM_ SG_ 1231 calibrated "1 calibrated, 0 not";
CM_ SG_ 1231 gripper "the driver is set up as a gripper (#Gripper 1)";
CM_ SG_ 1231 brake_on_idle "idle brakes (1) or coasts (0)";
CM_ SG_ 1231 commutation_reversed "calibration found the coils wired the other way round";
CM_ SG_ 1231 settings_block2 "the EEPROM has the bank settings block 2 lives in, so parameters 1-5 can be saved";
CM_ SG_ 1231 wrong_product "this firmware is on the other product's board (the product lock) and drives nothing";
CM_ SG_ 1231 sense_zero_measured "the current-sense zero was measured at start-up and is plausible";
CM_ SG_ 1231 cogging_saved "the anti-cogging in use is the one saved in the EEPROM";
CM_ SG_ 1231 switching_zero_in_use "the current-sense zero measured with the bridge switching is in use (parameter 46)";
CM_ SG_ 1232 temperature "\u00b0C (meaningful with the thermistor enabled)";
CM_ SG_ 1232 voltage "supply voltage in mV";
CM_ SG_ 1232 errors_1 "the error flags, as byte 0 of Send_Respond_State_of_Errors";
CM_ SG_ 1232 errors_2 "calibrated, activated, watchdog, wrong product, as byte 1 of Send_Respond_State_of_Errors";
CM_ SG_ 1232 current "Iq in mA";
CM_ SG_ 1233 temperature "\u00b0C (meaningful with the thermistor enabled)";
CM_ SG_ 1233 voltage "supply voltage in mV";
CM_ SG_ 1233 errors_1 "the error flags, as byte 0 of Send_Respond_State_of_Errors";
CM_ SG_ 1233 errors_2 "calibrated, activated, watchdog, wrong product, as byte 1 of Send_Respond_State_of_Errors";
CM_ SG_ 1233 current "Iq in mA";
CM_ SG_ 1174 ID "0 to 13; 14 and 15 are accepted but reserved by the bootloader";
CM_ SG_ 1182 Time "ms; 0 = off";
CM_ SG_ 1182 Action "0 legacy (brake or coast as idle does), 1 hold the position, 2 brake, 3 coast, 4 descend at the fallback current and speed; other values act as 0";
CM_ SG_ 1212 Interval "ms; 0 = off";
CM_ SG_ 1222 Mask "bit 0 = write the idle behaviour";
CM_ SG_ 1222 Value "bit 0: 1 brake, 0 coast";
CM_ SG_ 1224 Parameter "the parameter number, 1-87";
CM_ SG_ 1224 Value "the new value, in the parameter's unit; for the gains, limits and Kt (8-16, 20) a float's bit pattern";
CM_ SG_ 1226 Parameter "the parameter number";
CM_ SG_ 1228 parameter "the parameter number";
CM_ SG_ 1228 value "the value in force; a float's bits for 8-16 and 20";
CM_ SG_ 1229 parameter "the parameter number";
CM_ SG_ 1229 value "the value in force; a float's bits for 8-16 and 20";
CM_ SG_ 1234 Kind "0 capture (up to 1024 samples: parameter 32 says how many), 1 histogram (256 bins), 2 anti-cogging harmonics (8 slots), 3 anti-cogging table (256 values), 4 encoder table (128 values)";
CM_ SG_ 1234 First "the first index";
CM_ SG_ 1234 Count "how many entries; 0 cancels a read-out";
CM_ SG_ 1236 header "kind \u00d7 8192 + index";
CM_ SG_ 1236 word_a "capture: channel A; histogram: the count (unsigned); harmonics: the harmonic number (0 = slot unused); tables: entry index";
CM_ SG_ 1236 word_b "capture: channel B; histogram: the sum's upper 16 bits; harmonics: a, the cosine term in mA; tables: entry index + 1";
CM_ SG_ 1236 word_c "capture: channel C; histogram: the sum's lower 16 bits; harmonics: b, the sine term in mA; tables: entry index + 2 (0 past the end)";
CM_ SG_ 1237 header "kind \u00d7 8192 + index";
CM_ SG_ 1237 word_a "capture: channel A; histogram: the count (unsigned); harmonics: the harmonic number (0 = slot unused); tables: entry index";
CM_ SG_ 1237 word_b "capture: channel B; histogram: the sum's upper 16 bits; harmonics: a, the cosine term in mA; tables: entry index + 1";
CM_ SG_ 1237 word_c "capture: channel C; histogram: the sum's lower 16 bits; harmonics: b, the sine term in mA; tables: entry index + 2 (0 past the end)";
CM_ SG_ 1238 Header "kind \u00d7 8192 + index; kind 2 or 3";
CM_ SG_ 1238 Word_A "kind 2: the harmonic (1-32, 0 = unused); kind 3: value at index";
CM_ SG_ 1238 Word_B "kind 2: a in mA; kind 3: value at index + 1";
CM_ SG_ 1238 Word_C "kind 2: b in mA; kind 3: value at index + 2";
CM_ SG_ 1240 Operation "0 stop everything (tones, queue, samples); 1 a tone now; 2 add an event to the queue; 3 play the queue; 4 play the samples; 5 samples off, buffer cleared; 6 clear the queue (tones that sound keep sounding)";
CM_ SG_ 1240 Channel "the tone channel, 0-3 (operations 1 and 2)";
CM_ SG_ 1240 A "1, 2: the pitch in Hz (2: 0 silences the channel); 4: the sample rate in Hz, at most the loop rate";
CM_ SG_ 1240 B "1, 2: the loudness in mA; 4: the voltage of a full-scale sample in mV";
CM_ SG_ 1240 C "1: the duration in ms, 0 = until stopped; 2: the wait in ms before the next event, 0 = the next one starts with it";
CM_ SG_ 1242 Sample_1 "the next sample";
CM_ SG_ 1274 Position "0 fully open, 255 fully closed";
CM_ SG_ 1274 Speed "0 slowest, 255 fastest";
CM_ SG_ 1274 Current "current limit of the move in mA; from firmware 109 the move uses its magnitude, at most the driver's 2800 mA; see the gripper manual for the safe range";
CM_ SG_ 1274 Activate "1 activate the gripper, 0 deactivate";
CM_ SG_ 1274 Action "1 go to the position, 0 idle";
CM_ SG_ 1274 E_stop "1 raises the gripper E-stop error, again on every control cycle until a frame with this bit 0 arrives; then Send_Clear_Error";
CM_ SG_ 1274 Release_direction "read by the firmware but not used";
CM_ SG_ 1272 gripper_position "0 fully open, 255 fully closed";
CM_ SG_ 1272 gripper_current "measured current in mA";
CM_ SG_ 1272 gripper_activated "1 activated";
CM_ SG_ 1272 gripper_action_status "the action bit of the last Send_gripper_data_pack (1 after #Grippos); the driver never clears it, so it stays 1 after the move ends: the object detection tells when the move has ended";
CM_ SG_ 1272 gripper_object_detection_raw "bit 5 is the low bit, bit 4 the high bit: 0 moving, 1 object detected while closing, 2 object detected while opening, 3 at the position; raw bit pair, see value labels (wire order differs from numeric status)";
CM_ SG_ 1272 gripper_temperature_error "a copy of the thermistor temperature error";
CM_ SG_ 1272 gripper_timeout_error "a copy of the CAN watchdog error (Send_Watchdog), not a move timeout";
CM_ SG_ 1272 gripper_estop_error "the E-stop bit of Send_gripper_data_pack (or #Gripstop 1) was set";
CM_ SG_ 1272 gripper_calibrated "1 calibrated";
CM_ SG_ 1273 gripper_position "0 fully open, 255 fully closed";
CM_ SG_ 1273 gripper_current "measured current in mA";
CM_ SG_ 1273 gripper_activated "1 activated";
CM_ SG_ 1273 gripper_action_status "the action bit of the last Send_gripper_data_pack (1 after #Grippos); the driver never clears it, so it stays 1 after the move ends: the object detection tells when the move has ended";
CM_ SG_ 1273 gripper_object_detection_raw "bit 5 is the low bit, bit 4 the high bit: 0 moving, 1 object detected while closing, 2 object detected while opening, 3 at the position; raw bit pair, see value labels (wire order differs from numeric status)";
CM_ SG_ 1273 gripper_temperature_error "a copy of the thermistor temperature error";
CM_ SG_ 1273 gripper_timeout_error "a copy of the CAN watchdog error (Send_Watchdog), not a move timeout";
CM_ SG_ 1273 gripper_estop_error "the E-stop bit of Send_gripper_data_pack (or #Gripstop 1) was set";
CM_ SG_ 1273 gripper_calibrated "1 calibrated";
CM_ SG_ 1284 Speed_setpoint "encoder ticks/s";
CM_ SG_ 1284 Current_feedforward "mA";
CM_ SG_ 1288 Position_setpoint "encoder ticks";
CM_ SG_ 1288 Speed_setpoint "encoder ticks/s";
CM_ SG_ 1288 Current_feedforward "mA";
CM_ SG_ 1342 Speed "encoder ticks/s; the sign gives the direction";
CM_ SG_ 1342 Trigger "0 = trigger when the pin is low, 1 = when it is high, 2 = on any edge";
CM_ SG_ 1286 position "encoder ticks";
CM_ SG_ 1286 speed "encoder ticks/s";
CM_ SG_ 1286 current "Iq in mA";
CM_ SG_ 1287 position "encoder ticks";
CM_ SG_ 1287 speed "encoder ticks/s";
CM_ SG_ 1287 current "Iq in mA";
CM_ SG_ 1344 position "encoder ticks";
CM_ SG_ 1344 HALL_trigger "1 while the driver waits for the trigger (with a level trigger, also again after the pin left the level), 0 while it holds";
CM_ SG_ 1344 additional_pin2 "the raw level of the ADDITIONAL2 pin";
CM_ SG_ 1344 hall_index "1 once the trigger has been seen (latched)";
CM_ SG_ 1345 position "encoder ticks";
CM_ SG_ 1345 HALL_trigger "1 while the driver waits for the trigger (with a level trigger, also again after the pin left the level), 0 while it holds";
CM_ SG_ 1345 additional_pin2 "the raw level of the ADDITIONAL2 pin";
CM_ SG_ 1345 hall_index "1 once the trigger has been seen (latched)";
CM_ SG_ 1320 Speed_limit "encoder ticks/s";
CM_ SG_ 1320 Current_limit "mA";
CM_ SG_ 1324 Kt "Nm/A";
CM_ SG_ 1348 Voltage_limit "mV; 0 = Vbus";
CM_ SG_ 1326 temperature "\u00b0C";
CM_ SG_ 1327 temperature "\u00b0C";
CM_ SG_ 1328 voltage "mV";
CM_ SG_ 1329 voltage "mV";
CM_ SG_ 1330 HARDWARE_VERSION "PCB revision";
CM_ SG_ 1330 BATCH_DATE "production batch";
CM_ SG_ 1330 SOFTWARE_VERSION "firmware release, e.g. 108";
CM_ SG_ 1330 SERIAL_NUMBER "serial number as held in RAM: 1 after a power-up";
CM_ SG_ 1331 HARDWARE_VERSION "PCB revision";
CM_ SG_ 1331 BATCH_DATE "production batch";
CM_ SG_ 1331 SOFTWARE_VERSION "firmware release, e.g. 108";
CM_ SG_ 1331 SERIAL_NUMBER "serial number as held in RAM: 1 after a power-up";
CM_ SG_ 1332 error "any error is active";
CM_ SG_ 1332 temperature_error "motor over the temperature limit";
CM_ SG_ 1332 encoder_error "the encoder reports no magnet (too weak a field)";
CM_ SG_ 1332 vbus_error "supply voltage outside the limits";
CM_ SG_ 1332 driver_error "reserved; never set by this firmware (STEPFOC does not read a fault output of its driver stage)";
CM_ SG_ 1332 velocity_error "speed above 30,000,000 ticks/s, a fixed threshold (not #Vlimit)";
CM_ SG_ 1332 current_error "reserved; never set by this firmware";
CM_ SG_ 1332 estop_error "Send_ESTOP was received";
CM_ SG_ 1332 calibrated "the motor is calibrated";
CM_ SG_ 1332 activated "the controller is activated";
CM_ SG_ 1332 watchdog_error "the watchdog ran out";
CM_ SG_ 1332 wrong_product "from firmware 109: this firmware is on the other product's board (the product lock) and drives nothing";
CM_ SG_ 1333 error "any error is active";
CM_ SG_ 1333 temperature_error "motor over the temperature limit";
CM_ SG_ 1333 encoder_error "the encoder reports no magnet (too weak a field)";
CM_ SG_ 1333 vbus_error "supply voltage outside the limits";
CM_ SG_ 1333 driver_error "reserved; never set by this firmware (STEPFOC does not read a fault output of its driver stage)";
CM_ SG_ 1333 velocity_error "speed above 30,000,000 ticks/s, a fixed threshold (not #Vlimit)";
CM_ SG_ 1333 current_error "reserved; never set by this firmware";
CM_ SG_ 1333 estop_error "Send_ESTOP was received";
CM_ SG_ 1333 calibrated "the motor is calibrated";
CM_ SG_ 1333 activated "the controller is activated";
CM_ SG_ 1333 watchdog_error "the watchdog ran out";
CM_ SG_ 1333 wrong_product "from firmware 109: this firmware is on the other product's board (the product lock) and drives nothing";
CM_ SG_ 1334 current "mA";
CM_ SG_ 1335 current "mA";
CM_ SG_ 1336 position "encoder ticks";
CM_ SG_ 1336 speed "encoder ticks/s";
CM_ SG_ 1337 position "encoder ticks";
CM_ SG_ 1337 speed "encoder ticks/s";
CM_ SG_ 1346 Kt "Nm/A";
CM_ SG_ 1347 Kt "Nm/A";
CM_ SG_ 1358 product "1 STEPFOC, 2 Spectral Micro: the firmware that answers";
CM_ SG_ 1358 tool_id "parameter 1: 0 none, 1 SSG-48, 11-33 MSG, 200-254 your own";
CM_ SG_ 1358 firmware_version "the release, e.g. 109";
CM_ SG_ 1358 hardware_version "PCB revision from the EEPROM";
CM_ SG_ 1358 pole_pairs "the motor's pole pairs; 0 if outside 0-255";
CM_ SG_ 1358 calibrated "1 calibrated, 0 not";
CM_ SG_ 1358 gripper "the driver is set up as a gripper (#Gripper 1)";
CM_ SG_ 1358 brake_on_idle "idle brakes (1) or coasts (0)";
CM_ SG_ 1358 commutation_reversed "calibration found the coils wired the other way round";
CM_ SG_ 1358 settings_block2 "the EEPROM has the bank settings block 2 lives in, so parameters 1-5 can be saved";
CM_ SG_ 1358 wrong_product "this firmware is on the other product's board (the product lock) and drives nothing";
CM_ SG_ 1358 sense_zero_measured "the current-sense zero was measured at start-up and is plausible";
CM_ SG_ 1358 cogging_saved "the anti-cogging in use is the one saved in the EEPROM";
CM_ SG_ 1358 switching_zero_in_use "the current-sense zero measured with the bridge switching is in use (parameter 46)";
CM_ SG_ 1359 product "1 STEPFOC, 2 Spectral Micro: the firmware that answers";
CM_ SG_ 1359 tool_id "parameter 1: 0 none, 1 SSG-48, 11-33 MSG, 200-254 your own";
CM_ SG_ 1359 firmware_version "the release, e.g. 109";
CM_ SG_ 1359 hardware_version "PCB revision from the EEPROM";
CM_ SG_ 1359 pole_pairs "the motor's pole pairs; 0 if outside 0-255";
CM_ SG_ 1359 calibrated "1 calibrated, 0 not";
CM_ SG_ 1359 gripper "the driver is set up as a gripper (#Gripper 1)";
CM_ SG_ 1359 brake_on_idle "idle brakes (1) or coasts (0)";
CM_ SG_ 1359 commutation_reversed "calibration found the coils wired the other way round";
CM_ SG_ 1359 settings_block2 "the EEPROM has the bank settings block 2 lives in, so parameters 1-5 can be saved";
CM_ SG_ 1359 wrong_product "this firmware is on the other product's board (the product lock) and drives nothing";
CM_ SG_ 1359 sense_zero_measured "the current-sense zero was measured at start-up and is plausible";
CM_ SG_ 1359 cogging_saved "the anti-cogging in use is the one saved in the EEPROM";
CM_ SG_ 1359 switching_zero_in_use "the current-sense zero measured with the bridge switching is in use (parameter 46)";
CM_ SG_ 1360 temperature "\u00b0C (meaningful with the thermistor enabled)";
CM_ SG_ 1360 voltage "supply voltage in mV";
CM_ SG_ 1360 errors_1 "the error flags, as byte 0 of Send_Respond_State_of_Errors";
CM_ SG_ 1360 errors_2 "calibrated, activated, watchdog, wrong product, as byte 1 of Send_Respond_State_of_Errors";
CM_ SG_ 1360 current "Iq in mA";
CM_ SG_ 1361 temperature "\u00b0C (meaningful with the thermistor enabled)";
CM_ SG_ 1361 voltage "supply voltage in mV";
CM_ SG_ 1361 errors_1 "the error flags, as byte 0 of Send_Respond_State_of_Errors";
CM_ SG_ 1361 errors_2 "calibrated, activated, watchdog, wrong product, as byte 1 of Send_Respond_State_of_Errors";
CM_ SG_ 1361 current "Iq in mA";
CM_ SG_ 1302 ID "0 to 13; 14 and 15 are accepted but reserved by the bootloader";
CM_ SG_ 1310 Time "ms; 0 = off";
CM_ SG_ 1310 Action "0 legacy (brake or coast as idle does), 1 hold the position, 2 brake, 3 coast, 4 descend at the fallback current and speed; other values act as 0";
CM_ SG_ 1340 Interval "ms; 0 = off";
CM_ SG_ 1350 Mask "bit 0 = write the idle behaviour";
CM_ SG_ 1350 Value "bit 0: 1 brake, 0 coast";
CM_ SG_ 1352 Parameter "the parameter number, 1-87";
CM_ SG_ 1352 Value "the new value, in the parameter's unit; for the gains, limits and Kt (8-16, 20) a float's bit pattern";
CM_ SG_ 1354 Parameter "the parameter number";
CM_ SG_ 1356 parameter "the parameter number";
CM_ SG_ 1356 value "the value in force; a float's bits for 8-16 and 20";
CM_ SG_ 1357 parameter "the parameter number";
CM_ SG_ 1357 value "the value in force; a float's bits for 8-16 and 20";
CM_ SG_ 1362 Kind "0 capture (up to 1024 samples: parameter 32 says how many), 1 histogram (256 bins), 2 anti-cogging harmonics (8 slots), 3 anti-cogging table (256 values), 4 encoder table (128 values)";
CM_ SG_ 1362 First "the first index";
CM_ SG_ 1362 Count "how many entries; 0 cancels a read-out";
CM_ SG_ 1364 header "kind \u00d7 8192 + index";
CM_ SG_ 1364 word_a "capture: channel A; histogram: the count (unsigned); harmonics: the harmonic number (0 = slot unused); tables: entry index";
CM_ SG_ 1364 word_b "capture: channel B; histogram: the sum's upper 16 bits; harmonics: a, the cosine term in mA; tables: entry index + 1";
CM_ SG_ 1364 word_c "capture: channel C; histogram: the sum's lower 16 bits; harmonics: b, the sine term in mA; tables: entry index + 2 (0 past the end)";
CM_ SG_ 1365 header "kind \u00d7 8192 + index";
CM_ SG_ 1365 word_a "capture: channel A; histogram: the count (unsigned); harmonics: the harmonic number (0 = slot unused); tables: entry index";
CM_ SG_ 1365 word_b "capture: channel B; histogram: the sum's upper 16 bits; harmonics: a, the cosine term in mA; tables: entry index + 1";
CM_ SG_ 1365 word_c "capture: channel C; histogram: the sum's lower 16 bits; harmonics: b, the sine term in mA; tables: entry index + 2 (0 past the end)";
CM_ SG_ 1366 Header "kind \u00d7 8192 + index; kind 2 or 3";
CM_ SG_ 1366 Word_A "kind 2: the harmonic (1-32, 0 = unused); kind 3: value at index";
CM_ SG_ 1366 Word_B "kind 2: a in mA; kind 3: value at index + 1";
CM_ SG_ 1366 Word_C "kind 2: b in mA; kind 3: value at index + 2";
CM_ SG_ 1368 Operation "0 stop everything (tones, queue, samples); 1 a tone now; 2 add an event to the queue; 3 play the queue; 4 play the samples; 5 samples off, buffer cleared; 6 clear the queue (tones that sound keep sounding)";
CM_ SG_ 1368 Channel "the tone channel, 0-3 (operations 1 and 2)";
CM_ SG_ 1368 A "1, 2: the pitch in Hz (2: 0 silences the channel); 4: the sample rate in Hz, at most the loop rate";
CM_ SG_ 1368 B "1, 2: the loudness in mA; 4: the voltage of a full-scale sample in mV";
CM_ SG_ 1368 C "1: the duration in ms, 0 = until stopped; 2: the wait in ms before the next event, 0 = the next one starts with it";
CM_ SG_ 1370 Sample_1 "the next sample";
CM_ SG_ 1402 Position "0 fully open, 255 fully closed";
CM_ SG_ 1402 Speed "0 slowest, 255 fastest";
CM_ SG_ 1402 Current "current limit of the move in mA; from firmware 109 the move uses its magnitude, at most the driver's 2800 mA; see the gripper manual for the safe range";
CM_ SG_ 1402 Activate "1 activate the gripper, 0 deactivate";
CM_ SG_ 1402 Action "1 go to the position, 0 idle";
CM_ SG_ 1402 E_stop "1 raises the gripper E-stop error, again on every control cycle until a frame with this bit 0 arrives; then Send_Clear_Error";
CM_ SG_ 1402 Release_direction "read by the firmware but not used";
CM_ SG_ 1400 gripper_position "0 fully open, 255 fully closed";
CM_ SG_ 1400 gripper_current "measured current in mA";
CM_ SG_ 1400 gripper_activated "1 activated";
CM_ SG_ 1400 gripper_action_status "the action bit of the last Send_gripper_data_pack (1 after #Grippos); the driver never clears it, so it stays 1 after the move ends: the object detection tells when the move has ended";
CM_ SG_ 1400 gripper_object_detection_raw "bit 5 is the low bit, bit 4 the high bit: 0 moving, 1 object detected while closing, 2 object detected while opening, 3 at the position; raw bit pair, see value labels (wire order differs from numeric status)";
CM_ SG_ 1400 gripper_temperature_error "a copy of the thermistor temperature error";
CM_ SG_ 1400 gripper_timeout_error "a copy of the CAN watchdog error (Send_Watchdog), not a move timeout";
CM_ SG_ 1400 gripper_estop_error "the E-stop bit of Send_gripper_data_pack (or #Gripstop 1) was set";
CM_ SG_ 1400 gripper_calibrated "1 calibrated";
CM_ SG_ 1401 gripper_position "0 fully open, 255 fully closed";
CM_ SG_ 1401 gripper_current "measured current in mA";
CM_ SG_ 1401 gripper_activated "1 activated";
CM_ SG_ 1401 gripper_action_status "the action bit of the last Send_gripper_data_pack (1 after #Grippos); the driver never clears it, so it stays 1 after the move ends: the object detection tells when the move has ended";
CM_ SG_ 1401 gripper_object_detection_raw "bit 5 is the low bit, bit 4 the high bit: 0 moving, 1 object detected while closing, 2 object detected while opening, 3 at the position; raw bit pair, see value labels (wire order differs from numeric status)";
CM_ SG_ 1401 gripper_temperature_error "a copy of the thermistor temperature error";
CM_ SG_ 1401 gripper_timeout_error "a copy of the CAN watchdog error (Send_Watchdog), not a move timeout";
CM_ SG_ 1401 gripper_estop_error "the E-stop bit of Send_gripper_data_pack (or #Gripstop 1) was set";
CM_ SG_ 1401 gripper_calibrated "1 calibrated";
CM_ SG_ 1412 Speed_setpoint "encoder ticks/s";
CM_ SG_ 1412 Current_feedforward "mA";
CM_ SG_ 1416 Position_setpoint "encoder ticks";
CM_ SG_ 1416 Speed_setpoint "encoder ticks/s";
CM_ SG_ 1416 Current_feedforward "mA";
CM_ SG_ 1470 Speed "encoder ticks/s; the sign gives the direction";
CM_ SG_ 1470 Trigger "0 = trigger when the pin is low, 1 = when it is high, 2 = on any edge";
CM_ SG_ 1414 position "encoder ticks";
CM_ SG_ 1414 speed "encoder ticks/s";
CM_ SG_ 1414 current "Iq in mA";
CM_ SG_ 1415 position "encoder ticks";
CM_ SG_ 1415 speed "encoder ticks/s";
CM_ SG_ 1415 current "Iq in mA";
CM_ SG_ 1472 position "encoder ticks";
CM_ SG_ 1472 HALL_trigger "1 while the driver waits for the trigger (with a level trigger, also again after the pin left the level), 0 while it holds";
CM_ SG_ 1472 additional_pin2 "the raw level of the ADDITIONAL2 pin";
CM_ SG_ 1472 hall_index "1 once the trigger has been seen (latched)";
CM_ SG_ 1473 position "encoder ticks";
CM_ SG_ 1473 HALL_trigger "1 while the driver waits for the trigger (with a level trigger, also again after the pin left the level), 0 while it holds";
CM_ SG_ 1473 additional_pin2 "the raw level of the ADDITIONAL2 pin";
CM_ SG_ 1473 hall_index "1 once the trigger has been seen (latched)";
CM_ SG_ 1448 Speed_limit "encoder ticks/s";
CM_ SG_ 1448 Current_limit "mA";
CM_ SG_ 1452 Kt "Nm/A";
CM_ SG_ 1476 Voltage_limit "mV; 0 = Vbus";
CM_ SG_ 1454 temperature "\u00b0C";
CM_ SG_ 1455 temperature "\u00b0C";
CM_ SG_ 1456 voltage "mV";
CM_ SG_ 1457 voltage "mV";
CM_ SG_ 1458 HARDWARE_VERSION "PCB revision";
CM_ SG_ 1458 BATCH_DATE "production batch";
CM_ SG_ 1458 SOFTWARE_VERSION "firmware release, e.g. 108";
CM_ SG_ 1458 SERIAL_NUMBER "serial number as held in RAM: 1 after a power-up";
CM_ SG_ 1459 HARDWARE_VERSION "PCB revision";
CM_ SG_ 1459 BATCH_DATE "production batch";
CM_ SG_ 1459 SOFTWARE_VERSION "firmware release, e.g. 108";
CM_ SG_ 1459 SERIAL_NUMBER "serial number as held in RAM: 1 after a power-up";
CM_ SG_ 1460 error "any error is active";
CM_ SG_ 1460 temperature_error "motor over the temperature limit";
CM_ SG_ 1460 encoder_error "the encoder reports no magnet (too weak a field)";
CM_ SG_ 1460 vbus_error "supply voltage outside the limits";
CM_ SG_ 1460 driver_error "reserved; never set by this firmware (STEPFOC does not read a fault output of its driver stage)";
CM_ SG_ 1460 velocity_error "speed above 30,000,000 ticks/s, a fixed threshold (not #Vlimit)";
CM_ SG_ 1460 current_error "reserved; never set by this firmware";
CM_ SG_ 1460 estop_error "Send_ESTOP was received";
CM_ SG_ 1460 calibrated "the motor is calibrated";
CM_ SG_ 1460 activated "the controller is activated";
CM_ SG_ 1460 watchdog_error "the watchdog ran out";
CM_ SG_ 1460 wrong_product "from firmware 109: this firmware is on the other product's board (the product lock) and drives nothing";
CM_ SG_ 1461 error "any error is active";
CM_ SG_ 1461 temperature_error "motor over the temperature limit";
CM_ SG_ 1461 encoder_error "the encoder reports no magnet (too weak a field)";
CM_ SG_ 1461 vbus_error "supply voltage outside the limits";
CM_ SG_ 1461 driver_error "reserved; never set by this firmware (STEPFOC does not read a fault output of its driver stage)";
CM_ SG_ 1461 velocity_error "speed above 30,000,000 ticks/s, a fixed threshold (not #Vlimit)";
CM_ SG_ 1461 current_error "reserved; never set by this firmware";
CM_ SG_ 1461 estop_error "Send_ESTOP was received";
CM_ SG_ 1461 calibrated "the motor is calibrated";
CM_ SG_ 1461 activated "the controller is activated";
CM_ SG_ 1461 watchdog_error "the watchdog ran out";
CM_ SG_ 1461 wrong_product "from firmware 109: this firmware is on the other product's board (the product lock) and drives nothing";
CM_ SG_ 1462 current "mA";
CM_ SG_ 1463 current "mA";
CM_ SG_ 1464 position "encoder ticks";
CM_ SG_ 1464 speed "encoder ticks/s";
CM_ SG_ 1465 position "encoder ticks";
CM_ SG_ 1465 speed "encoder ticks/s";
CM_ SG_ 1474 Kt "Nm/A";
CM_ SG_ 1475 Kt "Nm/A";
CM_ SG_ 1486 product "1 STEPFOC, 2 Spectral Micro: the firmware that answers";
CM_ SG_ 1486 tool_id "parameter 1: 0 none, 1 SSG-48, 11-33 MSG, 200-254 your own";
CM_ SG_ 1486 firmware_version "the release, e.g. 109";
CM_ SG_ 1486 hardware_version "PCB revision from the EEPROM";
CM_ SG_ 1486 pole_pairs "the motor's pole pairs; 0 if outside 0-255";
CM_ SG_ 1486 calibrated "1 calibrated, 0 not";
CM_ SG_ 1486 gripper "the driver is set up as a gripper (#Gripper 1)";
CM_ SG_ 1486 brake_on_idle "idle brakes (1) or coasts (0)";
CM_ SG_ 1486 commutation_reversed "calibration found the coils wired the other way round";
CM_ SG_ 1486 settings_block2 "the EEPROM has the bank settings block 2 lives in, so parameters 1-5 can be saved";
CM_ SG_ 1486 wrong_product "this firmware is on the other product's board (the product lock) and drives nothing";
CM_ SG_ 1486 sense_zero_measured "the current-sense zero was measured at start-up and is plausible";
CM_ SG_ 1486 cogging_saved "the anti-cogging in use is the one saved in the EEPROM";
CM_ SG_ 1486 switching_zero_in_use "the current-sense zero measured with the bridge switching is in use (parameter 46)";
CM_ SG_ 1487 product "1 STEPFOC, 2 Spectral Micro: the firmware that answers";
CM_ SG_ 1487 tool_id "parameter 1: 0 none, 1 SSG-48, 11-33 MSG, 200-254 your own";
CM_ SG_ 1487 firmware_version "the release, e.g. 109";
CM_ SG_ 1487 hardware_version "PCB revision from the EEPROM";
CM_ SG_ 1487 pole_pairs "the motor's pole pairs; 0 if outside 0-255";
CM_ SG_ 1487 calibrated "1 calibrated, 0 not";
CM_ SG_ 1487 gripper "the driver is set up as a gripper (#Gripper 1)";
CM_ SG_ 1487 brake_on_idle "idle brakes (1) or coasts (0)";
CM_ SG_ 1487 commutation_reversed "calibration found the coils wired the other way round";
CM_ SG_ 1487 settings_block2 "the EEPROM has the bank settings block 2 lives in, so parameters 1-5 can be saved";
CM_ SG_ 1487 wrong_product "this firmware is on the other product's board (the product lock) and drives nothing";
CM_ SG_ 1487 sense_zero_measured "the current-sense zero was measured at start-up and is plausible";
CM_ SG_ 1487 cogging_saved "the anti-cogging in use is the one saved in the EEPROM";
CM_ SG_ 1487 switching_zero_in_use "the current-sense zero measured with the bridge switching is in use (parameter 46)";
CM_ SG_ 1488 temperature "\u00b0C (meaningful with the thermistor enabled)";
CM_ SG_ 1488 voltage "supply voltage in mV";
CM_ SG_ 1488 errors_1 "the error flags, as byte 0 of Send_Respond_State_of_Errors";
CM_ SG_ 1488 errors_2 "calibrated, activated, watchdog, wrong product, as byte 1 of Send_Respond_State_of_Errors";
CM_ SG_ 1488 current "Iq in mA";
CM_ SG_ 1489 temperature "\u00b0C (meaningful with the thermistor enabled)";
CM_ SG_ 1489 voltage "supply voltage in mV";
CM_ SG_ 1489 errors_1 "the error flags, as byte 0 of Send_Respond_State_of_Errors";
CM_ SG_ 1489 errors_2 "calibrated, activated, watchdog, wrong product, as byte 1 of Send_Respond_State_of_Errors";
CM_ SG_ 1489 current "Iq in mA";
CM_ SG_ 1430 ID "0 to 13; 14 and 15 are accepted but reserved by the bootloader";
CM_ SG_ 1438 Time "ms; 0 = off";
CM_ SG_ 1438 Action "0 legacy (brake or coast as idle does), 1 hold the position, 2 brake, 3 coast, 4 descend at the fallback current and speed; other values act as 0";
CM_ SG_ 1468 Interval "ms; 0 = off";
CM_ SG_ 1478 Mask "bit 0 = write the idle behaviour";
CM_ SG_ 1478 Value "bit 0: 1 brake, 0 coast";
CM_ SG_ 1480 Parameter "the parameter number, 1-87";
CM_ SG_ 1480 Value "the new value, in the parameter's unit; for the gains, limits and Kt (8-16, 20) a float's bit pattern";
CM_ SG_ 1482 Parameter "the parameter number";
CM_ SG_ 1484 parameter "the parameter number";
CM_ SG_ 1484 value "the value in force; a float's bits for 8-16 and 20";
CM_ SG_ 1485 parameter "the parameter number";
CM_ SG_ 1485 value "the value in force; a float's bits for 8-16 and 20";
CM_ SG_ 1490 Kind "0 capture (up to 1024 samples: parameter 32 says how many), 1 histogram (256 bins), 2 anti-cogging harmonics (8 slots), 3 anti-cogging table (256 values), 4 encoder table (128 values)";
CM_ SG_ 1490 First "the first index";
CM_ SG_ 1490 Count "how many entries; 0 cancels a read-out";
CM_ SG_ 1492 header "kind \u00d7 8192 + index";
CM_ SG_ 1492 word_a "capture: channel A; histogram: the count (unsigned); harmonics: the harmonic number (0 = slot unused); tables: entry index";
CM_ SG_ 1492 word_b "capture: channel B; histogram: the sum's upper 16 bits; harmonics: a, the cosine term in mA; tables: entry index + 1";
CM_ SG_ 1492 word_c "capture: channel C; histogram: the sum's lower 16 bits; harmonics: b, the sine term in mA; tables: entry index + 2 (0 past the end)";
CM_ SG_ 1493 header "kind \u00d7 8192 + index";
CM_ SG_ 1493 word_a "capture: channel A; histogram: the count (unsigned); harmonics: the harmonic number (0 = slot unused); tables: entry index";
CM_ SG_ 1493 word_b "capture: channel B; histogram: the sum's upper 16 bits; harmonics: a, the cosine term in mA; tables: entry index + 1";
CM_ SG_ 1493 word_c "capture: channel C; histogram: the sum's lower 16 bits; harmonics: b, the sine term in mA; tables: entry index + 2 (0 past the end)";
CM_ SG_ 1494 Header "kind \u00d7 8192 + index; kind 2 or 3";
CM_ SG_ 1494 Word_A "kind 2: the harmonic (1-32, 0 = unused); kind 3: value at index";
CM_ SG_ 1494 Word_B "kind 2: a in mA; kind 3: value at index + 1";
CM_ SG_ 1494 Word_C "kind 2: b in mA; kind 3: value at index + 2";
CM_ SG_ 1496 Operation "0 stop everything (tones, queue, samples); 1 a tone now; 2 add an event to the queue; 3 play the queue; 4 play the samples; 5 samples off, buffer cleared; 6 clear the queue (tones that sound keep sounding)";
CM_ SG_ 1496 Channel "the tone channel, 0-3 (operations 1 and 2)";
CM_ SG_ 1496 A "1, 2: the pitch in Hz (2: 0 silences the channel); 4: the sample rate in Hz, at most the loop rate";
CM_ SG_ 1496 B "1, 2: the loudness in mA; 4: the voltage of a full-scale sample in mV";
CM_ SG_ 1496 C "1: the duration in ms, 0 = until stopped; 2: the wait in ms before the next event, 0 = the next one starts with it";
CM_ SG_ 1498 Sample_1 "the next sample";
CM_ SG_ 1530 Position "0 fully open, 255 fully closed";
CM_ SG_ 1530 Speed "0 slowest, 255 fastest";
CM_ SG_ 1530 Current "current limit of the move in mA; from firmware 109 the move uses its magnitude, at most the driver's 2800 mA; see the gripper manual for the safe range";
CM_ SG_ 1530 Activate "1 activate the gripper, 0 deactivate";
CM_ SG_ 1530 Action "1 go to the position, 0 idle";
CM_ SG_ 1530 E_stop "1 raises the gripper E-stop error, again on every control cycle until a frame with this bit 0 arrives; then Send_Clear_Error";
CM_ SG_ 1530 Release_direction "read by the firmware but not used";
CM_ SG_ 1528 gripper_position "0 fully open, 255 fully closed";
CM_ SG_ 1528 gripper_current "measured current in mA";
CM_ SG_ 1528 gripper_activated "1 activated";
CM_ SG_ 1528 gripper_action_status "the action bit of the last Send_gripper_data_pack (1 after #Grippos); the driver never clears it, so it stays 1 after the move ends: the object detection tells when the move has ended";
CM_ SG_ 1528 gripper_object_detection_raw "bit 5 is the low bit, bit 4 the high bit: 0 moving, 1 object detected while closing, 2 object detected while opening, 3 at the position; raw bit pair, see value labels (wire order differs from numeric status)";
CM_ SG_ 1528 gripper_temperature_error "a copy of the thermistor temperature error";
CM_ SG_ 1528 gripper_timeout_error "a copy of the CAN watchdog error (Send_Watchdog), not a move timeout";
CM_ SG_ 1528 gripper_estop_error "the E-stop bit of Send_gripper_data_pack (or #Gripstop 1) was set";
CM_ SG_ 1528 gripper_calibrated "1 calibrated";
CM_ SG_ 1529 gripper_position "0 fully open, 255 fully closed";
CM_ SG_ 1529 gripper_current "measured current in mA";
CM_ SG_ 1529 gripper_activated "1 activated";
CM_ SG_ 1529 gripper_action_status "the action bit of the last Send_gripper_data_pack (1 after #Grippos); the driver never clears it, so it stays 1 after the move ends: the object detection tells when the move has ended";
CM_ SG_ 1529 gripper_object_detection_raw "bit 5 is the low bit, bit 4 the high bit: 0 moving, 1 object detected while closing, 2 object detected while opening, 3 at the position; raw bit pair, see value labels (wire order differs from numeric status)";
CM_ SG_ 1529 gripper_temperature_error "a copy of the thermistor temperature error";
CM_ SG_ 1529 gripper_timeout_error "a copy of the CAN watchdog error (Send_Watchdog), not a move timeout";
CM_ SG_ 1529 gripper_estop_error "the E-stop bit of Send_gripper_data_pack (or #Gripstop 1) was set";
CM_ SG_ 1529 gripper_calibrated "1 calibrated";
CM_ SG_ 1540 Speed_setpoint "encoder ticks/s";
CM_ SG_ 1540 Current_feedforward "mA";
CM_ SG_ 1544 Position_setpoint "encoder ticks";
CM_ SG_ 1544 Speed_setpoint "encoder ticks/s";
CM_ SG_ 1544 Current_feedforward "mA";
CM_ SG_ 1598 Speed "encoder ticks/s; the sign gives the direction";
CM_ SG_ 1598 Trigger "0 = trigger when the pin is low, 1 = when it is high, 2 = on any edge";
CM_ SG_ 1542 position "encoder ticks";
CM_ SG_ 1542 speed "encoder ticks/s";
CM_ SG_ 1542 current "Iq in mA";
CM_ SG_ 1543 position "encoder ticks";
CM_ SG_ 1543 speed "encoder ticks/s";
CM_ SG_ 1543 current "Iq in mA";
CM_ SG_ 1600 position "encoder ticks";
CM_ SG_ 1600 HALL_trigger "1 while the driver waits for the trigger (with a level trigger, also again after the pin left the level), 0 while it holds";
CM_ SG_ 1600 additional_pin2 "the raw level of the ADDITIONAL2 pin";
CM_ SG_ 1600 hall_index "1 once the trigger has been seen (latched)";
CM_ SG_ 1601 position "encoder ticks";
CM_ SG_ 1601 HALL_trigger "1 while the driver waits for the trigger (with a level trigger, also again after the pin left the level), 0 while it holds";
CM_ SG_ 1601 additional_pin2 "the raw level of the ADDITIONAL2 pin";
CM_ SG_ 1601 hall_index "1 once the trigger has been seen (latched)";
CM_ SG_ 1576 Speed_limit "encoder ticks/s";
CM_ SG_ 1576 Current_limit "mA";
CM_ SG_ 1580 Kt "Nm/A";
CM_ SG_ 1604 Voltage_limit "mV; 0 = Vbus";
CM_ SG_ 1582 temperature "\u00b0C";
CM_ SG_ 1583 temperature "\u00b0C";
CM_ SG_ 1584 voltage "mV";
CM_ SG_ 1585 voltage "mV";
CM_ SG_ 1586 HARDWARE_VERSION "PCB revision";
CM_ SG_ 1586 BATCH_DATE "production batch";
CM_ SG_ 1586 SOFTWARE_VERSION "firmware release, e.g. 108";
CM_ SG_ 1586 SERIAL_NUMBER "serial number as held in RAM: 1 after a power-up";
CM_ SG_ 1587 HARDWARE_VERSION "PCB revision";
CM_ SG_ 1587 BATCH_DATE "production batch";
CM_ SG_ 1587 SOFTWARE_VERSION "firmware release, e.g. 108";
CM_ SG_ 1587 SERIAL_NUMBER "serial number as held in RAM: 1 after a power-up";
CM_ SG_ 1588 error "any error is active";
CM_ SG_ 1588 temperature_error "motor over the temperature limit";
CM_ SG_ 1588 encoder_error "the encoder reports no magnet (too weak a field)";
CM_ SG_ 1588 vbus_error "supply voltage outside the limits";
CM_ SG_ 1588 driver_error "reserved; never set by this firmware (STEPFOC does not read a fault output of its driver stage)";
CM_ SG_ 1588 velocity_error "speed above 30,000,000 ticks/s, a fixed threshold (not #Vlimit)";
CM_ SG_ 1588 current_error "reserved; never set by this firmware";
CM_ SG_ 1588 estop_error "Send_ESTOP was received";
CM_ SG_ 1588 calibrated "the motor is calibrated";
CM_ SG_ 1588 activated "the controller is activated";
CM_ SG_ 1588 watchdog_error "the watchdog ran out";
CM_ SG_ 1588 wrong_product "from firmware 109: this firmware is on the other product's board (the product lock) and drives nothing";
CM_ SG_ 1589 error "any error is active";
CM_ SG_ 1589 temperature_error "motor over the temperature limit";
CM_ SG_ 1589 encoder_error "the encoder reports no magnet (too weak a field)";
CM_ SG_ 1589 vbus_error "supply voltage outside the limits";
CM_ SG_ 1589 driver_error "reserved; never set by this firmware (STEPFOC does not read a fault output of its driver stage)";
CM_ SG_ 1589 velocity_error "speed above 30,000,000 ticks/s, a fixed threshold (not #Vlimit)";
CM_ SG_ 1589 current_error "reserved; never set by this firmware";
CM_ SG_ 1589 estop_error "Send_ESTOP was received";
CM_ SG_ 1589 calibrated "the motor is calibrated";
CM_ SG_ 1589 activated "the controller is activated";
CM_ SG_ 1589 watchdog_error "the watchdog ran out";
CM_ SG_ 1589 wrong_product "from firmware 109: this firmware is on the other product's board (the product lock) and drives nothing";
CM_ SG_ 1590 current "mA";
CM_ SG_ 1591 current "mA";
CM_ SG_ 1592 position "encoder ticks";
CM_ SG_ 1592 speed "encoder ticks/s";
CM_ SG_ 1593 position "encoder ticks";
CM_ SG_ 1593 speed "encoder ticks/s";
CM_ SG_ 1602 Kt "Nm/A";
CM_ SG_ 1603 Kt "Nm/A";
CM_ SG_ 1614 product "1 STEPFOC, 2 Spectral Micro: the firmware that answers";
CM_ SG_ 1614 tool_id "parameter 1: 0 none, 1 SSG-48, 11-33 MSG, 200-254 your own";
CM_ SG_ 1614 firmware_version "the release, e.g. 109";
CM_ SG_ 1614 hardware_version "PCB revision from the EEPROM";
CM_ SG_ 1614 pole_pairs "the motor's pole pairs; 0 if outside 0-255";
CM_ SG_ 1614 calibrated "1 calibrated, 0 not";
CM_ SG_ 1614 gripper "the driver is set up as a gripper (#Gripper 1)";
CM_ SG_ 1614 brake_on_idle "idle brakes (1) or coasts (0)";
CM_ SG_ 1614 commutation_reversed "calibration found the coils wired the other way round";
CM_ SG_ 1614 settings_block2 "the EEPROM has the bank settings block 2 lives in, so parameters 1-5 can be saved";
CM_ SG_ 1614 wrong_product "this firmware is on the other product's board (the product lock) and drives nothing";
CM_ SG_ 1614 sense_zero_measured "the current-sense zero was measured at start-up and is plausible";
CM_ SG_ 1614 cogging_saved "the anti-cogging in use is the one saved in the EEPROM";
CM_ SG_ 1614 switching_zero_in_use "the current-sense zero measured with the bridge switching is in use (parameter 46)";
CM_ SG_ 1615 product "1 STEPFOC, 2 Spectral Micro: the firmware that answers";
CM_ SG_ 1615 tool_id "parameter 1: 0 none, 1 SSG-48, 11-33 MSG, 200-254 your own";
CM_ SG_ 1615 firmware_version "the release, e.g. 109";
CM_ SG_ 1615 hardware_version "PCB revision from the EEPROM";
CM_ SG_ 1615 pole_pairs "the motor's pole pairs; 0 if outside 0-255";
CM_ SG_ 1615 calibrated "1 calibrated, 0 not";
CM_ SG_ 1615 gripper "the driver is set up as a gripper (#Gripper 1)";
CM_ SG_ 1615 brake_on_idle "idle brakes (1) or coasts (0)";
CM_ SG_ 1615 commutation_reversed "calibration found the coils wired the other way round";
CM_ SG_ 1615 settings_block2 "the EEPROM has the bank settings block 2 lives in, so parameters 1-5 can be saved";
CM_ SG_ 1615 wrong_product "this firmware is on the other product's board (the product lock) and drives nothing";
CM_ SG_ 1615 sense_zero_measured "the current-sense zero was measured at start-up and is plausible";
CM_ SG_ 1615 cogging_saved "the anti-cogging in use is the one saved in the EEPROM";
CM_ SG_ 1615 switching_zero_in_use "the current-sense zero measured with the bridge switching is in use (parameter 46)";
CM_ SG_ 1616 temperature "\u00b0C (meaningful with the thermistor enabled)";
CM_ SG_ 1616 voltage "supply voltage in mV";
CM_ SG_ 1616 errors_1 "the error flags, as byte 0 of Send_Respond_State_of_Errors";
CM_ SG_ 1616 errors_2 "calibrated, activated, watchdog, wrong product, as byte 1 of Send_Respond_State_of_Errors";
CM_ SG_ 1616 current "Iq in mA";
CM_ SG_ 1617 temperature "\u00b0C (meaningful with the thermistor enabled)";
CM_ SG_ 1617 voltage "supply voltage in mV";
CM_ SG_ 1617 errors_1 "the error flags, as byte 0 of Send_Respond_State_of_Errors";
CM_ SG_ 1617 errors_2 "calibrated, activated, watchdog, wrong product, as byte 1 of Send_Respond_State_of_Errors";
CM_ SG_ 1617 current "Iq in mA";
CM_ SG_ 1558 ID "0 to 13; 14 and 15 are accepted but reserved by the bootloader";
CM_ SG_ 1566 Time "ms; 0 = off";
CM_ SG_ 1566 Action "0 legacy (brake or coast as idle does), 1 hold the position, 2 brake, 3 coast, 4 descend at the fallback current and speed; other values act as 0";
CM_ SG_ 1596 Interval "ms; 0 = off";
CM_ SG_ 1606 Mask "bit 0 = write the idle behaviour";
CM_ SG_ 1606 Value "bit 0: 1 brake, 0 coast";
CM_ SG_ 1608 Parameter "the parameter number, 1-87";
CM_ SG_ 1608 Value "the new value, in the parameter's unit; for the gains, limits and Kt (8-16, 20) a float's bit pattern";
CM_ SG_ 1610 Parameter "the parameter number";
CM_ SG_ 1612 parameter "the parameter number";
CM_ SG_ 1612 value "the value in force; a float's bits for 8-16 and 20";
CM_ SG_ 1613 parameter "the parameter number";
CM_ SG_ 1613 value "the value in force; a float's bits for 8-16 and 20";
CM_ SG_ 1618 Kind "0 capture (up to 1024 samples: parameter 32 says how many), 1 histogram (256 bins), 2 anti-cogging harmonics (8 slots), 3 anti-cogging table (256 values), 4 encoder table (128 values)";
CM_ SG_ 1618 First "the first index";
CM_ SG_ 1618 Count "how many entries; 0 cancels a read-out";
CM_ SG_ 1620 header "kind \u00d7 8192 + index";
CM_ SG_ 1620 word_a "capture: channel A; histogram: the count (unsigned); harmonics: the harmonic number (0 = slot unused); tables: entry index";
CM_ SG_ 1620 word_b "capture: channel B; histogram: the sum's upper 16 bits; harmonics: a, the cosine term in mA; tables: entry index + 1";
CM_ SG_ 1620 word_c "capture: channel C; histogram: the sum's lower 16 bits; harmonics: b, the sine term in mA; tables: entry index + 2 (0 past the end)";
CM_ SG_ 1621 header "kind \u00d7 8192 + index";
CM_ SG_ 1621 word_a "capture: channel A; histogram: the count (unsigned); harmonics: the harmonic number (0 = slot unused); tables: entry index";
CM_ SG_ 1621 word_b "capture: channel B; histogram: the sum's upper 16 bits; harmonics: a, the cosine term in mA; tables: entry index + 1";
CM_ SG_ 1621 word_c "capture: channel C; histogram: the sum's lower 16 bits; harmonics: b, the sine term in mA; tables: entry index + 2 (0 past the end)";
CM_ SG_ 1622 Header "kind \u00d7 8192 + index; kind 2 or 3";
CM_ SG_ 1622 Word_A "kind 2: the harmonic (1-32, 0 = unused); kind 3: value at index";
CM_ SG_ 1622 Word_B "kind 2: a in mA; kind 3: value at index + 1";
CM_ SG_ 1622 Word_C "kind 2: b in mA; kind 3: value at index + 2";
CM_ SG_ 1624 Operation "0 stop everything (tones, queue, samples); 1 a tone now; 2 add an event to the queue; 3 play the queue; 4 play the samples; 5 samples off, buffer cleared; 6 clear the queue (tones that sound keep sounding)";
CM_ SG_ 1624 Channel "the tone channel, 0-3 (operations 1 and 2)";
CM_ SG_ 1624 A "1, 2: the pitch in Hz (2: 0 silences the channel); 4: the sample rate in Hz, at most the loop rate";
CM_ SG_ 1624 B "1, 2: the loudness in mA; 4: the voltage of a full-scale sample in mV";
CM_ SG_ 1624 C "1: the duration in ms, 0 = until stopped; 2: the wait in ms before the next event, 0 = the next one starts with it";
CM_ SG_ 1626 Sample_1 "the next sample";
CM_ SG_ 1658 Position "0 fully open, 255 fully closed";
CM_ SG_ 1658 Speed "0 slowest, 255 fastest";
CM_ SG_ 1658 Current "current limit of the move in mA; from firmware 109 the move uses its magnitude, at most the driver's 2800 mA; see the gripper manual for the safe range";
CM_ SG_ 1658 Activate "1 activate the gripper, 0 deactivate";
CM_ SG_ 1658 Action "1 go to the position, 0 idle";
CM_ SG_ 1658 E_stop "1 raises the gripper E-stop error, again on every control cycle until a frame with this bit 0 arrives; then Send_Clear_Error";
CM_ SG_ 1658 Release_direction "read by the firmware but not used";
CM_ SG_ 1656 gripper_position "0 fully open, 255 fully closed";
CM_ SG_ 1656 gripper_current "measured current in mA";
CM_ SG_ 1656 gripper_activated "1 activated";
CM_ SG_ 1656 gripper_action_status "the action bit of the last Send_gripper_data_pack (1 after #Grippos); the driver never clears it, so it stays 1 after the move ends: the object detection tells when the move has ended";
CM_ SG_ 1656 gripper_object_detection_raw "bit 5 is the low bit, bit 4 the high bit: 0 moving, 1 object detected while closing, 2 object detected while opening, 3 at the position; raw bit pair, see value labels (wire order differs from numeric status)";
CM_ SG_ 1656 gripper_temperature_error "a copy of the thermistor temperature error";
CM_ SG_ 1656 gripper_timeout_error "a copy of the CAN watchdog error (Send_Watchdog), not a move timeout";
CM_ SG_ 1656 gripper_estop_error "the E-stop bit of Send_gripper_data_pack (or #Gripstop 1) was set";
CM_ SG_ 1656 gripper_calibrated "1 calibrated";
CM_ SG_ 1657 gripper_position "0 fully open, 255 fully closed";
CM_ SG_ 1657 gripper_current "measured current in mA";
CM_ SG_ 1657 gripper_activated "1 activated";
CM_ SG_ 1657 gripper_action_status "the action bit of the last Send_gripper_data_pack (1 after #Grippos); the driver never clears it, so it stays 1 after the move ends: the object detection tells when the move has ended";
CM_ SG_ 1657 gripper_object_detection_raw "bit 5 is the low bit, bit 4 the high bit: 0 moving, 1 object detected while closing, 2 object detected while opening, 3 at the position; raw bit pair, see value labels (wire order differs from numeric status)";
CM_ SG_ 1657 gripper_temperature_error "a copy of the thermistor temperature error";
CM_ SG_ 1657 gripper_timeout_error "a copy of the CAN watchdog error (Send_Watchdog), not a move timeout";
CM_ SG_ 1657 gripper_estop_error "the E-stop bit of Send_gripper_data_pack (or #Gripstop 1) was set";
CM_ SG_ 1657 gripper_calibrated "1 calibrated";
CM_ SG_ 1668 Speed_setpoint "encoder ticks/s";
CM_ SG_ 1668 Current_feedforward "mA";
CM_ SG_ 1672 Position_setpoint "encoder ticks";
CM_ SG_ 1672 Speed_setpoint "encoder ticks/s";
CM_ SG_ 1672 Current_feedforward "mA";
CM_ SG_ 1726 Speed "encoder ticks/s; the sign gives the direction";
CM_ SG_ 1726 Trigger "0 = trigger when the pin is low, 1 = when it is high, 2 = on any edge";
CM_ SG_ 1670 position "encoder ticks";
CM_ SG_ 1670 speed "encoder ticks/s";
CM_ SG_ 1670 current "Iq in mA";
CM_ SG_ 1671 position "encoder ticks";
CM_ SG_ 1671 speed "encoder ticks/s";
CM_ SG_ 1671 current "Iq in mA";
CM_ SG_ 1728 position "encoder ticks";
CM_ SG_ 1728 HALL_trigger "1 while the driver waits for the trigger (with a level trigger, also again after the pin left the level), 0 while it holds";
CM_ SG_ 1728 additional_pin2 "the raw level of the ADDITIONAL2 pin";
CM_ SG_ 1728 hall_index "1 once the trigger has been seen (latched)";
CM_ SG_ 1729 position "encoder ticks";
CM_ SG_ 1729 HALL_trigger "1 while the driver waits for the trigger (with a level trigger, also again after the pin left the level), 0 while it holds";
CM_ SG_ 1729 additional_pin2 "the raw level of the ADDITIONAL2 pin";
CM_ SG_ 1729 hall_index "1 once the trigger has been seen (latched)";
CM_ SG_ 1704 Speed_limit "encoder ticks/s";
CM_ SG_ 1704 Current_limit "mA";
CM_ SG_ 1708 Kt "Nm/A";
CM_ SG_ 1732 Voltage_limit "mV; 0 = Vbus";
CM_ SG_ 1710 temperature "\u00b0C";
CM_ SG_ 1711 temperature "\u00b0C";
CM_ SG_ 1712 voltage "mV";
CM_ SG_ 1713 voltage "mV";
CM_ SG_ 1714 HARDWARE_VERSION "PCB revision";
CM_ SG_ 1714 BATCH_DATE "production batch";
CM_ SG_ 1714 SOFTWARE_VERSION "firmware release, e.g. 108";
CM_ SG_ 1714 SERIAL_NUMBER "serial number as held in RAM: 1 after a power-up";
CM_ SG_ 1715 HARDWARE_VERSION "PCB revision";
CM_ SG_ 1715 BATCH_DATE "production batch";
CM_ SG_ 1715 SOFTWARE_VERSION "firmware release, e.g. 108";
CM_ SG_ 1715 SERIAL_NUMBER "serial number as held in RAM: 1 after a power-up";
CM_ SG_ 1716 error "any error is active";
CM_ SG_ 1716 temperature_error "motor over the temperature limit";
CM_ SG_ 1716 encoder_error "the encoder reports no magnet (too weak a field)";
CM_ SG_ 1716 vbus_error "supply voltage outside the limits";
CM_ SG_ 1716 driver_error "reserved; never set by this firmware (STEPFOC does not read a fault output of its driver stage)";
CM_ SG_ 1716 velocity_error "speed above 30,000,000 ticks/s, a fixed threshold (not #Vlimit)";
CM_ SG_ 1716 current_error "reserved; never set by this firmware";
CM_ SG_ 1716 estop_error "Send_ESTOP was received";
CM_ SG_ 1716 calibrated "the motor is calibrated";
CM_ SG_ 1716 activated "the controller is activated";
CM_ SG_ 1716 watchdog_error "the watchdog ran out";
CM_ SG_ 1716 wrong_product "from firmware 109: this firmware is on the other product's board (the product lock) and drives nothing";
CM_ SG_ 1717 error "any error is active";
CM_ SG_ 1717 temperature_error "motor over the temperature limit";
CM_ SG_ 1717 encoder_error "the encoder reports no magnet (too weak a field)";
CM_ SG_ 1717 vbus_error "supply voltage outside the limits";
CM_ SG_ 1717 driver_error "reserved; never set by this firmware (STEPFOC does not read a fault output of its driver stage)";
CM_ SG_ 1717 velocity_error "speed above 30,000,000 ticks/s, a fixed threshold (not #Vlimit)";
CM_ SG_ 1717 current_error "reserved; never set by this firmware";
CM_ SG_ 1717 estop_error "Send_ESTOP was received";
CM_ SG_ 1717 calibrated "the motor is calibrated";
CM_ SG_ 1717 activated "the controller is activated";
CM_ SG_ 1717 watchdog_error "the watchdog ran out";
CM_ SG_ 1717 wrong_product "from firmware 109: this firmware is on the other product's board (the product lock) and drives nothing";
CM_ SG_ 1718 current "mA";
CM_ SG_ 1719 current "mA";
CM_ SG_ 1720 position "encoder ticks";
CM_ SG_ 1720 speed "encoder ticks/s";
CM_ SG_ 1721 position "encoder ticks";
CM_ SG_ 1721 speed "encoder ticks/s";
CM_ SG_ 1730 Kt "Nm/A";
CM_ SG_ 1731 Kt "Nm/A";
CM_ SG_ 1742 product "1 STEPFOC, 2 Spectral Micro: the firmware that answers";
CM_ SG_ 1742 tool_id "parameter 1: 0 none, 1 SSG-48, 11-33 MSG, 200-254 your own";
CM_ SG_ 1742 firmware_version "the release, e.g. 109";
CM_ SG_ 1742 hardware_version "PCB revision from the EEPROM";
CM_ SG_ 1742 pole_pairs "the motor's pole pairs; 0 if outside 0-255";
CM_ SG_ 1742 calibrated "1 calibrated, 0 not";
CM_ SG_ 1742 gripper "the driver is set up as a gripper (#Gripper 1)";
CM_ SG_ 1742 brake_on_idle "idle brakes (1) or coasts (0)";
CM_ SG_ 1742 commutation_reversed "calibration found the coils wired the other way round";
CM_ SG_ 1742 settings_block2 "the EEPROM has the bank settings block 2 lives in, so parameters 1-5 can be saved";
CM_ SG_ 1742 wrong_product "this firmware is on the other product's board (the product lock) and drives nothing";
CM_ SG_ 1742 sense_zero_measured "the current-sense zero was measured at start-up and is plausible";
CM_ SG_ 1742 cogging_saved "the anti-cogging in use is the one saved in the EEPROM";
CM_ SG_ 1742 switching_zero_in_use "the current-sense zero measured with the bridge switching is in use (parameter 46)";
CM_ SG_ 1743 product "1 STEPFOC, 2 Spectral Micro: the firmware that answers";
CM_ SG_ 1743 tool_id "parameter 1: 0 none, 1 SSG-48, 11-33 MSG, 200-254 your own";
CM_ SG_ 1743 firmware_version "the release, e.g. 109";
CM_ SG_ 1743 hardware_version "PCB revision from the EEPROM";
CM_ SG_ 1743 pole_pairs "the motor's pole pairs; 0 if outside 0-255";
CM_ SG_ 1743 calibrated "1 calibrated, 0 not";
CM_ SG_ 1743 gripper "the driver is set up as a gripper (#Gripper 1)";
CM_ SG_ 1743 brake_on_idle "idle brakes (1) or coasts (0)";
CM_ SG_ 1743 commutation_reversed "calibration found the coils wired the other way round";
CM_ SG_ 1743 settings_block2 "the EEPROM has the bank settings block 2 lives in, so parameters 1-5 can be saved";
CM_ SG_ 1743 wrong_product "this firmware is on the other product's board (the product lock) and drives nothing";
CM_ SG_ 1743 sense_zero_measured "the current-sense zero was measured at start-up and is plausible";
CM_ SG_ 1743 cogging_saved "the anti-cogging in use is the one saved in the EEPROM";
CM_ SG_ 1743 switching_zero_in_use "the current-sense zero measured with the bridge switching is in use (parameter 46)";
CM_ SG_ 1744 temperature "\u00b0C (meaningful with the thermistor enabled)";
CM_ SG_ 1744 voltage "supply voltage in mV";
CM_ SG_ 1744 errors_1 "the error flags, as byte 0 of Send_Respond_State_of_Errors";
CM_ SG_ 1744 errors_2 "calibrated, activated, watchdog, wrong product, as byte 1 of Send_Respond_State_of_Errors";
CM_ SG_ 1744 current "Iq in mA";
CM_ SG_ 1745 temperature "\u00b0C (meaningful with the thermistor enabled)";
CM_ SG_ 1745 voltage "supply voltage in mV";
CM_ SG_ 1745 errors_1 "the error flags, as byte 0 of Send_Respond_State_of_Errors";
CM_ SG_ 1745 errors_2 "calibrated, activated, watchdog, wrong product, as byte 1 of Send_Respond_State_of_Errors";
CM_ SG_ 1745 current "Iq in mA";
CM_ SG_ 1686 ID "0 to 13; 14 and 15 are accepted but reserved by the bootloader";
CM_ SG_ 1694 Time "ms; 0 = off";
CM_ SG_ 1694 Action "0 legacy (brake or coast as idle does), 1 hold the position, 2 brake, 3 coast, 4 descend at the fallback current and speed; other values act as 0";
CM_ SG_ 1724 Interval "ms; 0 = off";
CM_ SG_ 1734 Mask "bit 0 = write the idle behaviour";
CM_ SG_ 1734 Value "bit 0: 1 brake, 0 coast";
CM_ SG_ 1736 Parameter "the parameter number, 1-87";
CM_ SG_ 1736 Value "the new value, in the parameter's unit; for the gains, limits and Kt (8-16, 20) a float's bit pattern";
CM_ SG_ 1738 Parameter "the parameter number";
CM_ SG_ 1740 parameter "the parameter number";
CM_ SG_ 1740 value "the value in force; a float's bits for 8-16 and 20";
CM_ SG_ 1741 parameter "the parameter number";
CM_ SG_ 1741 value "the value in force; a float's bits for 8-16 and 20";
CM_ SG_ 1746 Kind "0 capture (up to 1024 samples: parameter 32 says how many), 1 histogram (256 bins), 2 anti-cogging harmonics (8 slots), 3 anti-cogging table (256 values), 4 encoder table (128 values)";
CM_ SG_ 1746 First "the first index";
CM_ SG_ 1746 Count "how many entries; 0 cancels a read-out";
CM_ SG_ 1748 header "kind \u00d7 8192 + index";
CM_ SG_ 1748 word_a "capture: channel A; histogram: the count (unsigned); harmonics: the harmonic number (0 = slot unused); tables: entry index";
CM_ SG_ 1748 word_b "capture: channel B; histogram: the sum's upper 16 bits; harmonics: a, the cosine term in mA; tables: entry index + 1";
CM_ SG_ 1748 word_c "capture: channel C; histogram: the sum's lower 16 bits; harmonics: b, the sine term in mA; tables: entry index + 2 (0 past the end)";
CM_ SG_ 1749 header "kind \u00d7 8192 + index";
CM_ SG_ 1749 word_a "capture: channel A; histogram: the count (unsigned); harmonics: the harmonic number (0 = slot unused); tables: entry index";
CM_ SG_ 1749 word_b "capture: channel B; histogram: the sum's upper 16 bits; harmonics: a, the cosine term in mA; tables: entry index + 1";
CM_ SG_ 1749 word_c "capture: channel C; histogram: the sum's lower 16 bits; harmonics: b, the sine term in mA; tables: entry index + 2 (0 past the end)";
CM_ SG_ 1750 Header "kind \u00d7 8192 + index; kind 2 or 3";
CM_ SG_ 1750 Word_A "kind 2: the harmonic (1-32, 0 = unused); kind 3: value at index";
CM_ SG_ 1750 Word_B "kind 2: a in mA; kind 3: value at index + 1";
CM_ SG_ 1750 Word_C "kind 2: b in mA; kind 3: value at index + 2";
CM_ SG_ 1752 Operation "0 stop everything (tones, queue, samples); 1 a tone now; 2 add an event to the queue; 3 play the queue; 4 play the samples; 5 samples off, buffer cleared; 6 clear the queue (tones that sound keep sounding)";
CM_ SG_ 1752 Channel "the tone channel, 0-3 (operations 1 and 2)";
CM_ SG_ 1752 A "1, 2: the pitch in Hz (2: 0 silences the channel); 4: the sample rate in Hz, at most the loop rate";
CM_ SG_ 1752 B "1, 2: the loudness in mA; 4: the voltage of a full-scale sample in mV";
CM_ SG_ 1752 C "1: the duration in ms, 0 = until stopped; 2: the wait in ms before the next event, 0 = the next one starts with it";
CM_ SG_ 1754 Sample_1 "the next sample";
CM_ SG_ 1786 Position "0 fully open, 255 fully closed";
CM_ SG_ 1786 Speed "0 slowest, 255 fastest";
CM_ SG_ 1786 Current "current limit of the move in mA; from firmware 109 the move uses its magnitude, at most the driver's 2800 mA; see the gripper manual for the safe range";
CM_ SG_ 1786 Activate "1 activate the gripper, 0 deactivate";
CM_ SG_ 1786 Action "1 go to the position, 0 idle";
CM_ SG_ 1786 E_stop "1 raises the gripper E-stop error, again on every control cycle until a frame with this bit 0 arrives; then Send_Clear_Error";
CM_ SG_ 1786 Release_direction "read by the firmware but not used";
CM_ SG_ 1784 gripper_position "0 fully open, 255 fully closed";
CM_ SG_ 1784 gripper_current "measured current in mA";
CM_ SG_ 1784 gripper_activated "1 activated";
CM_ SG_ 1784 gripper_action_status "the action bit of the last Send_gripper_data_pack (1 after #Grippos); the driver never clears it, so it stays 1 after the move ends: the object detection tells when the move has ended";
CM_ SG_ 1784 gripper_object_detection_raw "bit 5 is the low bit, bit 4 the high bit: 0 moving, 1 object detected while closing, 2 object detected while opening, 3 at the position; raw bit pair, see value labels (wire order differs from numeric status)";
CM_ SG_ 1784 gripper_temperature_error "a copy of the thermistor temperature error";
CM_ SG_ 1784 gripper_timeout_error "a copy of the CAN watchdog error (Send_Watchdog), not a move timeout";
CM_ SG_ 1784 gripper_estop_error "the E-stop bit of Send_gripper_data_pack (or #Gripstop 1) was set";
CM_ SG_ 1784 gripper_calibrated "1 calibrated";
CM_ SG_ 1785 gripper_position "0 fully open, 255 fully closed";
CM_ SG_ 1785 gripper_current "measured current in mA";
CM_ SG_ 1785 gripper_activated "1 activated";
CM_ SG_ 1785 gripper_action_status "the action bit of the last Send_gripper_data_pack (1 after #Grippos); the driver never clears it, so it stays 1 after the move ends: the object detection tells when the move has ended";
CM_ SG_ 1785 gripper_object_detection_raw "bit 5 is the low bit, bit 4 the high bit: 0 moving, 1 object detected while closing, 2 object detected while opening, 3 at the position; raw bit pair, see value labels (wire order differs from numeric status)";
CM_ SG_ 1785 gripper_temperature_error "a copy of the thermistor temperature error";
CM_ SG_ 1785 gripper_timeout_error "a copy of the CAN watchdog error (Send_Watchdog), not a move timeout";
CM_ SG_ 1785 gripper_estop_error "the E-stop bit of Send_gripper_data_pack (or #Gripstop 1) was set";
CM_ SG_ 1785 gripper_calibrated "1 calibrated";
SIG_VALTYPE_ 928 KP : 1;
SIG_VALTYPE_ 928 KD : 1;
SIG_VALTYPE_ 930 Kp_iq : 1;
SIG_VALTYPE_ 930 Ki_iq : 1;
SIG_VALTYPE_ 932 Kpv : 1;
SIG_VALTYPE_ 932 Kiv : 1;
SIG_VALTYPE_ 934 Kpp : 1;
SIG_VALTYPE_ 936 Speed_limit : 1;
SIG_VALTYPE_ 936 Current_limit : 1;
SIG_VALTYPE_ 940 Kt : 1;
SIG_VALTYPE_ 962 Kt : 1;
SIG_VALTYPE_ 963 Kt : 1;
SIG_VALTYPE_ 1056 KP : 1;
SIG_VALTYPE_ 1056 KD : 1;
SIG_VALTYPE_ 1058 Kp_iq : 1;
SIG_VALTYPE_ 1058 Ki_iq : 1;
SIG_VALTYPE_ 1060 Kpv : 1;
SIG_VALTYPE_ 1060 Kiv : 1;
SIG_VALTYPE_ 1062 Kpp : 1;
SIG_VALTYPE_ 1064 Speed_limit : 1;
SIG_VALTYPE_ 1064 Current_limit : 1;
SIG_VALTYPE_ 1068 Kt : 1;
SIG_VALTYPE_ 1090 Kt : 1;
SIG_VALTYPE_ 1091 Kt : 1;
SIG_VALTYPE_ 1184 KP : 1;
SIG_VALTYPE_ 1184 KD : 1;
SIG_VALTYPE_ 1186 Kp_iq : 1;
SIG_VALTYPE_ 1186 Ki_iq : 1;
SIG_VALTYPE_ 1188 Kpv : 1;
SIG_VALTYPE_ 1188 Kiv : 1;
SIG_VALTYPE_ 1190 Kpp : 1;
SIG_VALTYPE_ 1192 Speed_limit : 1;
SIG_VALTYPE_ 1192 Current_limit : 1;
SIG_VALTYPE_ 1196 Kt : 1;
SIG_VALTYPE_ 1218 Kt : 1;
SIG_VALTYPE_ 1219 Kt : 1;
SIG_VALTYPE_ 1312 KP : 1;
SIG_VALTYPE_ 1312 KD : 1;
SIG_VALTYPE_ 1314 Kp_iq : 1;
SIG_VALTYPE_ 1314 Ki_iq : 1;
SIG_VALTYPE_ 1316 Kpv : 1;
SIG_VALTYPE_ 1316 Kiv : 1;
SIG_VALTYPE_ 1318 Kpp : 1;
SIG_VALTYPE_ 1320 Speed_limit : 1;
SIG_VALTYPE_ 1320 Current_limit : 1;
SIG_VALTYPE_ 1324 Kt : 1;
SIG_VALTYPE_ 1346 Kt : 1;
SIG_VALTYPE_ 1347 Kt : 1;
SIG_VALTYPE_ 1440 KP : 1;
SIG_VALTYPE_ 1440 KD : 1;
SIG_VALTYPE_ 1442 Kp_iq : 1;
SIG_VALTYPE_ 1442 Ki_iq : 1;
SIG_VALTYPE_ 1444 Kpv : 1;
SIG_VALTYPE_ 1444 Kiv : 1;
SIG_VALTYPE_ 1446 Kpp : 1;
SIG_VALTYPE_ 1448 Speed_limit : 1;
SIG_VALTYPE_ 1448 Current_limit : 1;
SIG_VALTYPE_ 1452 Kt : 1;
SIG_VALTYPE_ 1474 Kt : 1;
SIG_VALTYPE_ 1475 Kt : 1;
SIG_VALTYPE_ 1568 KP : 1;
SIG_VALTYPE_ 1568 KD : 1;
SIG_VALTYPE_ 1570 Kp_iq : 1;
SIG_VALTYPE_ 1570 Ki_iq : 1;
SIG_VALTYPE_ 1572 Kpv : 1;
SIG_VALTYPE_ 1572 Kiv : 1;
SIG_VALTYPE_ 1574 Kpp : 1;
SIG_VALTYPE_ 1576 Speed_limit : 1;
SIG_VALTYPE_ 1576 Current_limit : 1;
SIG_VALTYPE_ 1580 Kt : 1;
SIG_VALTYPE_ 1602 Kt : 1;
SIG_VALTYPE_ 1603 Kt : 1;
SIG_VALTYPE_ 1696 KP : 1;
SIG_VALTYPE_ 1696 KD : 1;
SIG_VALTYPE_ 1698 Kp_iq : 1;
SIG_VALTYPE_ 1698 Ki_iq : 1;
SIG_VALTYPE_ 1700 Kpv : 1;
SIG_VALTYPE_ 1700 Kiv : 1;
SIG_VALTYPE_ 1702 Kpp : 1;
SIG_VALTYPE_ 1704 Speed_limit : 1;
SIG_VALTYPE_ 1704 Current_limit : 1;
SIG_VALTYPE_ 1708 Kt : 1;
SIG_VALTYPE_ 1730 Kt : 1;
SIG_VALTYPE_ 1731 Kt : 1;
VAL_ 1016 gripper_object_detection_raw 0 "moving" 1 "object while opening" 2 "object while closing" 3 "at position";
VAL_ 1017 gripper_object_detection_raw 0 "moving" 1 "object while opening" 2 "object while closing" 3 "at position";
VAL_ 1144 gripper_object_detection_raw 0 "moving" 1 "object while opening" 2 "object while closing" 3 "at position";
VAL_ 1145 gripper_object_detection_raw 0 "moving" 1 "object while opening" 2 "object while closing" 3 "at position";
VAL_ 1272 gripper_object_detection_raw 0 "moving" 1 "object while opening" 2 "object while closing" 3 "at position";
VAL_ 1273 gripper_object_detection_raw 0 "moving" 1 "object while opening" 2 "object while closing" 3 "at position";
VAL_ 1400 gripper_object_detection_raw 0 "moving" 1 "object while opening" 2 "object while closing" 3 "at position";
VAL_ 1401 gripper_object_detection_raw 0 "moving" 1 "object while opening" 2 "object while closing" 3 "at position";
VAL_ 1528 gripper_object_detection_raw 0 "moving" 1 "object while opening" 2 "object while closing" 3 "at position";
VAL_ 1529 gripper_object_detection_raw 0 "moving" 1 "object while opening" 2 "object while closing" 3 "at position";
VAL_ 1656 gripper_object_detection_raw 0 "moving" 1 "object while opening" 2 "object while closing" 3 "at position";
VAL_ 1657 gripper_object_detection_raw 0 "moving" 1 "object while opening" 2 "object while closing" 3 "at position";
VAL_ 1784 gripper_object_detection_raw 0 "moving" 1 "object while opening" 2 "object while closing" 3 "at position";
VAL_ 1785 gripper_object_detection_raw 0 "moving" 1 "object while opening" 2 "object while closing" 3 "at position";
